VERSION ""

NS_ :

BS_:

BU_: VCU_LE CHUD_LE VKM_LE RCRM_LE VPM_LE EDI_LE V2V_LE TCP_LE CSM_LE UHP_Low_LE TouchPad_LE RSE_LE RSC_LE RSA_LE PDIM_LE OTIM_LE ICS_LE LVMPC_LE LVMNav_LE DVB_T_LE ONSTAR_LE HUD_LE IPC_LE RadioHead_LE CHM_LE Dummy_LE CGM_LE AMP_LE

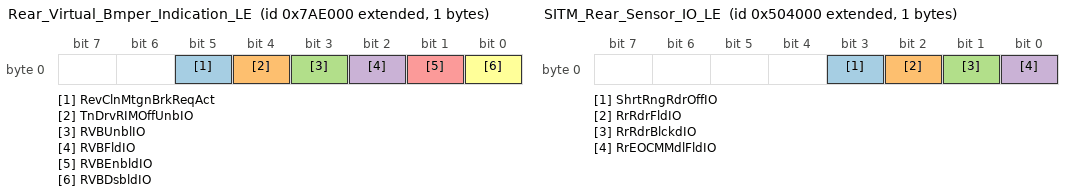
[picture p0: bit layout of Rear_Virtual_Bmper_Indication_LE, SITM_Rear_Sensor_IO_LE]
BO_ 2155536384 Rear_Virtual_Bmper_Indication_LE: 1 CGM_LE
 SG_ RevClnMtgnBrkReqAct : 5|1@0+ (1,0) [0|1] ""  Dummy_LE
 SG_ TnDrvRIMOffUnbIO : 4|1@0+ (1,0) [0|1] ""  VCU_LE,IPC_LE
 SG_ RVBUnblIO : 3|1@0+ (1,0) [0|1] ""  VCU_LE,IPC_LE
 SG_ RVBFldIO : 2|1@0+ (1,0) [0|1] ""  VCU_LE,IPC_LE
 SG_ RVBEnbldIO : 1|1@0+ (1,0) [0|1] ""  VCU_LE,IPC_LE
 SG_ RVBDsbldIO : 0|1@0+ (1,0) [0|1] ""  VCU_LE,IPC_LE

BO_ 2152742912 SITM_Rear_Sensor_IO_LE: 1 CGM_LE
 SG_ ShrtRngRdrOffIO : 3|1@0+ (1,0) [0|1] ""  CSM_LE,RadioHead_LE,VCU_LE,IPC_LE
 SG_ RrRdrFldIO : 2|1@0+ (1,0) [0|1] ""  CSM_LE,RadioHead_LE,VCU_LE,IPC_LE
 SG_ RrRdrBlckdIO : 1|1@0+ (1,0) [0|1] ""  CSM_LE,RadioHead_LE,VCU_LE,IPC_LE
 SG_ RrEOCMMdlFldIO : 0|1@0+ (1,0) [0|1] ""  CSM_LE,RadioHead_LE,VCU_LE,IPC_LE

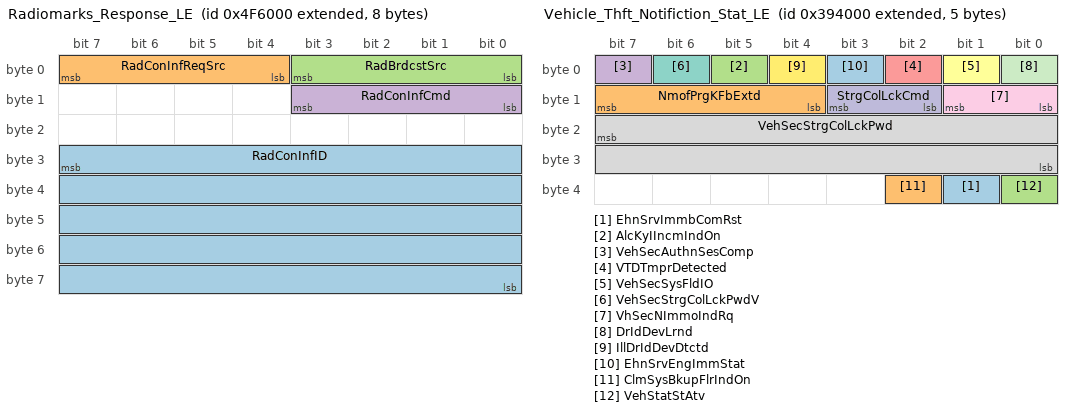
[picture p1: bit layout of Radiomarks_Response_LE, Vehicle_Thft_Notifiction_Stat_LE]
BO_ 2152685568 Radiomarks_Response_LE: 8 RadioHead_LE
 SG_ RadConInfID : 31|40@0+ (1,0) [0|1099511627775] ""  ONSTAR_LE
 SG_ RadConInfReqSrc : 7|4@0+ (1,0) [0|15] ""  ONSTAR_LE
 SG_ RadBrdcstSrc : 3|4@0+ (1,0) [0|15] ""  ONSTAR_LE
 SG_ RadConInfCmd : 11|4@0+ (1,0) [0|15] ""  ONSTAR_LE

BO_ 2151235584 Vehicle_Thft_Notifiction_Stat_LE: 5 CGM_LE
 SG_ EhnSrvImmbComRst : 33|1@0+ (1,0) [0|1] ""  TCP_LE,ONSTAR_LE
 SG_ NmofPrgKFbExtd : 15|4@0+ (1,0) [0|15] ""  VCU_LE,IPC_LE
 SG_ AlcKyIIncmIndOn : 5|1@0+ (1,0) [0|1] ""  Dummy_LE,VCU_LE,IPC_LE
 SG_ VehSecAuthnSesComp : 7|1@0+ (1,0) [0|1] ""  TCP_LE,ONSTAR_LE
 SG_ VTDTmprDetected : 2|1@0+ (1,0) [0|1] ""  TCP_LE,ONSTAR_LE
 SG_ VehSecSysFldIO : 1|1@0+ (1,0) [0|1] ""  VCU_LE,IPC_LE
 SG_ VehSecStrgColLckPwdV : 6|1@0+ (1,0) [0|1] ""  Dummy_LE
 SG_ VehSecStrgColLckPwd : 23|16@0+ (1,0) [0|65535] ""  Dummy_LE
 SG_ VhSecNImmoIndRq : 9|2@0+ (1,0) [0|3] ""  VCU_LE,IPC_LE
 SG_ StrgColLckCmd : 11|2@0+ (1,0) [0|3] ""  Dummy_LE
 SG_ DrIdDevLrnd : 0|1@0+ (1,0) [0|1] ""  TCP_LE,ONSTAR_LE
 SG_ IllDrIdDevDtctd : 4|1@0+ (1,0) [0|1] ""  TCP_LE,ONSTAR_LE
 SG_ EhnSrvEngImmStat : 3|1@0+ (1,0) [0|1] ""  TCP_LE,ONSTAR_LE
 SG_ ClmSysBkupFlrIndOn : 34|1@0+ (1,0) [0|1] ""  VCU_LE,IPC_LE
 SG_ VehStatStAtv : 32|1@0+ (1,0) [0|1] ""  Dummy_LE

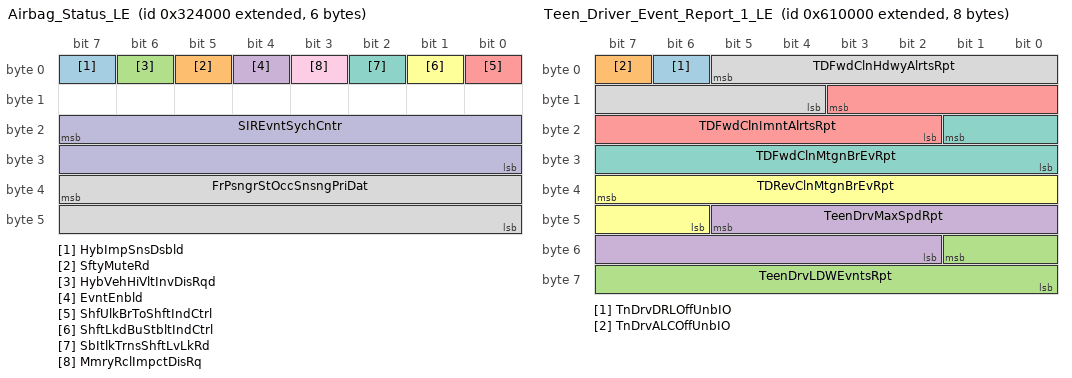
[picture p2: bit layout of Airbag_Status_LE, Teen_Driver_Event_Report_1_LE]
BO_ 2150776832 Airbag_Status_LE: 6 CGM_LE
 SG_ HybImpSnsDsbld : 7|1@0+ (1,0) [0|1] ""  Dummy_LE
 SG_ SftyMuteRd : 5|1@0+ (1,0) [0|1] ""  CSM_LE,VCU_LE,RadioHead_LE
 SG_ HybVehHiVltInvDisRqd : 6|1@0+ (1,0) [0|1] ""  Dummy_LE
 SG_ EvntEnbld : 4|1@0+ (1,0) [0|1] ""  Dummy_LE
 SG_ ShfUlkBrToShftIndCtrl : 0|1@0+ (1,0) [0|1] ""  VCU_LE,IPC_LE
 SG_ ShftLkdBuStbltIndCtrl : 1|1@0+ (1,0) [0|1] ""  VCU_LE,IPC_LE
 SG_ SbItlkTrnsShftLvLkRd : 2|1@0+ (1,0) [0|1] ""  Dummy_LE
 SG_ FrPsngrStOccSnsngPriDat : 39|16@0+ (1,0) [0|39321] ""  Dummy_LE
 SG_ MmryRclImpctDisRq : 3|1@0+ (1,0) [0|1] ""  TCP_LE,Dummy_LE,ONSTAR_LE
 SG_ SIREvntSychCntr : 23|16@0+ (1,0) [0|65535] ""  TCP_LE,ONSTAR_LE

BO_ 2155347968 HS_Indications_Slow_LE: 8 CGM_LE
 SG_ DrvrStPerfMdCsCrStVal : 62|3@0+ (1,0) [0|7] ""  VCU_LE,CSM_LE,RadioHead_LE
 SG_ DrvrStPerfMdCsStAvl : 63|1@0+ (1,0) [0|1] ""  VCU_LE,CSM_LE,RadioHead_LE
 SG_ ACCPerfMdCsCrStVal : 58|3@0+ (1,0) [0|7] ""  VCU_LE,CSM_LE,RadioHead_LE
 SG_ ACCPerfMdCsStAvl : 59|1@0+ (1,0) [0|1] ""  VCU_LE,CSM_LE,RadioHead_LE
 SG_ VehRollAngleV : 55|1@0+ (1,0) [0|1] ""  VCU_LE,IPC_LE
 SG_ VehRollAngle : 54|7@0+ (0.703125,-45) [-45|44.296875] "deg"  VCU_LE,IPC_LE
 SG_ ActVbnCtrlMlfIO : 0|1@0+ (1,0) [0|1] ""  VCU_LE,IPC_LE
 SG_ HillDesCtrlRedVehSpIO : 47|1@0+ (1,0) [0|1] ""  VCU_LE,IPC_LE
 SG_ FourWhlDrvIndReq : 42|3@0+ (1,0) [0|7] ""  CSM_LE,VCU_LE,IPC_LE
 SG_ PedtrnProtVDA : 35|1@0+ (1,0) [0|1] ""  CSM_LE,IPC_LE,VCU_LE,RadioHead_LE
 SG_ EngRecDwnshftIO : 43|1@0+ (1,0) [0|1] ""  CSM_LE,RadioHead_LE,VCU_LE,IPC_LE
 SG_ AppCltchAutSrtIO : 36|1@0+ (1,0) [0|1] ""  CSM_LE,RadioHead_LE,VCU_LE,IPC_LE
 SG_ CPSUnblIO : 32|1@0+ (1,0) [0|1] ""  CSM_LE,RadioHead_LE,VCU_LE,IPC_LE
 SG_ StBltTgtSetAvl : 37|1@0+ (1,0) [0|1] ""  CSM_LE,VCU_LE,RadioHead_LE
 SG_ StBltTgtCrtSetVal : 46|3@0+ (1,0) [0|7] ""  CSM_LE,VCU_LE,RadioHead_LE
 SG_ PedtrnProtSysDisbld : 34|1@0+ (1,0) [0|1] ""  CSM_LE,IPC_LE,VCU_LE,RadioHead_LE
 SG_ PedtrnProtSysDpl : 1|1@0+ (1,0) [0|1] ""  CSM_LE,IPC_LE,VCU_LE,RadioHead_LE
 SG_ SrvPedtrnProtSysIO : 33|1@0+ (1,0) [0|1] ""  CSM_LE,IPC_LE,VCU_LE,RadioHead_LE
 SG_ CPSOffIO : 31|1@0+ (1,0) [0|1] ""  CSM_LE,RadioHead_LE,VCU_LE,IPC_LE
 SG_ SecAxlTmpInhIO : 24|1@0+ (1,0) [0|1] ""  CSM_LE,RadioHead_LE,VCU_LE,IPC_LE
 SG_ CPSFldIO : 30|1@0+ (1,0) [0|1] ""  CSM_LE,RadioHead_LE,VCU_LE,IPC_LE
 SG_ CPSAlrtOnlIO : 25|1@0+ (1,0) [0|1] ""  CSM_LE,RadioHead_LE,VCU_LE,IPC_LE
 SG_ RrAxlTmpInhIO : 23|1@0+ (1,0) [0|1] ""  CSM_LE,RadioHead_LE,VCU_LE,IPC_LE
 SG_ TirePrsLowIO : 2|1@0+ (1,0) [0|1] ""  CSM_LE,RadioHead_LE,VCU_LE,IPC_LE
 SG_ EPBSysStatIndReq : 27|2@0+ (1,0) [0|3] ""  CSM_LE,RadioHead_LE,VCU_LE,IPC_LE
 SG_ EngOilStrvtnIO : 5|1@0+ (1,0) [0|1] ""  CSM_LE,RadioHead_LE,VCU_LE,IPC_LE
 SG_ SrvSuspSysIO : 12|1@0+ (1,0) [0|1] ""  CSM_LE,RadioHead_LE,VCU_LE,IPC_LE
 SG_ ServAdpCrsCtrlIndOn : 11|1@0+ (1,0) [0|1] ""  CSM_LE,TCP_LE,ONSTAR_LE,RadioHead_LE,VCU_LE,IPC_LE
 SG_ EngRecmndUpshftIO : 10|1@0+ (1,0) [0|1] ""  CSM_LE,RadioHead_LE,VCU_LE,IPC_LE
 SG_ BrkSysMalFuncIndOn : 15|1@0+ (1,0) [0|1] ""  CSM_LE,RadioHead_LE,VCU_LE,IPC_LE
 SG_ SecAxlNonEmMalfIO : 6|1@0+ (1,0) [0|1] ""  CSM_LE,RadioHead_LE,VCU_LE,IPC_LE
 SG_ BrkFldLvlLw : 7|1@0+ (1,0) [0|1] ""  CSM_LE,TCP_LE,ONSTAR_LE,RadioHead_LE,VCU_LE,IPC_LE
 SG_ ACCUnavlbleDTWthrIO : 3|1@0+ (1,0) [0|1] ""  CSM_LE,RadioHead_LE,VCU_LE,IPC_LE
 SG_ ACCTmpUnavlbleIO : 9|1@0+ (1,0) [0|1] ""  CSM_LE,RadioHead_LE,VCU_LE,IPC_LE
 SG_ EngEmsRelMalfIndReq : 18|3@0+ (1,0) [0|7] ""  CSM_LE,RadioHead_LE,VCU_LE,IPC_LE
 SG_ DrShftCntrlReqDndIO : 20|1@0+ (1,0) [0|1] ""  CSM_LE,RadioHead_LE,VCU_LE,IPC_LE
 SG_ BrkPadWrnIO : 13|1@0+ (1,0) [0|1] ""  CSM_LE,TCP_LE,ONSTAR_LE,RadioHead_LE,VCU_LE,IPC_LE
 SG_ RrAxlMalfIO : 19|1@0+ (1,0) [0|1] ""  CSM_LE,RadioHead_LE,VCU_LE,IPC_LE
 SG_ EPBSysWrnIndReq : 29|2@0+ (1,0) [0|3] ""  CSM_LE,RadioHead_LE,VCU_LE,IPC_LE
 SG_ CompOvrhtIndOn : 21|1@0+ (1,0) [0|1] ""  CSM_LE,RadioHead_LE,VCU_LE,IPC_LE
 SG_ BrkFldLvlLwV : 4|1@0+ (1,0) [0|1] ""  CSM_LE,TCP_LE,ONSTAR_LE,RadioHead_LE,VCU_LE,IPC_LE
 SG_ ACCSnsClnRqdIO : 8|1@0+ (1,0) [0|1] ""  CSM_LE,RadioHead_LE,VCU_LE,IPC_LE
 SG_ TrnsSkpShftIO : 22|1@0+ (1,0) [0|1] ""  CSM_LE,RadioHead_LE,VCU_LE,IPC_LE

BO_ 2155585536 MSB_Customization_Setting_Req_LE: 1 RadioHead_LE
 SG_ StBltTgtCSRq : 2|3@0+ (1,0) [0|7] ""  CGM_LE

BO_ 2159173632 ODI_IPC_2_CenterStack_LE: 8 IPC_LE
 SG_ ODI_IPC2CntrStck : 7|64@0+ (1,0) [0|1.84467440737096E+019] ""  CSM_LE,VCU_LE,RadioHead_LE

BO_ 2159165440 ODI_CenterStack_2_IPC_LE: 8 RadioHead_LE
 SG_ ODI_CntrStck2IPC : 7|64@0+ (1,0) [0|1.84467440737096E+019] ""  VCU_LE,IPC_LE

BO_ 2153840640 Teen_Driver_Event_Report_1_LE: 8 CGM_LE
 SG_ TnDrvDRLOffUnbIO : 6|1@0+ (1,0) [0|1] ""  VCU_LE,IPC_LE
 SG_ TnDrvALCOffUnbIO : 7|1@0+ (1,0) [0|1] ""  VCU_LE,IPC_LE
 SG_ TeenDrvLDWEvntsRpt : 49|10@0+ (1,0) [0|1023] "counts"  VCU_LE,CSM_LE,RadioHead_LE
 SG_ TeenDrvMaxSpdRpt : 45|12@0+ (0.0625,0) [0|255.9375] "km/h"  VCU_LE,CSM_LE,RadioHead_LE
 SG_ TDFwdClnImntAlrtsRpt : 11|10@0+ (1,0) [0|1023] "counts"  VCU_LE,CSM_LE,RadioHead_LE
 SG_ TDRevClnMtgnBrEvRpt : 39|10@0+ (1,0) [0|1023] "counts"  VCU_LE,CSM_LE,RadioHead_LE
 SG_ TDFwdClnMtgnBrEvRpt : 17|10@0+ (1,0) [0|1023] "counts"  VCU_LE,CSM_LE,RadioHead_LE
 SG_ TDFwdClnHdwyAlrtsRpt : 5|10@0+ (1,0) [0|1023] "counts"  VCU_LE,CSM_LE,RadioHead_LE

BO_ 2154094592 Adjustable_Pedal_Motion_Inh_LE: 8 CGM_LE
 SG_ IntDimSeldClrTypStVal : 12|5@0+ (1,0) [0|31] ""  VCU_LE,CSM_LE,RadioHead_LE
 SG_ IntDimSeldAnmTypStVal : 4|4@0+ (1,0) [0|15] ""  VCU_LE,CSM_LE,RadioHead_LE
 SG_ IDCTA_ClrTyp30Avl : 56|1@0+ (1,0) [0|1] ""  VCU_LE,CSM_LE,RadioHead_LE
 SG_ IDCTA_ClrTyp29Avl : 57|1@0+ (1,0) [0|1] ""  VCU_LE,CSM_LE,RadioHead_LE
 SG_ IDCTA_ClrTyp28Avl : 58|1@0+ (1,0) [0|1] ""  VCU_LE,CSM_LE,RadioHead_LE
 SG_ IDCTA_ClrTyp27Avl : 59|1@0+ (1,0) [0|1] ""  VCU_LE,CSM_LE,RadioHead_LE
 SG_ IDCTA_ClrTyp26Avl : 60|1@0+ (1,0) [0|1] ""  VCU_LE,CSM_LE,RadioHead_LE
 SG_ IDCTA_ClrTyp25Avl : 61|1@0+ (1,0) [0|1] ""  VCU_LE,CSM_LE,RadioHead_LE
 SG_ IDCTA_ClrTyp24Avl : 62|1@0+ (1,0) [0|1] ""  VCU_LE,CSM_LE,RadioHead_LE
 SG_ IDCTA_ClrTyp23Avl : 63|1@0+ (1,0) [0|1] ""  VCU_LE,CSM_LE,RadioHead_LE
 SG_ IDCTA_ClrTyp22Avl : 48|1@0+ (1,0) [0|1] ""  VCU_LE,CSM_LE,RadioHead_LE
 SG_ IDCTA_ClrTyp21Avl : 49|1@0+ (1,0) [0|1] ""  VCU_LE,CSM_LE,RadioHead_LE
 SG_ IDCTA_ClrTyp20Avl : 50|1@0+ (1,0) [0|1] ""  VCU_LE,CSM_LE,RadioHead_LE
 SG_ IDCTA_ClrTyp19Avl : 51|1@0+ (1,0) [0|1] ""  VCU_LE,CSM_LE,RadioHead_LE
 SG_ IDCTA_ClrTyp18Avl : 52|1@0+ (1,0) [0|1] ""  VCU_LE,CSM_LE,RadioHead_LE
 SG_ IDCTA_ClrTyp17Avl : 53|1@0+ (1,0) [0|1] ""  VCU_LE,CSM_LE,RadioHead_LE
 SG_ IDCTA_ClrTyp16Avl : 54|1@0+ (1,0) [0|1] ""  VCU_LE,CSM_LE,RadioHead_LE
 SG_ IDCTA_ClrTyp15Avl : 55|1@0+ (1,0) [0|1] ""  VCU_LE,CSM_LE,RadioHead_LE
 SG_ IDCTA_ClrTyp14Avl : 40|1@0+ (1,0) [0|1] ""  VCU_LE,CSM_LE,RadioHead_LE
 SG_ IDCTA_ClrTyp13Avl : 41|1@0+ (1,0) [0|1] ""  VCU_LE,CSM_LE,RadioHead_LE
 SG_ IDCTA_ClrTyp12Avl : 42|1@0+ (1,0) [0|1] ""  VCU_LE,CSM_LE,RadioHead_LE
 SG_ IDCTA_ClrTyp11Avl : 43|1@0+ (1,0) [0|1] ""  VCU_LE,CSM_LE,RadioHead_LE
 SG_ IDCTA_ClrTyp10Avl : 44|1@0+ (1,0) [0|1] ""  VCU_LE,CSM_LE,RadioHead_LE
 SG_ IDCTA_ClrTyp9Avl : 45|1@0+ (1,0) [0|1] ""  VCU_LE,CSM_LE,RadioHead_LE
 SG_ IDCTA_ClrTyp8Avl : 46|1@0+ (1,0) [0|1] ""  VCU_LE,CSM_LE,RadioHead_LE
 SG_ IDCTA_ClrTyp7Avl : 47|1@0+ (1,0) [0|1] ""  VCU_LE,CSM_LE,RadioHead_LE
 SG_ IDCTA_ClrTyp6Avl : 32|1@0+ (1,0) [0|1] ""  VCU_LE,CSM_LE,RadioHead_LE
 SG_ IDCTA_ClrTyp5Avl : 33|1@0+ (1,0) [0|1] ""  VCU_LE,CSM_LE,RadioHead_LE
 SG_ IDCTA_ClrTyp4Avl : 34|1@0+ (1,0) [0|1] ""  VCU_LE,CSM_LE,RadioHead_LE
 SG_ IDCTA_ClrTyp3Avl : 35|1@0+ (1,0) [0|1] ""  VCU_LE,CSM_LE,RadioHead_LE
 SG_ IDCTA_ClrTyp2Avl : 36|1@0+ (1,0) [0|1] ""  VCU_LE,CSM_LE,RadioHead_LE
 SG_ IDCTA_ClrTyp1Avl : 37|1@0+ (1,0) [0|1] ""  VCU_LE,CSM_LE,RadioHead_LE
 SG_ IDCTA_OffAvl : 38|1@0+ (1,0) [0|1] ""  VCU_LE,CSM_LE,RadioHead_LE
 SG_ IDATA_AnmTyp14Avl : 24|1@0+ (1,0) [0|1] ""  VCU_LE,CSM_LE,RadioHead_LE
 SG_ IDATA_AnmTyp13Avl : 25|1@0+ (1,0) [0|1] ""  VCU_LE,CSM_LE,RadioHead_LE
 SG_ IDATA_AnmTyp12Avl : 26|1@0+ (1,0) [0|1] ""  VCU_LE,CSM_LE,RadioHead_LE
 SG_ IDATA_AnmTyp11Avl : 27|1@0+ (1,0) [0|1] ""  VCU_LE,CSM_LE,RadioHead_LE
 SG_ IDATA_AnmTyp10Avl : 28|1@0+ (1,0) [0|1] ""  VCU_LE,CSM_LE,RadioHead_LE
 SG_ IDATA_AnmTyp9Avl : 29|1@0+ (1,0) [0|1] ""  VCU_LE,CSM_LE,RadioHead_LE
 SG_ IDATA_AnmTyp8Avl : 30|1@0+ (1,0) [0|1] ""  VCU_LE,CSM_LE,RadioHead_LE
 SG_ IDATA_AnmTyp7Avl : 31|1@0+ (1,0) [0|1] ""  VCU_LE,CSM_LE,RadioHead_LE
 SG_ IDATA_AnmTyp6Avl : 16|1@0+ (1,0) [0|1] ""  VCU_LE,CSM_LE,RadioHead_LE
 SG_ IDATA_AnmTyp5Avl : 17|1@0+ (1,0) [0|1] ""  VCU_LE,CSM_LE,RadioHead_LE
 SG_ IDATA_AnmTyp4Avl : 18|1@0+ (1,0) [0|1] ""  VCU_LE,CSM_LE,RadioHead_LE
 SG_ IDATA_AnmTyp3Avl : 19|1@0+ (1,0) [0|1] ""  VCU_LE,CSM_LE,RadioHead_LE
 SG_ IDATA_AnmTyp2Avl : 20|1@0+ (1,0) [0|1] ""  VCU_LE,CSM_LE,RadioHead_LE
 SG_ IDATA_AnmTyp1Avl : 21|1@0+ (1,0) [0|1] ""  VCU_LE,CSM_LE,RadioHead_LE
 SG_ IDATA_OffAvl : 22|1@0+ (1,0) [0|1] ""  VCU_LE,CSM_LE,RadioHead_LE
 SG_ AdjPdlMotInhbtd : 0|1@0+ (1,0) [0|1] ""  Dummy_LE

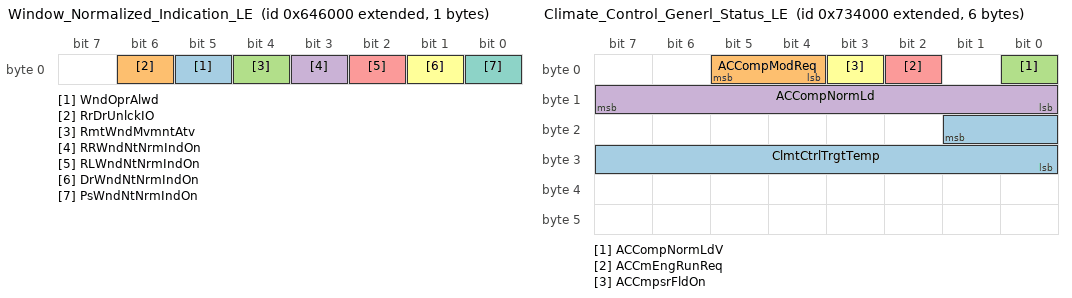
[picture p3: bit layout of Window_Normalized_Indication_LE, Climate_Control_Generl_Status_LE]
BO_ 2154061824 Window_Normalized_Indication_LE: 1 CGM_LE
 SG_ WndOprAlwd : 5|1@0+ (1,0) [0|1] ""  Dummy_LE
 SG_ RrDrUnlckIO : 6|1@0+ (1,0) [0|1] ""  VCU_LE,IPC_LE
 SG_ RmtWndMvmntAtv : 4|1@0+ (1,0) [0|1] ""  Dummy_LE
 SG_ RRWndNtNrmIndOn : 3|1@0+ (1,0) [0|1] ""  VCU_LE,IPC_LE
 SG_ RLWndNtNrmIndOn : 2|1@0+ (1,0) [0|1] ""  VCU_LE,IPC_LE
 SG_ DrWndNtNrmIndOn : 1|1@0+ (1,0) [0|1] ""  VCU_LE,IPC_LE
 SG_ PsWndNtNrmIndOn : 0|1@0+ (1,0) [0|1] ""  VCU_LE,IPC_LE

BO_ 2155036672 Climate_Control_Generl_Status_LE: 6 CGM_LE
 SG_ ClmtCtrlTrgtTemp : 17|10@0+ (0.1,-10) [-10|92.3] "deg C"  CSM_LE,Dummy_LE
 SG_ ACCompModReq : 5|2@0+ (1,0) [0|3] ""  Dummy_LE
 SG_ ACCompNormLdV : 0|1@0+ (1,0) [0|1] ""  VCU_LE,CSM_LE,RadioHead_LE
 SG_ ACCompNormLd : 15|8@0+ (0.1,0) [0|25.5] "l/min"  VCU_LE,CSM_LE,RadioHead_LE
 SG_ ACCmEngRunReq : 2|1@0+ (1,0) [0|1] ""  Dummy_LE
 SG_ ACCmpsrFldOn : 3|1@0+ (1,0) [0|1] ""  Dummy_LE

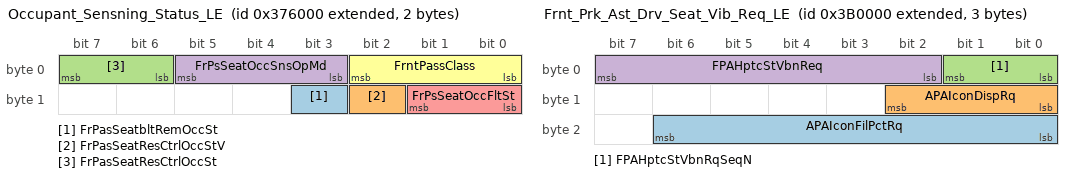
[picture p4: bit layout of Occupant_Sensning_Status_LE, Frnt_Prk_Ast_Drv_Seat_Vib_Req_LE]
BO_ 2151112704 Occupant_Sensning_Status_LE: 2 CGM_LE
 SG_ FrPasSeatbltRemOccSt : 11|1@0+ (1,0) [0|1] ""  CSM_LE,VCU_LE,RadioHead_LE
 SG_ FrPasSeatResCtrlOccStV : 10|1@0+ (1,0) [0|1] ""  CSM_LE,VCU_LE,RadioHead_LE
 SG_ FrPasSeatResCtrlOccSt : 7|2@0+ (1,0) [0|3] ""  CSM_LE,VCU_LE,RadioHead_LE
 SG_ FrPsSeatOccSnsOpMd : 5|3@0+ (1,0) [0|7] "N/A"  Dummy_LE
 SG_ FrPsSeatOccFltSt : 9|2@0+ (1,0) [0|3] "N/A"  CSM_LE,VCU_LE,RadioHead_LE
 SG_ FrntPassClass : 2|3@0+ (1,0) [0|7] ""  CSM_LE,VCU_LE,RadioHead_LE

BO_ 2150301696 HMI_Animation_Initiator_LE: 1 CGM_LE
 SG_ WlcAnmReq : 0|1@0+ (1,0) [0|1] ""  IPC_LE,VCU_LE,RadioHead_LE

BO_ 2158895104 ODI_CenterStack_2_RearSeat_LE: 8 RadioHead_LE
 SG_ ODI_CntrStck2RSD : 7|64@0+ (1,0) [0|1.84467440737096E+019] ""  RSC_LE,RSA_LE

BO_ 2151350272 Frnt_Prk_Ast_Drv_Seat_Vib_Req_LE: 3 CGM_LE
 SG_ APAIconFilPctRq : 22|7@0+ (1,0) [0|127] ""  VCU_LE,CSM_LE,RadioHead_LE,VPM_LE
 SG_ APAIconDispRq : 10|3@0+ (1,0) [0|7] ""  VCU_LE,CSM_LE,RadioHead_LE,VPM_LE
 SG_ FPAHptcStVbnRqSeqN : 1|2@0+ (1,0) [0|3] ""  Dummy_LE
 SG_ FPAHptcStVbnReq : 7|6@0+ (1,0) [0|63] ""  Dummy_LE

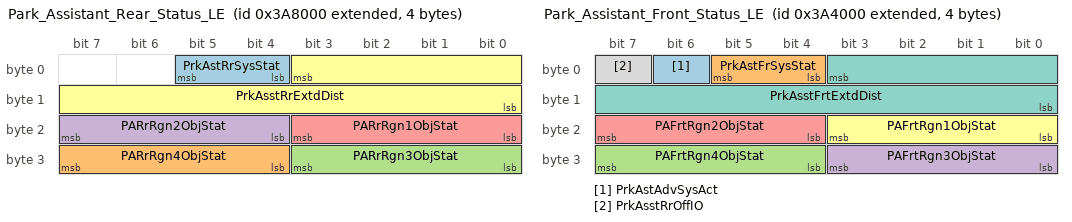
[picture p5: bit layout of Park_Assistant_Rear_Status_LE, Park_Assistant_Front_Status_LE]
BO_ 2151317504 Park_Assistant_Rear_Status_LE: 4 CGM_LE
 SG_ PrkAstRrSysStat : 5|2@0+ (1,0) [0|3] ""  TCP_LE,VPM_LE,ONSTAR_LE,CSM_LE,RadioHead_LE,VCU_LE,IPC_LE
 SG_ PARrRgn4ObjStat : 31|4@0+ (1,0) [0|15] ""  VPM_LE,CSM_LE,RadioHead_LE,VCU_LE,IPC_LE
 SG_ PARrRgn3ObjStat : 27|4@0+ (1,0) [0|15] ""  VPM_LE,CSM_LE,RadioHead_LE,VCU_LE,IPC_LE
 SG_ PARrRgn2ObjStat : 23|4@0+ (1,0) [0|15] ""  VPM_LE,CSM_LE,RadioHead_LE,VCU_LE,IPC_LE
 SG_ PARrRgn1ObjStat : 19|4@0+ (1,0) [0|15] ""  VPM_LE,CSM_LE,RadioHead_LE,VCU_LE,IPC_LE
 SG_ PrkAsstRrExtdDist : 3|12@0+ (0.01,0) [0|40.95] "m"  CSM_LE,RadioHead_LE,VCU_LE,IPC_LE

BO_ 2151301120 Park_Assistant_Front_Status_LE: 4 CGM_LE
 SG_ PrkAstAdvSysAct : 6|1@0+ (1,0) [0|1] ""  Dummy_LE
 SG_ PrkAstFrSysStat : 5|2@0+ (1,0) [0|3] ""  TCP_LE,ONSTAR_LE,CSM_LE,RadioHead_LE,VCU_LE,IPC_LE
 SG_ PAFrtRgn4ObjStat : 31|4@0+ (1,0) [0|15] ""  CSM_LE,RadioHead_LE,VCU_LE,IPC_LE
 SG_ PAFrtRgn3ObjStat : 27|4@0+ (1,0) [0|15] ""  CSM_LE,RadioHead_LE,VCU_LE,IPC_LE
 SG_ PAFrtRgn2ObjStat : 23|4@0+ (1,0) [0|15] ""  CSM_LE,RadioHead_LE,VCU_LE,IPC_LE
 SG_ PAFrtRgn1ObjStat : 19|4@0+ (1,0) [0|15] ""  CSM_LE,RadioHead_LE,VCU_LE,IPC_LE
 SG_ PrkAsstFrtExtdDist : 3|12@0+ (0.01,0) [0|40.95] "m"  VPM_LE,CSM_LE,RadioHead_LE,VCU_LE,IPC_LE
 SG_ PrkAsstRrOffIO : 7|1@0+ (1,0) [0|1] ""  VCU_LE,IPC_LE

BO_ 2152775680 Front_360_Camera_On_LE: 8 VPM_LE
 SG_ CrgBdVwLtCustSetAvl : 54|1@0+ (1,0) [0|1] ""  CGM_LE,VCU_LE,CSM_LE,RadioHead_LE
 SG_ TrlrMirVGlnCustSetVal : 51|2@0+ (1,0) [0|3] ""  CGM_LE,VCU_LE,CSM_LE,RadioHead_LE
 SG_ TrlrMirVGlnCustSetAvl : 55|1@0+ (1,0) [0|1] ""  CGM_LE,VCU_LE,CSM_LE,RadioHead_LE
 SG_ TrlrMirVEnCustSetVal : 30|2@0+ (1,0) [0|3] ""  CGM_LE,VCU_LE,CSM_LE,RadioHead_LE
 SG_ TrlrMirVEnCustSetAvl : 31|1@0+ (1,0) [0|1] ""  CGM_LE,VCU_LE,CSM_LE,RadioHead_LE
 SG_ TrlrArtcltnAnglCalStat : 62|2@0+ (1,0) [0|3] ""  VCU_LE,CSM_LE,RadioHead_LE,CGM_LE
 SG_ InvTrlrAx1CamRollAlgnd : 57|1@0+ (1,0) [0|1] ""  VCU_LE,CSM_LE,RadioHead_LE,CGM_LE
 SG_ InvTrlrAx1CamPtchAlgnd : 58|1@0+ (1,0) [0|1] ""  VCU_LE,CSM_LE,RadioHead_LE,CGM_LE
 SG_ InvTrlrAx1CamYAlgnd : 59|1@0+ (1,0) [0|1] ""  VCU_LE,CSM_LE,RadioHead_LE,CGM_LE
 SG_ InvTrlrAx1CamXAlgnd : 60|1@0+ (1,0) [0|1] ""  VCU_LE,CSM_LE,RadioHead_LE,CGM_LE
 SG_ RPDCA_Resrv3Avail : 17|1@0+ (1,0) [0|1] ""  VCU_LE,CSM_LE,RadioHead_LE,CGM_LE
 SG_ RPDCA_Resrv2Avail : 18|1@0+ (1,0) [0|1] ""  VCU_LE,CSM_LE,RadioHead_LE,CGM_LE
 SG_ RPDCA_Resrv1Avail : 19|1@0+ (1,0) [0|1] ""  VCU_LE,CSM_LE,RadioHead_LE,CGM_LE
 SG_ RPDCA_AlrtBrkAvail : 20|1@0+ (1,0) [0|1] ""  VCU_LE,CSM_LE,RadioHead_LE,CGM_LE
 SG_ RPDCA_AlrtAvail : 21|1@0+ (1,0) [0|1] ""  VCU_LE,CSM_LE,RadioHead_LE,CGM_LE
 SG_ RPDCA_OnAvail : 22|1@0+ (1,0) [0|1] ""  VCU_LE,CSM_LE,RadioHead_LE,CGM_LE
 SG_ RPDCA_OfAvail : 23|1@0+ (1,0) [0|1] ""  VCU_LE,CSM_LE,RadioHead_LE,CGM_LE
 SG_ JacknfDetRHapSReqSN : 47|2@0+ (1,0) [0|3] ""  CGM_LE
 SG_ JacknfDetRHapSReq : 45|6@0+ (1,0) [0|63] ""  CGM_LE
 SG_ JacknfDetLHapSReqSN : 39|2@0+ (1,0) [0|3] ""  CGM_LE
 SG_ JacknfDetLHapSReq : 37|6@0+ (1,0) [0|63] ""  CGM_LE
 SG_ JacknfDetCustSetVal : 53|2@0+ (1,0) [0|3] ""  CGM_LE,VCU_LE,CSM_LE,RadioHead_LE
 SG_ JacknfDetCustSetAvl : 63|1@0+ (1,0) [0|1] ""  CGM_LE,VCU_LE,CSM_LE,RadioHead_LE
 SG_ CrgBdVwLtCustSetVal : 49|2@0+ (1,0) [0|3] ""  CGM_LE,VCU_LE,CSM_LE,RadioHead_LE
 SG_ DispTrgdVidOn : 14|1@0+ (1,0) [0|1] ""  CGM_LE,VCU_LE,CSM_LE,RadioHead_LE
 SG_ a_360DegVidFetrPrsnt : 15|1@0+ (1,0) [0|1] ""  CGM_LE,VCU_LE,CSM_LE,RadioHead_LE
 SG_ TrgdVidRecFetrPrsnt : 7|1@0+ (1,0) [0|1] ""  VCU_LE,CSM_LE,RadioHead_LE,CGM_LE
 SG_ RrPdDetHptcStVbRq : 13|6@0+ (1,0) [0|63] "Pulse"  CGM_LE,Dummy_LE
 SG_ RrPdDetHptcStVbRqSeqN : 6|2@0+ (1,0) [0|3] ""  CGM_LE,Dummy_LE
 SG_ RrPedDetCstStAvl : 1|1@0+ (1,0) [0|1] ""  CGM_LE,VCU_LE,CSM_LE,RadioHead_LE
 SG_ RrPedDetCstStVal : 4|3@0+ (1,0) [0|7] ""  CGM_LE,VCU_LE,CSM_LE,RadioHead_LE
 SG_ DispFrt360CamOn : 0|1@0+ (1,0) [0|1] ""  CGM_LE,VCU_LE,CSM_LE,RadioHead_LE
 SG_ SurdVwLightgCsSetAvail : 27|1@0+ (1,0) [0|1] ""  CGM_LE,VCU_LE,CSM_LE,RadioHead_LE
 SG_ SurdVwLightgCsCurrSetVal : 26|3@0+ (1,0) [0|7] ""  CGM_LE,VCU_LE,CSM_LE,RadioHead_LE
 SG_ PudlLmpReqstd : 28|1@0+ (1,0) [0|1] ""  CGM_LE
 SG_ DispSmrtTwVidOn : 16|1@0+ (1,0) [0|1] ""  VCU_LE,CSM_LE,RadioHead_LE,CGM_LE

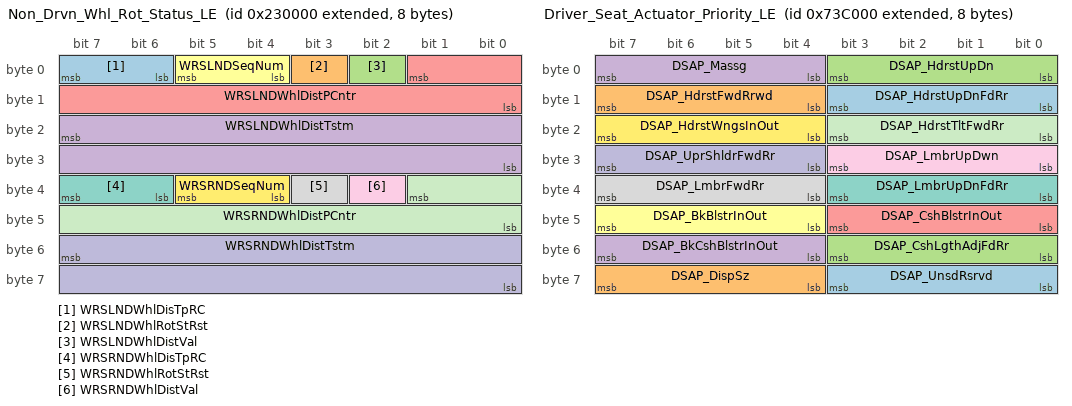
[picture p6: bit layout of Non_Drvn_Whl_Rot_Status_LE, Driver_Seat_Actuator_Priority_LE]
BO_ 2149777408 Non_Drvn_Whl_Rot_Status_LE: 8 CGM_LE
 SG_ WRSLNDWhlDisTpRC : 7|2@0+ (1,0) [0|3] "counts"  VPM_LE,VCU_LE,CSM_LE,RadioHead_LE
 SG_ WRSLNDWhlRotStRst : 3|1@0+ (1,0) [0|1] ""  VPM_LE,VCU_LE,CSM_LE,RadioHead_LE
 SG_ WRSLNDWhlDistVal : 2|1@0+ (1,0) [0|1] ""  VPM_LE,VCU_LE,CSM_LE,RadioHead_LE
 SG_ WRSLNDWhlDistTstm : 23|16@0+ (1,0) [0|65535] "counts"  VPM_LE,VCU_LE,CSM_LE,RadioHead_LE
 SG_ WRSLNDWhlDistPCntr : 1|10@0+ (1,0) [0|1023] "counts"  VPM_LE,VCU_LE,CSM_LE,RadioHead_LE
 SG_ WRSLNDSeqNum : 5|2@0+ (1,0) [0|3] "counts"  VPM_LE,VCU_LE,CSM_LE,RadioHead_LE
 SG_ WRSRNDWhlDisTpRC : 39|2@0+ (1,0) [0|3] "counts"  VPM_LE,VCU_LE,CSM_LE,RadioHead_LE
 SG_ WRSRNDWhlRotStRst : 35|1@0+ (1,0) [0|1] ""  VPM_LE,VCU_LE,CSM_LE,RadioHead_LE
 SG_ WRSRNDWhlDistVal : 34|1@0+ (1,0) [0|1] ""  VPM_LE,VCU_LE,CSM_LE,RadioHead_LE
 SG_ WRSRNDWhlDistTstm : 55|16@0+ (1,0) [0|65535] "counts"  VPM_LE,VCU_LE,CSM_LE,RadioHead_LE
 SG_ WRSRNDWhlDistPCntr : 33|10@0+ (1,0) [0|1023] "counts"  VPM_LE,VCU_LE,CSM_LE,RadioHead_LE
 SG_ WRSRNDSeqNum : 37|2@0+ (1,0) [0|3] "counts"  VPM_LE,VCU_LE,CSM_LE,RadioHead_LE

BO_ 2155069440 Driver_Seat_Actuator_Priority_LE: 8 CGM_LE
 SG_ DSAP_UnsdRsrvd : 59|4@0+ (1,0) [0|15] ""  VCU_LE,CSM_LE,RadioHead_LE
 SG_ DSAP_DispSz : 63|4@0+ (1,0) [0|15] ""  VCU_LE,CSM_LE,RadioHead_LE
 SG_ DSAP_CshLgthAdjFdRr : 51|4@0+ (1,0) [0|15] ""  VCU_LE,CSM_LE,RadioHead_LE
 SG_ DSAP_BkCshBlstrInOut : 55|4@0+ (1,0) [0|15] ""  VCU_LE,CSM_LE,RadioHead_LE
 SG_ DSAP_CshBlstrInOut : 43|4@0+ (1,0) [0|15] ""  VCU_LE,CSM_LE,RadioHead_LE
 SG_ DSAP_BkBlstrInOut : 47|4@0+ (1,0) [0|15] ""  VCU_LE,CSM_LE,RadioHead_LE
 SG_ DSAP_LmbrUpDnFdRr : 35|4@0+ (1,0) [0|15] ""  VCU_LE,CSM_LE,RadioHead_LE
 SG_ DSAP_LmbrFwdRr : 39|4@0+ (1,0) [0|15] ""  VCU_LE,CSM_LE,RadioHead_LE
 SG_ DSAP_LmbrUpDwn : 27|4@0+ (1,0) [0|15] ""  VCU_LE,CSM_LE,RadioHead_LE
 SG_ DSAP_UprShldrFwdRr : 31|4@0+ (1,0) [0|15] ""  VCU_LE,CSM_LE,RadioHead_LE
 SG_ DSAP_HdrstTltFwdRr : 19|4@0+ (1,0) [0|15] ""  VCU_LE,CSM_LE,RadioHead_LE
 SG_ DSAP_HdrstWngsInOut : 23|4@0+ (1,0) [0|15] ""  VCU_LE,CSM_LE,RadioHead_LE
 SG_ DSAP_HdrstUpDnFdRr : 11|4@0+ (1,0) [0|15] ""  VCU_LE,CSM_LE,RadioHead_LE
 SG_ DSAP_HdrstFwdRrwd : 15|4@0+ (1,0) [0|15] ""  VCU_LE,CSM_LE,RadioHead_LE
 SG_ DSAP_HdrstUpDn : 3|4@0+ (1,0) [0|15] ""  VCU_LE,CSM_LE,RadioHead_LE
 SG_ DSAP_Massg : 7|4@0+ (1,0) [0|15] ""  VCU_LE,CSM_LE,RadioHead_LE

BO_ 2152153088 Right_Rear_Seat_Display_Stats_LE: 6 CGM_LE
 SG_ RRSCDS_UnsdRsrvd : 42|3@0+ (1,0) [0|7] ""  RSE_LE,VCU_LE,CSM_LE,RadioHead_LE
 SG_ RRSCDS_DispReq : 43|1@0+ (1,0) [0|1] ""  RSE_LE,VCU_LE,CSM_LE,RadioHead_LE
 SG_ RRSCDS_DispSz : 45|2@0+ (1,0) [0|3] ""  RSE_LE,VCU_LE,CSM_LE,RadioHead_LE
 SG_ RRSCDS_CshLgAdjFdRr : 47|2@0+ (1,0) [0|3] ""  RSE_LE,VCU_LE,CSM_LE,RadioHead_LE
 SG_ RRSCDS_BkCshBlstInOt : 34|3@0+ (1,0) [0|7] ""  RSE_LE,VCU_LE,CSM_LE,RadioHead_LE
 SG_ RRSCDS_CshBlstrInOut : 36|2@0+ (1,0) [0|3] ""  RSE_LE,VCU_LE,CSM_LE,RadioHead_LE
 SG_ RRSCDS_BkBlstrInOut : 38|2@0+ (1,0) [0|3] ""  RSE_LE,VCU_LE,CSM_LE,RadioHead_LE
 SG_ RRSCDS_LmbrUDnFdRr : 25|3@0+ (1,0) [0|7] ""  RSE_LE,VCU_LE,CSM_LE,RadioHead_LE
 SG_ RRSCDS_LmbrFwdRr : 27|2@0+ (1,0) [0|3] ""  RSE_LE,VCU_LE,CSM_LE,RadioHead_LE
 SG_ RRSCDS_LmbrUpDwn : 29|2@0+ (1,0) [0|3] ""  RSE_LE,VCU_LE,CSM_LE,RadioHead_LE
 SG_ RRSCDS_UprShldrFdRr : 31|2@0+ (1,0) [0|3] ""  RSE_LE,VCU_LE,CSM_LE,RadioHead_LE
 SG_ RRSCDS_HdrstTltFwdRr : 17|2@0+ (1,0) [0|3] ""  RSE_LE,VCU_LE,CSM_LE,RadioHead_LE
 SG_ RRSCDS_HdrstWngInOt : 19|2@0+ (1,0) [0|3] ""  RSE_LE,VCU_LE,CSM_LE,RadioHead_LE
 SG_ RRSCDS_HdrstFdRrUDn : 22|3@0+ (1,0) [0|7] ""  RSE_LE,VCU_LE,CSM_LE,RadioHead_LE
 SG_ RRSCDS_HdrstFwdRrwd : 8|2@0+ (1,0) [0|3] ""  RSE_LE,VCU_LE,CSM_LE,RadioHead_LE
 SG_ RRSCDS_HdrstUpDn : 10|2@0+ (1,0) [0|3] ""  RSE_LE,VCU_LE,CSM_LE,RadioHead_LE
 SG_ RRSCDS_MassgIntsty : 13|3@0+ (1,0) [0|7] ""  RSE_LE,VCU_LE,CSM_LE,RadioHead_LE
 SG_ RRSCDS_MassgTyp : 1|4@0+ (1,0) [0|15] ""  RSE_LE,VCU_LE,CSM_LE,RadioHead_LE
 SG_ RRSCDS_Massg : 3|2@0+ (1,0) [0|3] ""  RSE_LE,VCU_LE,CSM_LE,RadioHead_LE

BO_ 2152136704 Right_Rear_Seat_Massage_LE: 8 CGM_LE
 SG_ RRSMP_UnsdRsrvd : 56|1@0+ (1,0) [0|1] ""  RSE_LE,VCU_LE,CSM_LE,RadioHead_LE
 SG_ RRSMP_MaxDispVal : 59|3@0+ (1,0) [0|7] ""  RSE_LE,VCU_LE,CSM_LE,RadioHead_LE
 SG_ RRSMP_Type15 : 63|4@0+ (1,0) [0|15] ""  RSE_LE,VCU_LE,CSM_LE,RadioHead_LE
 SG_ RRSMP_Type14 : 51|4@0+ (1,0) [0|15] ""  RSE_LE,VCU_LE,CSM_LE,RadioHead_LE
 SG_ RRSMP_Type13 : 55|4@0+ (1,0) [0|15] ""  RSE_LE,VCU_LE,CSM_LE,RadioHead_LE
 SG_ RRSMP_Type12 : 43|4@0+ (1,0) [0|15] ""  RSE_LE,VCU_LE,CSM_LE,RadioHead_LE
 SG_ RRSMP_Type11 : 47|4@0+ (1,0) [0|15] ""  RSE_LE,VCU_LE,CSM_LE,RadioHead_LE
 SG_ RRSMP_Type10 : 35|4@0+ (1,0) [0|15] ""  RSE_LE,VCU_LE,CSM_LE,RadioHead_LE
 SG_ RRSMP_Type9 : 39|4@0+ (1,0) [0|15] ""  RSE_LE,VCU_LE,CSM_LE,RadioHead_LE
 SG_ RRSMP_Type8 : 27|4@0+ (1,0) [0|15] ""  RSE_LE,VCU_LE,CSM_LE,RadioHead_LE
 SG_ RRSMP_Type7 : 31|4@0+ (1,0) [0|15] ""  RSE_LE,VCU_LE,CSM_LE,RadioHead_LE
 SG_ RRSMP_Type6 : 19|4@0+ (1,0) [0|15] ""  RSE_LE,VCU_LE,CSM_LE,RadioHead_LE
 SG_ RRSMP_Type5 : 23|4@0+ (1,0) [0|15] ""  RSE_LE,VCU_LE,CSM_LE,RadioHead_LE
 SG_ RRSMP_Type4 : 11|4@0+ (1,0) [0|15] ""  RSE_LE,VCU_LE,CSM_LE,RadioHead_LE
 SG_ RRSMP_Type3 : 15|4@0+ (1,0) [0|15] ""  RSE_LE,VCU_LE,CSM_LE,RadioHead_LE
 SG_ RRSMP_Type2 : 3|4@0+ (1,0) [0|15] ""  RSE_LE,VCU_LE,CSM_LE,RadioHead_LE
 SG_ RRSMP_Type1 : 7|4@0+ (1,0) [0|15] ""  RSE_LE,VCU_LE,CSM_LE,RadioHead_LE

BO_ 2155151360 Psngr_Seat_Massage_Priority_LE: 8 CGM_LE
 SG_ PSMP_UnsdRsrvd : 56|1@0+ (1,0) [0|1] ""  VCU_LE,CSM_LE,RadioHead_LE
 SG_ PSMP_MaxDispVal : 59|3@0+ (1,0) [0|7] ""  VCU_LE,CSM_LE,RadioHead_LE
 SG_ PSMP_Type15 : 63|4@0+ (1,0) [0|15] ""  VCU_LE,CSM_LE,RadioHead_LE
 SG_ PSMP_Type14 : 51|4@0+ (1,0) [0|15] ""  VCU_LE,CSM_LE,RadioHead_LE
 SG_ PSMP_Type13 : 55|4@0+ (1,0) [0|15] ""  VCU_LE,CSM_LE,RadioHead_LE
 SG_ PSMP_Type12 : 43|4@0+ (1,0) [0|15] ""  VCU_LE,CSM_LE,RadioHead_LE
 SG_ PSMP_Type11 : 47|4@0+ (1,0) [0|15] ""  VCU_LE,CSM_LE,RadioHead_LE
 SG_ PSMP_Type10 : 35|4@0+ (1,0) [0|15] ""  VCU_LE,CSM_LE,RadioHead_LE
 SG_ PSMP_Type9 : 39|4@0+ (1,0) [0|15] ""  VCU_LE,CSM_LE,RadioHead_LE
 SG_ PSMP_Type8 : 27|4@0+ (1,0) [0|15] ""  VCU_LE,CSM_LE,RadioHead_LE
 SG_ PSMP_Type7 : 31|4@0+ (1,0) [0|15] ""  VCU_LE,CSM_LE,RadioHead_LE
 SG_ PSMP_Type6 : 19|4@0+ (1,0) [0|15] ""  VCU_LE,CSM_LE,RadioHead_LE
 SG_ PSMP_Type5 : 23|4@0+ (1,0) [0|15] ""  VCU_LE,CSM_LE,RadioHead_LE
 SG_ PSMP_Type4 : 11|4@0+ (1,0) [0|15] ""  VCU_LE,CSM_LE,RadioHead_LE
 SG_ PSMP_Type3 : 15|4@0+ (1,0) [0|15] ""  VCU_LE,CSM_LE,RadioHead_LE
 SG_ PSMP_Type2 : 3|4@0+ (1,0) [0|15] ""  VCU_LE,CSM_LE,RadioHead_LE
 SG_ PSMP_Type1 : 7|4@0+ (1,0) [0|15] ""  VCU_LE,CSM_LE,RadioHead_LE

BO_ 2155134976 Psngr_Seat_Control_Disp_Stat_LE: 6 CGM_LE
 SG_ PSCDS_UnsdRsrvd : 42|3@0+ (1,0) [0|7] ""  VCU_LE,CSM_LE,RadioHead_LE
 SG_ PSCDS_DispReq : 43|1@0+ (1,0) [0|1] ""  VCU_LE,CSM_LE,RadioHead_LE
 SG_ PSCDS_DispSz : 45|2@0+ (1,0) [0|3] ""  VCU_LE,CSM_LE,RadioHead_LE
 SG_ PSCDS_CshLgAdjFdRr : 47|2@0+ (1,0) [0|3] ""  VCU_LE,CSM_LE,RadioHead_LE
 SG_ PSCDS_BkCshBlstInOt : 34|3@0+ (1,0) [0|7] ""  VCU_LE,CSM_LE,RadioHead_LE
 SG_ PSCDS_CshBlstrInOut : 36|2@0+ (1,0) [0|3] ""  VCU_LE,CSM_LE,RadioHead_LE
 SG_ PSCDS_BkBlstrInOut : 38|2@0+ (1,0) [0|3] ""  VCU_LE,CSM_LE,RadioHead_LE
 SG_ PSCDS_LmbrUDnFdRr : 25|3@0+ (1,0) [0|7] ""  VCU_LE,CSM_LE,RadioHead_LE
 SG_ PSCDS_LmbrFwdRr : 27|2@0+ (1,0) [0|3] ""  VCU_LE,CSM_LE,RadioHead_LE
 SG_ PSCDS_LmbrUpDwn : 29|2@0+ (1,0) [0|3] ""  VCU_LE,CSM_LE,RadioHead_LE
 SG_ PSCDS_UprShldrFdRr : 31|2@0+ (1,0) [0|3] ""  VCU_LE,CSM_LE,RadioHead_LE
 SG_ PSCDS_HdrstTltFwdRr : 17|2@0+ (1,0) [0|3] ""  VCU_LE,CSM_LE,RadioHead_LE
 SG_ PSCDS_HdrstWngInOt : 19|2@0+ (1,0) [0|3] ""  VCU_LE,CSM_LE,RadioHead_LE
 SG_ PSCDS_HdrstUDnFdRr : 22|3@0+ (1,0) [0|7] ""  VCU_LE,CSM_LE,RadioHead_LE
 SG_ PSCDS_HdrstFwdRrwd : 8|2@0+ (1,0) [0|3] ""  VCU_LE,CSM_LE,RadioHead_LE
 SG_ PSCDS_HdrstUpDn : 10|2@0+ (1,0) [0|3] ""  VCU_LE,CSM_LE,RadioHead_LE
 SG_ PSCDS_MassgIntsty : 13|3@0+ (1,0) [0|7] ""  VCU_LE,CSM_LE,RadioHead_LE
 SG_ PSCDS_MassgTyp : 1|4@0+ (1,0) [0|15] ""  VCU_LE,CSM_LE,RadioHead_LE
 SG_ PSCDS_Massg : 3|2@0+ (1,0) [0|3] ""  VCU_LE,CSM_LE,RadioHead_LE
 SG_ PsngrSetRrwdMvmnt : 6|3@0+ (1,0) [0|7] ""  Dummy_LE

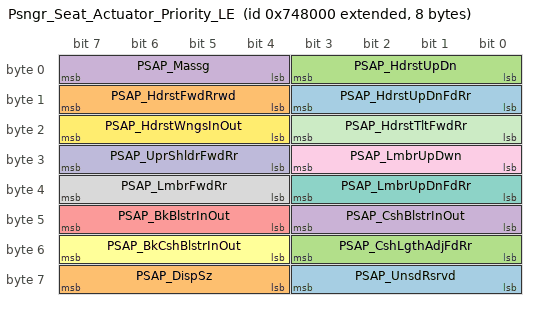
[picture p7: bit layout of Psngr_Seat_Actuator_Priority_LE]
BO_ 2155118592 Psngr_Seat_Actuator_Priority_LE: 8 CGM_LE
 SG_ PSAP_UnsdRsrvd : 59|4@0+ (1,0) [0|15] ""  VCU_LE,CSM_LE,RadioHead_LE
 SG_ PSAP_DispSz : 63|4@0+ (1,0) [0|15] ""  VCU_LE,CSM_LE,RadioHead_LE
 SG_ PSAP_CshLgthAdjFdRr : 51|4@0+ (1,0) [0|15] ""  VCU_LE,CSM_LE,RadioHead_LE
 SG_ PSAP_CshBlstrInOut : 43|4@0+ (1,0) [0|15] ""  VCU_LE,CSM_LE,RadioHead_LE
 SG_ PSAP_BkBlstrInOut : 47|4@0+ (1,0) [0|15] ""  VCU_LE,CSM_LE,RadioHead_LE
 SG_ PSAP_BkCshBlstrInOut : 55|4@0+ (1,0) [0|15] ""  VCU_LE,CSM_LE,RadioHead_LE
 SG_ PSAP_LmbrUpDnFdRr : 35|4@0+ (1,0) [0|15] ""  VCU_LE,CSM_LE,RadioHead_LE
 SG_ PSAP_LmbrFwdRr : 39|4@0+ (1,0) [0|15] ""  VCU_LE,CSM_LE,RadioHead_LE
 SG_ PSAP_LmbrUpDwn : 27|4@0+ (1,0) [0|15] ""  VCU_LE,CSM_LE,RadioHead_LE
 SG_ PSAP_UprShldrFwdRr : 31|4@0+ (1,0) [0|15] ""  VCU_LE,CSM_LE,RadioHead_LE
 SG_ PSAP_HdrstTltFwdRr : 19|4@0+ (1,0) [0|15] ""  VCU_LE,CSM_LE,RadioHead_LE
 SG_ PSAP_HdrstWngsInOut : 23|4@0+ (1,0) [0|15] ""  VCU_LE,CSM_LE,RadioHead_LE
 SG_ PSAP_HdrstUpDnFdRr : 11|4@0+ (1,0) [0|15] ""  VCU_LE,CSM_LE,RadioHead_LE
 SG_ PSAP_HdrstFwdRrwd : 15|4@0+ (1,0) [0|15] ""  VCU_LE,CSM_LE,RadioHead_LE
 SG_ PSAP_HdrstUpDn : 3|4@0+ (1,0) [0|15] ""  VCU_LE,CSM_LE,RadioHead_LE
 SG_ PSAP_Massg : 7|4@0+ (1,0) [0|15] ""  VCU_LE,CSM_LE,RadioHead_LE

BO_TX_BU_ 2152685568 : VCU_LE,RadioHead_LE;
BO_TX_BU_ 2155585536 : VCU_LE,CSM_LE,RadioHead_LE;
BO_TX_BU_ 2159173632 : VCU_LE,IPC_LE;
BO_TX_BU_ 2159165440 : CSM_LE,VCU_LE,RadioHead_LE;
BO_TX_BU_ 2158895104 : CSM_LE,VCU_LE,RadioHead_LE;
CM_ SG_ 2151112704 FrPsSeatOccSnsOpMd "TBD";
CM_ SG_ 2151112704 FrPsSeatOccFltSt "TBD";
CM_ SG_ 2151317504 PARrRgn4ObjStat "Regions are segments across the width of the vehicle (X coordinate).  Zones are distances from the vehicle (Y coordinate).";
CM_ SG_ 2151317504 PARrRgn3ObjStat "Regions are segments across the width of the vehicle (X coordinate).  Zones are distances from the vehicle (Y coordinate).";
CM_ SG_ 2151317504 PARrRgn2ObjStat "Regions are segments across the width of the vehicle (X coordinate).  Zones are distances from the vehicle (Y coordinate).";
CM_ SG_ 2151317504 PARrRgn1ObjStat "Regions are segments across the width of the vehicle (X coordinate).  Zones are distances from the vehicle (Y coordinate).";
CM_ SG_ 2151301120 PAFrtRgn4ObjStat "Regions are segments across the width of the vehicle (X coordinate).  Zones are distances from the vehicle (Y coordinate).";
CM_ SG_ 2151301120 PAFrtRgn3ObjStat "Regions are segments across the width of the vehicle (X coordinate).  Zones are distances from the vehicle (Y coordinate).";
CM_ SG_ 2151301120 PAFrtRgn2ObjStat "Regions are segments across the width of the vehicle (X coordinate).  Zones are distances from the vehicle (Y coordinate).";
CM_ SG_ 2151301120 PAFrtRgn1ObjStat "Regions are segments across the width of the vehicle (X coordinate).  Zones are distances from the vehicle (Y coordinate).";
BA_DEF_ SG_  "VNSigPrimaryTriggering" ENUM  "No","Yes","DLCLS","DLCHS","DLCCE","DLCFO";
BA_DEF_ SG_  "VNSigRemoteDiagnostics" ENUM  "No","Yes","DLCLS","DLCHS","DLCCE","DLCFO";
BA_DEF_ SG_  "VNSigInfotainment" ENUM  "No","Yes","DLCLS","DLCHS","DLCCE","DLCFO";
BA_DEF_ SG_  "VNSigParkedVehicle" ENUM  "No","Yes","DLCLS","DLCHS","DLCCE","DLCFO";
BA_DEF_ SG_  "VNSigIntermediate" ENUM  "No","Yes","DLCLS","DLCHS","DLCCE","DLCFO";
BA_DEF_ SG_  "VNSigUnused_4" ENUM  "No","Yes","DLCLS","DLCHS","DLCCE","DLCFO";
BA_DEF_ SG_  "SignalType" STRING ;
BA_DEF_ SG_  "PacketOrder" INT 0 65535;
BA_DEF_ SG_  "SignalLongName" STRING ;
BA_DEF_ SG_  "GenSigStartValue" INT 0 65535;
BA_DEF_ SG_  "VNSigDiagnostic" ENUM  "No","Yes","DLCLS","DLCHS","DLCCE","DLCFO";
BA_DEF_ SG_  "VNSigAllNodes" ENUM  "No","Yes","DLCLS","DLCHS","DLCCE","DLCFO";
BA_DEF_ SG_  "GenSigDeltaValue" INT 0 0;
BA_DEF_ SG_  "GenSigSendType" ENUM  "not used","not used","not used","not used","not used","not used","not used","NoSigSendType","not used","not used","OnAnyChange","OnChangeIfActive","OnDelta","DLCLS","DLCHS","DLCCE","DLCFO";
BA_DEF_ SG_  "GenSigSendOnInit" ENUM  "Not Initialized","Application","Handler","DLCLS","DLCHS","DLCCE","DLCFO";
BA_DEF_ BO_  "AppGenMsgCycleTime" INT 0 0;
BA_DEF_ BO_  "TpTxIndex" INT 0 99;
BA_DEF_ BO_  "GenMsgILSupport" ENUM  "No","Yes","DLCLS","DLCHS","DLCCE","DLCFO";
BA_DEF_ BO_  "TpApplType" STRING ;
BA_DEF_ BO_  "Prio" INT 0 7;
BA_DEF_ BO_  "MessageSubnet" ENUM  "LS","MS","HS","CE","PE","HV","FO","S1","HE","LE","HE2","DLCLS","DLCHS","DLCCE","DLCFO";
BA_DEF_ BO_  "GenMsgMandatoryToSupervision" ENUM  "No","Yes","DLCLS","DLCHS","DLCCE","DLCFO";
BA_DEF_ BO_  "DiagState" ENUM  "No","Yes","DLCLS","DLCHS","DLCCE","DLCFO";
BA_DEF_ BO_  "GenMsgStartDelayTime" INT 0 100000;
BA_DEF_ BO_  "GenMsgDelayTime" INT 0 100000;
BA_DEF_ BO_  "GenMsgCycleTime" INT 0 100000;
BA_DEF_ BO_  "GenMsgSendType" ENUM  "cyclicX","spontanX","cyclicIfActiveX","spontanWithDelay","cyclicAndSpontanX","cyclicAndSpontanWithDelay","spontanWithRepitition","cyclicIfActiveAndSpontanWD","DLCLS","DLCHS","DLCCE","DLCFO";
BA_DEF_ BO_  "DiagResponse" ENUM  "No","Yes","DLCLS","DLCHS","DLCCE","DLCFO";
BA_DEF_ BO_  "DiagRequest" ENUM  "No","Yes","DLCLS","DLCHS","DLCCE","DLCFO";
BA_DEF_ BO_  "NmMessage" ENUM  "No","Yes","DLCLS","DLCHS","DLCCE","DLCFO";
BA_DEF_REL_ BU_SG_REL_  "GenSigSuprvRespComment" STRING ;
BA_DEF_REL_ BU_SG_REL_  "GenSigVBitResp" ENUM  "No","Yes","DLCLS","DLCHS","DLCCE","DLCFO";
BA_DEF_REL_ BU_SG_REL_  "GenSigVBitRespComment" STRING ;
BA_DEF_REL_ BU_SG_REL_  "GenSigVDAFailComment" STRING ;
BA_DEF_REL_ BU_SG_REL_  "GenSigVDAFailResp" ENUM  "No","Yes","DLCLS","DLCHS","DLCCE","DLCFO";
BA_DEF_REL_ BU_SG_REL_  "GenSigRxStartValue" STRING ;
BA_DEF_REL_ BU_SG_REL_  "GenSigSuprvRespSubValue" INT 0 65535;
BA_DEF_REL_ BU_SG_REL_  "GenSigSuprvResp" ENUM  "None","Notify App","Substitute Default","DLCLS","DLCHS","DLCCE","DLCFO";
BA_DEF_REL_ BU_SG_REL_  "GenSigTimeoutMsg" HEX -2147483648 268435455;
BA_DEF_DEF_  "VNSigPrimaryTriggering" "No";
BA_DEF_DEF_  "VNSigRemoteDiagnostics" "No";
BA_DEF_DEF_  "VNSigInfotainment" "No";
BA_DEF_DEF_  "VNSigParkedVehicle" "No";
BA_DEF_DEF_  "VNSigIntermediate" "No";
BA_DEF_DEF_  "VNSigUnused_4" "No";
BA_DEF_DEF_  "SignalType" "";
BA_DEF_DEF_  "PacketOrder" 0;
BA_DEF_DEF_  "SignalLongName" "";
BA_DEF_DEF_  "GenSigStartValue" 0;
BA_DEF_DEF_  "VNSigDiagnostic" "No";
BA_DEF_DEF_  "VNSigAllNodes" "No";
BA_DEF_DEF_  "GenSigDeltaValue" 0;
BA_DEF_DEF_  "GenSigSendType" "NoSigSendType";
BA_DEF_DEF_  "GenSigSendOnInit" "Not Initialized";
BA_DEF_DEF_  "AppGenMsgCycleTime" 0;
BA_DEF_DEF_  "TpTxIndex" 0;
BA_DEF_DEF_  "GenMsgILSupport" "Yes";
BA_DEF_DEF_  "TpApplType" "";
BA_DEF_DEF_  "Prio" 4;
BA_DEF_DEF_  "MessageSubnet" "FO";
BA_DEF_DEF_  "GenMsgMandatoryToSupervision" "No";
BA_DEF_DEF_  "DiagState" "No";
BA_DEF_DEF_  "GenMsgStartDelayTime" 0;
BA_DEF_DEF_  "GenMsgDelayTime" 0;
BA_DEF_DEF_  "GenMsgCycleTime" 0;
BA_DEF_DEF_  "GenMsgSendType" "spontanX";
BA_DEF_DEF_  "DiagResponse" "No";
BA_DEF_DEF_  "DiagRequest" "No";
BA_DEF_DEF_  "NmMessage" "No";
BA_DEF_DEF_REL_ "GenSigSuprvRespComment" "";
BA_DEF_DEF_REL_ "GenSigVBitResp" "No";
BA_DEF_DEF_REL_ "GenSigVBitRespComment" "";
BA_DEF_DEF_REL_ "GenSigVDAFailComment" "";
BA_DEF_DEF_REL_ "GenSigVDAFailResp" "No";
BA_DEF_DEF_REL_ "GenSigRxStartValue" "";
BA_DEF_DEF_REL_ "GenSigSuprvRespSubValue" 0;
BA_DEF_DEF_REL_ "GenSigSuprvResp" "None";
BA_DEF_DEF_REL_ "GenSigTimeoutMsg" 0;
BA_ "MessageSubnet" BO_ 2155536384 9;
BA_ "GenMsgDelayTime" BO_ 2155536384 100;
BA_ "MessageSubnet" BO_ 2152742912 9;
BA_ "GenMsgDelayTime" BO_ 2152742912 100;
BA_ "MessageSubnet" BO_ 2152685568 9;
BA_ "GenMsgDelayTime" BO_ 2152685568 10;
BA_ "Prio" BO_ 2151235584 3;
BA_ "MessageSubnet" BO_ 2151235584 9;
BA_ "GenMsgDelayTime" BO_ 2151235584 100;
BA_ "MessageSubnet" BO_ 2150776832 9;
BA_ "GenMsgDelayTime" BO_ 2150776832 10;
BA_ "GenMsgCycleTime" BO_ 2150776832 2000;
BA_ "GenMsgSendType" BO_ 2150776832 0;
BA_ "MessageSubnet" BO_ 2155347968 9;
BA_ "GenMsgStartDelayTime" BO_ 2155347968 180;
BA_ "GenMsgCycleTime" BO_ 2155347968 250;
BA_ "GenMsgSendType" BO_ 2155347968 0;
BA_ "MessageSubnet" BO_ 2155585536 9;
BA_ "GenMsgDelayTime" BO_ 2155585536 100;
BA_ "MessageSubnet" BO_ 2159173632 9;
BA_ "GenMsgDelayTime" BO_ 2159173632 10;
BA_ "MessageSubnet" BO_ 2159165440 9;
BA_ "GenMsgDelayTime" BO_ 2159165440 10;
BA_ "MessageSubnet" BO_ 2153840640 9;
BA_ "GenMsgDelayTime" BO_ 2153840640 100;
BA_ "MessageSubnet" BO_ 2154094592 9;
BA_ "GenMsgDelayTime" BO_ 2154094592 100;
BA_ "MessageSubnet" BO_ 2154061824 9;
BA_ "GenMsgDelayTime" BO_ 2154061824 100;
BA_ "MessageSubnet" BO_ 2155036672 9;
BA_ "GenMsgDelayTime" BO_ 2155036672 100;
BA_ "GenMsgCycleTime" BO_ 2155036672 500;
BA_ "GenMsgSendType" BO_ 2155036672 0;
BA_ "MessageSubnet" BO_ 2151112704 9;
BA_ "GenMsgDelayTime" BO_ 2151112704 100;
BA_ "MessageSubnet" BO_ 2150301696 9;
BA_ "GenMsgDelayTime" BO_ 2150301696 100;
BA_ "MessageSubnet" BO_ 2158895104 9;
BA_ "GenMsgDelayTime" BO_ 2158895104 10;
BA_ "MessageSubnet" BO_ 2151350272 9;
BA_ "GenMsgDelayTime" BO_ 2151350272 100;
BA_ "MessageSubnet" BO_ 2151317504 9;
BA_ "GenMsgDelayTime" BO_ 2151317504 100;
BA_ "MessageSubnet" BO_ 2151301120 9;
BA_ "GenMsgDelayTime" BO_ 2151301120 100;
BA_ "MessageSubnet" BO_ 2152775680 9;
BA_ "GenMsgDelayTime" BO_ 2152775680 100;
BA_ "MessageSubnet" BO_ 2149777408 9;
BA_ "GenMsgStartDelayTime" BO_ 2149777408 140;
BA_ "GenMsgCycleTime" BO_ 2149777408 200;
BA_ "GenMsgSendType" BO_ 2149777408 0;
BA_ "MessageSubnet" BO_ 2155069440 9;
BA_ "GenMsgDelayTime" BO_ 2155069440 100;
BA_ "MessageSubnet" BO_ 2152153088 9;
BA_ "GenMsgDelayTime" BO_ 2152153088 100;
BA_ "MessageSubnet" BO_ 2152136704 9;
BA_ "GenMsgDelayTime" BO_ 2152136704 100;
BA_ "MessageSubnet" BO_ 2155151360 9;
BA_ "GenMsgDelayTime" BO_ 2155151360 100;
BA_ "MessageSubnet" BO_ 2155134976 9;
BA_ "GenMsgDelayTime" BO_ 2155134976 100;
BA_ "MessageSubnet" BO_ 2155118592 9;
BA_ "GenMsgDelayTime" BO_ 2155118592 100;
BA_ "GenSigSendType" SG_ 2155536384 RevClnMtgnBrkReqAct 10;
BA_ "SignalType" SG_ 2155536384 RevClnMtgnBrkReqAct "BLN";
BA_ "SignalLongName" SG_ 2155536384 RevClnMtgnBrkReqAct "Reverse Collision Mitigation Braking Request Active";
BA_ "VNSigAllNodes" SG_ 2155536384 RevClnMtgnBrkReqAct 1;
BA_ "GenSigSendType" SG_ 2155536384 TnDrvRIMOffUnbIO 10;
BA_ "SignalType" SG_ 2155536384 TnDrvRIMOffUnbIO "BLN";
BA_ "SignalLongName" SG_ 2155536384 TnDrvRIMOffUnbIO "Teen Driver Reverse Impact Mitigation Off Unavailable Indication On";
BA_ "VNSigAllNodes" SG_ 2155536384 TnDrvRIMOffUnbIO 1;
BA_ "GenSigSendType" SG_ 2155536384 RVBUnblIO 10;
BA_ "GenSigSendOnInit" SG_ 2155536384 RVBUnblIO 2;
BA_ "SignalType" SG_ 2155536384 RVBUnblIO "BLN";
BA_ "SignalLongName" SG_ 2155536384 RVBUnblIO "Rear Virtual Bumper Unavailable Indication On";
BA_ "VNSigAllNodes" SG_ 2155536384 RVBUnblIO 1;
BA_ "GenSigSendType" SG_ 2155536384 RVBFldIO 10;
BA_ "SignalType" SG_ 2155536384 RVBFldIO "BLN";
BA_ "SignalLongName" SG_ 2155536384 RVBFldIO "Rear Virtual Bumper Failed Indication On";
BA_ "VNSigAllNodes" SG_ 2155536384 RVBFldIO 1;
BA_ "GenSigSendType" SG_ 2155536384 RVBEnbldIO 10;
BA_ "SignalType" SG_ 2155536384 RVBEnbldIO "BLN";
BA_ "SignalLongName" SG_ 2155536384 RVBEnbldIO "Rear Virtual Bumper Enabled Indication On";
BA_ "VNSigAllNodes" SG_ 2155536384 RVBEnbldIO 1;
BA_ "GenSigSendType" SG_ 2155536384 RVBDsbldIO 10;
BA_ "SignalType" SG_ 2155536384 RVBDsbldIO "BLN";
BA_ "SignalLongName" SG_ 2155536384 RVBDsbldIO "Rear Virtual Bumper Disabled Indication On";
BA_ "VNSigAllNodes" SG_ 2155536384 RVBDsbldIO 1;
BA_ "GenSigSendType" SG_ 2152742912 ShrtRngRdrOffIO 10;
BA_ "SignalType" SG_ 2152742912 ShrtRngRdrOffIO "BLN";
BA_ "SignalLongName" SG_ 2152742912 ShrtRngRdrOffIO "Short Range Radar Off Indication On";
BA_ "VNSigAllNodes" SG_ 2152742912 ShrtRngRdrOffIO 1;
BA_ "GenSigSendType" SG_ 2152742912 RrRdrFldIO 10;
BA_ "SignalType" SG_ 2152742912 RrRdrFldIO "BLN";
BA_ "SignalLongName" SG_ 2152742912 RrRdrFldIO "Rear Radar Failed Indication On";
BA_ "VNSigAllNodes" SG_ 2152742912 RrRdrFldIO 1;
BA_ "GenSigSendType" SG_ 2152742912 RrRdrBlckdIO 10;
BA_ "GenSigSendOnInit" SG_ 2152742912 RrRdrBlckdIO 2;
BA_ "SignalType" SG_ 2152742912 RrRdrBlckdIO "BLN";
BA_ "SignalLongName" SG_ 2152742912 RrRdrBlckdIO "Rear Radar Blocked Indication On";
BA_ "VNSigAllNodes" SG_ 2152742912 RrRdrBlckdIO 1;
BA_ "GenSigSendType" SG_ 2152742912 RrEOCMMdlFldIO 10;
BA_ "SignalType" SG_ 2152742912 RrEOCMMdlFldIO "BLN";
BA_ "SignalLongName" SG_ 2152742912 RrEOCMMdlFldIO "Rear External Object Calculating Module Failed Indication On";
BA_ "VNSigAllNodes" SG_ 2152742912 RrEOCMMdlFldIO 1;
BA_ "GenSigDeltaValue" SG_ 2152685568 RadConInfID 1;
BA_ "GenSigSendType" SG_ 2152685568 RadConInfID 12;
BA_ "GenSigSendOnInit" SG_ 2152685568 RadConInfID 1;
BA_ "VNSigInfotainment" SG_ 2152685568 RadConInfID 1;
BA_ "SignalType" SG_ 2152685568 RadConInfID "UNM";
BA_ "SignalLongName" SG_ 2152685568 RadConInfID "Radio Content Information Identifier";
BA_ "VNSigAllNodes" SG_ 2152685568 RadConInfID 1;
BA_ "GenSigSendType" SG_ 2152685568 RadConInfReqSrc 10;
BA_ "GenSigSendOnInit" SG_ 2152685568 RadConInfReqSrc 1;
BA_ "VNSigInfotainment" SG_ 2152685568 RadConInfReqSrc 1;
BA_ "SignalType" SG_ 2152685568 RadConInfReqSrc "ENM";
BA_ "SignalLongName" SG_ 2152685568 RadConInfReqSrc "Radio Content Information Requesting Source";
BA_ "VNSigAllNodes" SG_ 2152685568 RadConInfReqSrc 1;
BA_ "GenSigSendType" SG_ 2152685568 RadBrdcstSrc 10;
BA_ "GenSigSendOnInit" SG_ 2152685568 RadBrdcstSrc 1;
BA_ "VNSigInfotainment" SG_ 2152685568 RadBrdcstSrc 1;
BA_ "SignalType" SG_ 2152685568 RadBrdcstSrc "ENM";
BA_ "SignalLongName" SG_ 2152685568 RadBrdcstSrc "Radio Broadcast Source";
BA_ "VNSigAllNodes" SG_ 2152685568 RadBrdcstSrc 1;
BA_ "GenSigSendType" SG_ 2152685568 RadConInfCmd 10;
BA_ "GenSigSendOnInit" SG_ 2152685568 RadConInfCmd 1;
BA_ "VNSigInfotainment" SG_ 2152685568 RadConInfCmd 1;
BA_ "SignalType" SG_ 2152685568 RadConInfCmd "ENM";
BA_ "SignalLongName" SG_ 2152685568 RadConInfCmd "Radio Content Information Command";
BA_ "VNSigAllNodes" SG_ 2152685568 RadConInfCmd 1;
BA_ "GenSigSendType" SG_ 2151235584 EhnSrvImmbComRst 10;
BA_ "SignalType" SG_ 2151235584 EhnSrvImmbComRst "BLN";
BA_ "SignalLongName" SG_ 2151235584 EhnSrvImmbComRst "Enhanced Services Immobilization Command Reset";
BA_ "VNSigAllNodes" SG_ 2151235584 EhnSrvImmbComRst 1;
BA_ "GenSigDeltaValue" SG_ 2151235584 NmofPrgKFbExtd 1;
BA_ "GenSigSendType" SG_ 2151235584 NmofPrgKFbExtd 12;
BA_ "SignalType" SG_ 2151235584 NmofPrgKFbExtd "UNM";
BA_ "SignalLongName" SG_ 2151235584 NmofPrgKFbExtd "Number of Programmed Keyfobs Extended";
BA_ "VNSigAllNodes" SG_ 2151235584 NmofPrgKFbExtd 1;
BA_ "GenSigSendType" SG_ 2151235584 AlcKyIIncmIndOn 10;
BA_ "SignalType" SG_ 2151235584 AlcKyIIncmIndOn "BLN";
BA_ "SignalLongName" SG_ 2151235584 AlcKyIIncmIndOn "Alco Key Incomplete Indication On";
BA_ "VNSigAllNodes" SG_ 2151235584 AlcKyIIncmIndOn 1;
BA_ "GenSigSendType" SG_ 2151235584 VehSecAuthnSesComp 10;
BA_ "SignalType" SG_ 2151235584 VehSecAuthnSesComp "BLN";
BA_ "SignalLongName" SG_ 2151235584 VehSecAuthnSesComp "Vehicle Security Authentication Session Completed";
BA_ "VNSigAllNodes" SG_ 2151235584 VehSecAuthnSesComp 1;
BA_ "GenSigSendType" SG_ 2151235584 VTDTmprDetected 10;
BA_ "SignalType" SG_ 2151235584 VTDTmprDetected "BLN";
BA_ "SignalLongName" SG_ 2151235584 VTDTmprDetected "Vehicle Theft Deterrent Tamper Detected";
BA_ "VNSigAllNodes" SG_ 2151235584 VTDTmprDetected 1;
BA_ "GenSigSendType" SG_ 2151235584 VehSecSysFldIO 10;
BA_ "SignalType" SG_ 2151235584 VehSecSysFldIO "BLN";
BA_ "SignalLongName" SG_ 2151235584 VehSecSysFldIO "Vehicle Security System Failed Indication On";
BA_ "VNSigAllNodes" SG_ 2151235584 VehSecSysFldIO 1;
BA_ "GenSigSendType" SG_ 2151235584 VehSecStrgColLckPwdV 10;
BA_ "SignalType" SG_ 2151235584 VehSecStrgColLckPwdV "ENM";
BA_ "SignalLongName" SG_ 2151235584 VehSecStrgColLckPwdV "Vehicle Security Steering Column Lock Password Validity";
BA_ "VNSigAllNodes" SG_ 2151235584 VehSecStrgColLckPwdV 1;
BA_ "GenSigDeltaValue" SG_ 2151235584 VehSecStrgColLckPwd 1;
BA_ "GenSigSendType" SG_ 2151235584 VehSecStrgColLckPwd 12;
BA_ "SignalType" SG_ 2151235584 VehSecStrgColLckPwd "UNM";
BA_ "SignalLongName" SG_ 2151235584 VehSecStrgColLckPwd "Vehicle Security Steering Column Lock Password";
BA_ "VNSigAllNodes" SG_ 2151235584 VehSecStrgColLckPwd 1;
BA_ "GenSigSendType" SG_ 2151235584 VhSecNImmoIndRq 10;
BA_ "GenSigSendOnInit" SG_ 2151235584 VhSecNImmoIndRq 1;
BA_ "SignalType" SG_ 2151235584 VhSecNImmoIndRq "ENM";
BA_ "SignalLongName" SG_ 2151235584 VhSecNImmoIndRq "Vehicle Security Non Immobilizer Indication Request";
BA_ "VNSigAllNodes" SG_ 2151235584 VhSecNImmoIndRq 1;
BA_ "GenSigSendType" SG_ 2151235584 StrgColLckCmd 10;
BA_ "SignalType" SG_ 2151235584 StrgColLckCmd "ENM";
BA_ "SignalLongName" SG_ 2151235584 StrgColLckCmd "Steering Column Lock Command";
BA_ "VNSigAllNodes" SG_ 2151235584 StrgColLckCmd 1;
BA_ "GenSigSendType" SG_ 2151235584 DrIdDevLrnd 10;
BA_ "SignalType" SG_ 2151235584 DrIdDevLrnd "ENM";
BA_ "SignalLongName" SG_ 2151235584 DrIdDevLrnd "Driver Identification Device Learned";
BA_ "VNSigAllNodes" SG_ 2151235584 DrIdDevLrnd 1;
BA_ "GenSigSendType" SG_ 2151235584 IllDrIdDevDtctd 10;
BA_ "SignalType" SG_ 2151235584 IllDrIdDevDtctd "BLN";
BA_ "SignalLongName" SG_ 2151235584 IllDrIdDevDtctd "Illegitimate Driver Identification Device Detected";
BA_ "VNSigAllNodes" SG_ 2151235584 IllDrIdDevDtctd 1;
BA_ "GenSigSendType" SG_ 2151235584 EhnSrvEngImmStat 10;
BA_ "SignalType" SG_ 2151235584 EhnSrvEngImmStat "ENM";
BA_ "SignalLongName" SG_ 2151235584 EhnSrvEngImmStat "Enhanced Services Engine Immobilized Status";
BA_ "VNSigAllNodes" SG_ 2151235584 EhnSrvEngImmStat 1;
BA_ "GenSigSendType" SG_ 2151235584 ClmSysBkupFlrIndOn 10;
BA_ "SignalType" SG_ 2151235584 ClmSysBkupFlrIndOn "BLN";
BA_ "SignalLongName" SG_ 2151235584 ClmSysBkupFlrIndOn "Column System Backup Failure Indication On";
BA_ "VNSigAllNodes" SG_ 2151235584 ClmSysBkupFlrIndOn 1;
BA_ "GenSigSendType" SG_ 2151235584 VehStatStAtv 10;
BA_ "SignalType" SG_ 2151235584 VehStatStAtv "BLN";
BA_ "SignalLongName" SG_ 2151235584 VehStatStAtv "Vehicle Stationary Status Active";
BA_ "VNSigAllNodes" SG_ 2151235584 VehStatStAtv 1;
BA_ "GenSigSendType" SG_ 2150776832 HybImpSnsDsbld 10;
BA_ "SignalType" SG_ 2150776832 HybImpSnsDsbld "BLN";
BA_ "SignalLongName" SG_ 2150776832 HybImpSnsDsbld "Hybrid Impact Sensing Disabled";
BA_ "VNSigAllNodes" SG_ 2150776832 HybImpSnsDsbld 1;
BA_ "GenSigSendType" SG_ 2150776832 SftyMuteRd 10;
BA_ "GenSigSendOnInit" SG_ 2150776832 SftyMuteRd 1;
BA_ "SignalType" SG_ 2150776832 SftyMuteRd "BLN";
BA_ "SignalLongName" SG_ 2150776832 SftyMuteRd "Safety Mute Requested";
BA_ "VNSigAllNodes" SG_ 2150776832 SftyMuteRd 1;
BA_ "GenSigSendType" SG_ 2150776832 HybVehHiVltInvDisRqd 10;
BA_ "SignalType" SG_ 2150776832 HybVehHiVltInvDisRqd "BLN";
BA_ "SignalLongName" SG_ 2150776832 HybVehHiVltInvDisRqd "Hybrid Vehicle High Voltage Inverter Disable Requested";
BA_ "VNSigAllNodes" SG_ 2150776832 HybVehHiVltInvDisRqd 1;
BA_ "GenSigSendType" SG_ 2150776832 EvntEnbld 10;
BA_ "SignalType" SG_ 2150776832 EvntEnbld "BLN";
BA_ "SignalLongName" SG_ 2150776832 EvntEnbld "Event Enabled";
BA_ "VNSigAllNodes" SG_ 2150776832 EvntEnbld 1;
BA_ "GenSigSendType" SG_ 2150776832 ShfUlkBrToShftIndCtrl 10;
BA_ "SignalType" SG_ 2150776832 ShfUlkBrToShftIndCtrl "BLN";
BA_ "SignalLongName" SG_ 2150776832 ShfUlkBrToShftIndCtrl "Shifter Unlocked Brake To Shift Indication Control";
BA_ "VNSigAllNodes" SG_ 2150776832 ShfUlkBrToShftIndCtrl 1;
BA_ "GenSigSendType" SG_ 2150776832 ShftLkdBuStbltIndCtrl 10;
BA_ "SignalType" SG_ 2150776832 ShftLkdBuStbltIndCtrl "BLN";
BA_ "SignalLongName" SG_ 2150776832 ShftLkdBuStbltIndCtrl "Shifter Locked Buckle Seatbelts Indication Control";
BA_ "VNSigAllNodes" SG_ 2150776832 ShftLkdBuStbltIndCtrl 1;
BA_ "GenSigSendType" SG_ 2150776832 SbItlkTrnsShftLvLkRd 10;
BA_ "SignalType" SG_ 2150776832 SbItlkTrnsShftLvLkRd "BLN";
BA_ "SignalLongName" SG_ 2150776832 SbItlkTrnsShftLvLkRd "Seatbelt Interlock Transmission Shift Lever Lock Requested";
BA_ "VNSigAllNodes" SG_ 2150776832 SbItlkTrnsShftLvLkRd 1;
BA_ "GenSigSendType" SG_ 2150776832 FrPsngrStOccSnsngPriDat 10;
BA_ "SignalType" SG_ 2150776832 FrPsngrStOccSnsngPriDat "BCD";
BA_ "SignalLongName" SG_ 2150776832 FrPsngrStOccSnsngPriDat "Front Passenger Seat Occupancy Sensing Primary Data";
BA_ "VNSigAllNodes" SG_ 2150776832 FrPsngrStOccSnsngPriDat 1;
BA_ "GenSigSendType" SG_ 2150776832 MmryRclImpctDisRq 10;
BA_ "GenSigSendOnInit" SG_ 2150776832 MmryRclImpctDisRq 1;
BA_ "VNSigPrimaryTriggering" SG_ 2150776832 MmryRclImpctDisRq 1;
BA_ "SignalType" SG_ 2150776832 MmryRclImpctDisRq "ENM";
BA_ "SignalLongName" SG_ 2150776832 MmryRclImpctDisRq "Memory Recall Impact Disable Request";
BA_ "VNSigAllNodes" SG_ 2150776832 MmryRclImpctDisRq 1;
BA_ "GenSigDeltaValue" SG_ 2150776832 SIREvntSychCntr 1;
BA_ "GenSigSendType" SG_ 2150776832 SIREvntSychCntr 12;
BA_ "GenSigSendOnInit" SG_ 2150776832 SIREvntSychCntr 1;
BA_ "SignalType" SG_ 2150776832 SIREvntSychCntr "UNM";
BA_ "SignalLongName" SG_ 2150776832 SIREvntSychCntr "Supplemental Inflatable Restraint Event Synchronization Counter";
BA_ "VNSigAllNodes" SG_ 2150776832 SIREvntSychCntr 1;
BA_ "SignalType" SG_ 2155347968 DrvrStPerfMdCsCrStVal "ENM";
BA_ "SignalLongName" SG_ 2155347968 DrvrStPerfMdCsCrStVal "Driver Seat Performance Mode Customization Current Setting Value";
BA_ "VNSigAllNodes" SG_ 2155347968 DrvrStPerfMdCsCrStVal 1;
BA_ "SignalType" SG_ 2155347968 DrvrStPerfMdCsStAvl "BLN";
BA_ "SignalLongName" SG_ 2155347968 DrvrStPerfMdCsStAvl "Driver Seat Performance Mode Customization Setting Available";
BA_ "VNSigAllNodes" SG_ 2155347968 DrvrStPerfMdCsStAvl 1;
BA_ "SignalType" SG_ 2155347968 ACCPerfMdCsCrStVal "ENM";
BA_ "SignalLongName" SG_ 2155347968 ACCPerfMdCsCrStVal "Adaptive Cruise Control Performance Mode Customization Current Setting Value";
BA_ "VNSigAllNodes" SG_ 2155347968 ACCPerfMdCsCrStVal 1;
BA_ "SignalType" SG_ 2155347968 ACCPerfMdCsStAvl "BLN";
BA_ "SignalLongName" SG_ 2155347968 ACCPerfMdCsStAvl "Adaptive Cruise Control Performance Mode Customization Setting Available";
BA_ "VNSigAllNodes" SG_ 2155347968 ACCPerfMdCsStAvl 1;
BA_ "SignalType" SG_ 2155347968 VehRollAngleV "ENM";
BA_ "SignalLongName" SG_ 2155347968 VehRollAngleV "Vehicle Roll Angle Validity";
BA_ "VNSigAllNodes" SG_ 2155347968 VehRollAngleV 1;
BA_ "SignalType" SG_ 2155347968 VehRollAngle "UNM";
BA_ "SignalLongName" SG_ 2155347968 VehRollAngle "Vehicle Roll Angle";
BA_ "VNSigAllNodes" SG_ 2155347968 VehRollAngle 1;
BA_ "SignalType" SG_ 2155347968 ActVbnCtrlMlfIO "BLN";
BA_ "SignalLongName" SG_ 2155347968 ActVbnCtrlMlfIO "Active Vibration Control Malfunction Indication On";
BA_ "VNSigAllNodes" SG_ 2155347968 ActVbnCtrlMlfIO 1;
BA_ "SignalType" SG_ 2155347968 HillDesCtrlRedVehSpIO "BLN";
BA_ "SignalLongName" SG_ 2155347968 HillDesCtrlRedVehSpIO "Hill Descent Control Reduce Vehicle Speed Indication On";
BA_ "VNSigAllNodes" SG_ 2155347968 HillDesCtrlRedVehSpIO 1;
BA_ "SignalType" SG_ 2155347968 FourWhlDrvIndReq "ENM";
BA_ "SignalLongName" SG_ 2155347968 FourWhlDrvIndReq "Four Wheel Drive Indication Request";
BA_ "VNSigAllNodes" SG_ 2155347968 FourWhlDrvIndReq 1;
BA_ "SignalType" SG_ 2155347968 PedtrnProtVDA "ENM";
BA_ "SignalLongName" SG_ 2155347968 PedtrnProtVDA "Pedestrian Protection Virtual Device Availability";
BA_ "GenSigStartValue" SG_ 2155347968 PedtrnProtVDA 1;
BA_ "VNSigAllNodes" SG_ 2155347968 PedtrnProtVDA 1;
BA_ "SignalType" SG_ 2155347968 EngRecDwnshftIO "BLN";
BA_ "SignalLongName" SG_ 2155347968 EngRecDwnshftIO "Engine Recommended Downshift Indication On";
BA_ "VNSigAllNodes" SG_ 2155347968 EngRecDwnshftIO 1;
BA_ "SignalType" SG_ 2155347968 AppCltchAutSrtIO "BLN";
BA_ "SignalLongName" SG_ 2155347968 AppCltchAutSrtIO "Apply Clutch For Automatic Start Indication On";
BA_ "VNSigAllNodes" SG_ 2155347968 AppCltchAutSrtIO 1;
BA_ "SignalType" SG_ 2155347968 CPSUnblIO "BLN";
BA_ "SignalLongName" SG_ 2155347968 CPSUnblIO "Collision Preparation System Unavailable Indication On";
BA_ "VNSigAllNodes" SG_ 2155347968 CPSUnblIO 1;
BA_ "SignalType" SG_ 2155347968 StBltTgtSetAvl "BLN";
BA_ "SignalLongName" SG_ 2155347968 StBltTgtSetAvl "Seat Belt Tightening Settings Available";
BA_ "VNSigAllNodes" SG_ 2155347968 StBltTgtSetAvl 1;
BA_ "SignalType" SG_ 2155347968 StBltTgtCrtSetVal "ENM";
BA_ "SignalLongName" SG_ 2155347968 StBltTgtCrtSetVal "Seat Belt Tightening Current Setting Value";
BA_ "VNSigAllNodes" SG_ 2155347968 StBltTgtCrtSetVal 1;
BA_ "SignalType" SG_ 2155347968 PedtrnProtSysDisbld "BLN";
BA_ "SignalLongName" SG_ 2155347968 PedtrnProtSysDisbld "Pedestrian Protection System Disabled";
BA_ "VNSigAllNodes" SG_ 2155347968 PedtrnProtSysDisbld 1;
BA_ "SignalType" SG_ 2155347968 PedtrnProtSysDpl "BLN";
BA_ "SignalLongName" SG_ 2155347968 PedtrnProtSysDpl "Pedestrian Protection System Deployed";
BA_ "VNSigAllNodes" SG_ 2155347968 PedtrnProtSysDpl 1;
BA_ "SignalType" SG_ 2155347968 SrvPedtrnProtSysIO "BLN";
BA_ "SignalLongName" SG_ 2155347968 SrvPedtrnProtSysIO "Service Pedestrian Protection System Indication On";
BA_ "VNSigAllNodes" SG_ 2155347968 SrvPedtrnProtSysIO 1;
BA_ "SignalType" SG_ 2155347968 CPSOffIO "BLN";
BA_ "SignalLongName" SG_ 2155347968 CPSOffIO "Collision Preparation System Off Indication On";
BA_ "VNSigAllNodes" SG_ 2155347968 CPSOffIO 1;
BA_ "SignalType" SG_ 2155347968 SecAxlTmpInhIO "BLN";
BA_ "SignalLongName" SG_ 2155347968 SecAxlTmpInhIO "Secondary Axle Temporary Inhibit Indication On";
BA_ "VNSigAllNodes" SG_ 2155347968 SecAxlTmpInhIO 1;
BA_ "SignalType" SG_ 2155347968 CPSFldIO "BLN";
BA_ "SignalLongName" SG_ 2155347968 CPSFldIO "Collision Preparation System Failed Indication On";
BA_ "VNSigAllNodes" SG_ 2155347968 CPSFldIO 1;
BA_ "SignalType" SG_ 2155347968 CPSAlrtOnlIO "BLN";
BA_ "SignalLongName" SG_ 2155347968 CPSAlrtOnlIO "Collision Preparation System Alert Only Indication On";
BA_ "VNSigAllNodes" SG_ 2155347968 CPSAlrtOnlIO 1;
BA_ "SignalType" SG_ 2155347968 RrAxlTmpInhIO "BLN";
BA_ "SignalLongName" SG_ 2155347968 RrAxlTmpInhIO "Rear Axle Temporary Inhibit Indication On";
BA_ "VNSigAllNodes" SG_ 2155347968 RrAxlTmpInhIO 1;
BA_ "SignalType" SG_ 2155347968 TirePrsLowIO "BLN";
BA_ "SignalLongName" SG_ 2155347968 TirePrsLowIO "Tire Pressure Low Indication On";
BA_ "VNSigAllNodes" SG_ 2155347968 TirePrsLowIO 1;
BA_ "SignalType" SG_ 2155347968 EPBSysStatIndReq "ENM";
BA_ "SignalLongName" SG_ 2155347968 EPBSysStatIndReq "Electric Park Brake System Status Indication Request";
BA_ "VNSigAllNodes" SG_ 2155347968 EPBSysStatIndReq 1;
BA_ "SignalType" SG_ 2155347968 EngOilStrvtnIO "BLN";
BA_ "SignalLongName" SG_ 2155347968 EngOilStrvtnIO "Engine Oil Starvation Indication On";
BA_ "VNSigAllNodes" SG_ 2155347968 EngOilStrvtnIO 1;
BA_ "SignalType" SG_ 2155347968 SrvSuspSysIO "BLN";
BA_ "SignalLongName" SG_ 2155347968 SrvSuspSysIO "Service Suspension System Indication On";
BA_ "VNSigAllNodes" SG_ 2155347968 SrvSuspSysIO 1;
BA_ "SignalType" SG_ 2155347968 ServAdpCrsCtrlIndOn "BLN";
BA_ "SignalLongName" SG_ 2155347968 ServAdpCrsCtrlIndOn "Service Adaptive Cruise Control Indication On";
BA_ "VNSigAllNodes" SG_ 2155347968 ServAdpCrsCtrlIndOn 1;
BA_ "SignalType" SG_ 2155347968 EngRecmndUpshftIO "BLN";
BA_ "SignalLongName" SG_ 2155347968 EngRecmndUpshftIO "Engine Recommended Upshift Indication On";
BA_ "VNSigAllNodes" SG_ 2155347968 EngRecmndUpshftIO 1;
BA_ "SignalType" SG_ 2155347968 BrkSysMalFuncIndOn "BLN";
BA_ "SignalLongName" SG_ 2155347968 BrkSysMalFuncIndOn "Brake System Malfunction Indication On";
BA_ "VNSigAllNodes" SG_ 2155347968 BrkSysMalFuncIndOn 1;
BA_ "SignalType" SG_ 2155347968 SecAxlNonEmMalfIO "BLN";
BA_ "SignalLongName" SG_ 2155347968 SecAxlNonEmMalfIO "Secondary Axle Non-emissions Malf Ind On";
BA_ "VNSigAllNodes" SG_ 2155347968 SecAxlNonEmMalfIO 1;
BA_ "SignalType" SG_ 2155347968 BrkFldLvlLw "BLN";
BA_ "SignalLongName" SG_ 2155347968 BrkFldLvlLw "Brake Fluid Level Low";
BA_ "VNSigAllNodes" SG_ 2155347968 BrkFldLvlLw 1;
BA_ "SignalType" SG_ 2155347968 ACCUnavlbleDTWthrIO "BLN";
BA_ "SignalLongName" SG_ 2155347968 ACCUnavlbleDTWthrIO "Adaptive Cruise Unavailable Due To Weather Indication On";
BA_ "VNSigAllNodes" SG_ 2155347968 ACCUnavlbleDTWthrIO 1;
BA_ "SignalType" SG_ 2155347968 ACCTmpUnavlbleIO "BLN";
BA_ "SignalLongName" SG_ 2155347968 ACCTmpUnavlbleIO "Adaptive Cruise Control Temporarily Unavailable Indication On";
BA_ "VNSigAllNodes" SG_ 2155347968 ACCTmpUnavlbleIO 1;
BA_ "SignalType" SG_ 2155347968 EngEmsRelMalfIndReq "ENM";
BA_ "SignalLongName" SG_ 2155347968 EngEmsRelMalfIndReq "Engine Emissions Related Malfunction Indication Request";
BA_ "VNSigAllNodes" SG_ 2155347968 EngEmsRelMalfIndReq 1;
BA_ "SignalType" SG_ 2155347968 DrShftCntrlReqDndIO "BLN";
BA_ "SignalLongName" SG_ 2155347968 DrShftCntrlReqDndIO "Driver Shift Control Request Denied Indication On";
BA_ "VNSigAllNodes" SG_ 2155347968 DrShftCntrlReqDndIO 1;
BA_ "SignalType" SG_ 2155347968 BrkPadWrnIO "BLN";
BA_ "SignalLongName" SG_ 2155347968 BrkPadWrnIO "Brake Pad Worn Indication On";
BA_ "VNSigAllNodes" SG_ 2155347968 BrkPadWrnIO 1;
BA_ "SignalType" SG_ 2155347968 RrAxlMalfIO "BLN";
BA_ "SignalLongName" SG_ 2155347968 RrAxlMalfIO "Rear Axle Malfunction Indication On";
BA_ "VNSigAllNodes" SG_ 2155347968 RrAxlMalfIO 1;
BA_ "SignalType" SG_ 2155347968 EPBSysWrnIndReq "ENM";
BA_ "SignalLongName" SG_ 2155347968 EPBSysWrnIndReq "Electric Park Brake System Warning Indication Request";
BA_ "VNSigAllNodes" SG_ 2155347968 EPBSysWrnIndReq 1;
BA_ "SignalType" SG_ 2155347968 CompOvrhtIndOn "BLN";
BA_ "SignalLongName" SG_ 2155347968 CompOvrhtIndOn "Compressor Overheated Indication On";
BA_ "VNSigAllNodes" SG_ 2155347968 CompOvrhtIndOn 1;
BA_ "SignalType" SG_ 2155347968 BrkFldLvlLwV "ENM";
BA_ "SignalLongName" SG_ 2155347968 BrkFldLvlLwV "Brake Fluid Level Low Validity";
BA_ "VNSigAllNodes" SG_ 2155347968 BrkFldLvlLwV 1;
BA_ "SignalType" SG_ 2155347968 ACCSnsClnRqdIO "BLN";
BA_ "SignalLongName" SG_ 2155347968 ACCSnsClnRqdIO "Adaptive Cruise Control Sensor Cleaning Required Indication On";
BA_ "VNSigAllNodes" SG_ 2155347968 ACCSnsClnRqdIO 1;
BA_ "SignalType" SG_ 2155347968 TrnsSkpShftIO "BLN";
BA_ "SignalLongName" SG_ 2155347968 TrnsSkpShftIO "Transmission Skip Shift Indication On";
BA_ "VNSigAllNodes" SG_ 2155347968 TrnsSkpShftIO 1;
BA_ "GenSigSendType" SG_ 2155585536 StBltTgtCSRq 10;
BA_ "GenSigSendOnInit" SG_ 2155585536 StBltTgtCSRq 1;
BA_ "SignalType" SG_ 2155585536 StBltTgtCSRq "ENM";
BA_ "SignalLongName" SG_ 2155585536 StBltTgtCSRq "Seat Belt Tightening Customize Setting Request";
BA_ "VNSigAllNodes" SG_ 2155585536 StBltTgtCSRq 1;
BA_ "GenSigDeltaValue" SG_ 2159173632 ODI_IPC2CntrStck 1;
BA_ "GenSigSendType" SG_ 2159173632 ODI_IPC2CntrStck 12;
BA_ "VNSigInfotainment" SG_ 2159173632 ODI_IPC2CntrStck 1;
BA_ "SignalType" SG_ 2159173632 ODI_IPC2CntrStck "UNM";
BA_ "SignalLongName" SG_ 2159173632 ODI_IPC2CntrStck "Open Display Interface IPC 2 CenterStack";
BA_ "VNSigAllNodes" SG_ 2159173632 ODI_IPC2CntrStck 1;
BA_ "GenSigDeltaValue" SG_ 2159165440 ODI_CntrStck2IPC 1;
BA_ "GenSigSendType" SG_ 2159165440 ODI_CntrStck2IPC 12;
BA_ "VNSigInfotainment" SG_ 2159165440 ODI_CntrStck2IPC 1;
BA_ "SignalType" SG_ 2159165440 ODI_CntrStck2IPC "UNM";
BA_ "SignalLongName" SG_ 2159165440 ODI_CntrStck2IPC "Open Display Interface CenterStack 2 IPC";
BA_ "VNSigAllNodes" SG_ 2159165440 ODI_CntrStck2IPC 1;
BA_ "GenSigSendType" SG_ 2153840640 TnDrvDRLOffUnbIO 10;
BA_ "SignalType" SG_ 2153840640 TnDrvDRLOffUnbIO "BLN";
BA_ "SignalLongName" SG_ 2153840640 TnDrvDRLOffUnbIO "Teen Driver Daytime Running Lights Off Unavailable Indication On";
BA_ "VNSigAllNodes" SG_ 2153840640 TnDrvDRLOffUnbIO 1;
BA_ "GenSigSendType" SG_ 2153840640 TnDrvALCOffUnbIO 10;
BA_ "SignalType" SG_ 2153840640 TnDrvALCOffUnbIO "BLN";
BA_ "SignalLongName" SG_ 2153840640 TnDrvALCOffUnbIO "Teen Driver Automatic Light Control Off Unavailable Indication On";
BA_ "VNSigAllNodes" SG_ 2153840640 TnDrvALCOffUnbIO 1;
BA_ "GenSigDeltaValue" SG_ 2153840640 TeenDrvLDWEvntsRpt 1;
BA_ "GenSigSendType" SG_ 2153840640 TeenDrvLDWEvntsRpt 12;
BA_ "SignalType" SG_ 2153840640 TeenDrvLDWEvntsRpt "UNM";
BA_ "SignalLongName" SG_ 2153840640 TeenDrvLDWEvntsRpt "Teen Driver Lane Departure Warning Events Report";
BA_ "VNSigAllNodes" SG_ 2153840640 TeenDrvLDWEvntsRpt 1;
BA_ "GenSigDeltaValue" SG_ 2153840640 TeenDrvMaxSpdRpt 1;
BA_ "GenSigSendType" SG_ 2153840640 TeenDrvMaxSpdRpt 12;
BA_ "SignalType" SG_ 2153840640 TeenDrvMaxSpdRpt "UNM";
BA_ "SignalLongName" SG_ 2153840640 TeenDrvMaxSpdRpt "Teen Driver Maximum Speed Report";
BA_ "VNSigAllNodes" SG_ 2153840640 TeenDrvMaxSpdRpt 1;
BA_ "GenSigDeltaValue" SG_ 2153840640 TDFwdClnImntAlrtsRpt 1;
BA_ "GenSigSendType" SG_ 2153840640 TDFwdClnImntAlrtsRpt 12;
BA_ "SignalType" SG_ 2153840640 TDFwdClnImntAlrtsRpt "UNM";
BA_ "SignalLongName" SG_ 2153840640 TDFwdClnImntAlrtsRpt "Teen Driver Forward Collision Imminent Alerts Report";
BA_ "VNSigAllNodes" SG_ 2153840640 TDFwdClnImntAlrtsRpt 1;
BA_ "GenSigDeltaValue" SG_ 2153840640 TDRevClnMtgnBrEvRpt 1;
BA_ "GenSigSendType" SG_ 2153840640 TDRevClnMtgnBrEvRpt 12;
BA_ "SignalType" SG_ 2153840640 TDRevClnMtgnBrEvRpt "UNM";
BA_ "SignalLongName" SG_ 2153840640 TDRevClnMtgnBrEvRpt "Teen Driver Reverse Collision Mitigation Braking Events Report";
BA_ "VNSigAllNodes" SG_ 2153840640 TDRevClnMtgnBrEvRpt 1;
BA_ "GenSigDeltaValue" SG_ 2153840640 TDFwdClnMtgnBrEvRpt 1;
BA_ "GenSigSendType" SG_ 2153840640 TDFwdClnMtgnBrEvRpt 12;
BA_ "SignalType" SG_ 2153840640 TDFwdClnMtgnBrEvRpt "UNM";
BA_ "SignalLongName" SG_ 2153840640 TDFwdClnMtgnBrEvRpt "Teen Driver Forward Collision Mitigation Braking Events Report";
BA_ "VNSigAllNodes" SG_ 2153840640 TDFwdClnMtgnBrEvRpt 1;
BA_ "GenSigDeltaValue" SG_ 2153840640 TDFwdClnHdwyAlrtsRpt 1;
BA_ "GenSigSendType" SG_ 2153840640 TDFwdClnHdwyAlrtsRpt 12;
BA_ "SignalType" SG_ 2153840640 TDFwdClnHdwyAlrtsRpt "UNM";
BA_ "SignalLongName" SG_ 2153840640 TDFwdClnHdwyAlrtsRpt "Teen Driver Forward Collision Headway Alerts Report";
BA_ "VNSigAllNodes" SG_ 2153840640 TDFwdClnHdwyAlrtsRpt 1;
BA_ "GenSigSendType" SG_ 2154094592 IntDimSeldClrTypStVal 10;
BA_ "GenSigSendOnInit" SG_ 2154094592 IntDimSeldClrTypStVal 1;
BA_ "SignalType" SG_ 2154094592 IntDimSeldClrTypStVal "ENM";
BA_ "SignalLongName" SG_ 2154094592 IntDimSeldClrTypStVal "Interior Dimming Selected Color Type Setting Value";
BA_ "VNSigAllNodes" SG_ 2154094592 IntDimSeldClrTypStVal 1;
BA_ "GenSigSendType" SG_ 2154094592 IntDimSeldAnmTypStVal 10;
BA_ "GenSigSendOnInit" SG_ 2154094592 IntDimSeldAnmTypStVal 1;
BA_ "SignalType" SG_ 2154094592 IntDimSeldAnmTypStVal "ENM";
BA_ "SignalLongName" SG_ 2154094592 IntDimSeldAnmTypStVal "Interior Dimming Selected Animation Type Setting Value";
BA_ "VNSigAllNodes" SG_ 2154094592 IntDimSeldAnmTypStVal 1;
BA_ "GenSigSendType" SG_ 2154094592 IDCTA_ClrTyp30Avl 10;
BA_ "GenSigSendOnInit" SG_ 2154094592 IDCTA_ClrTyp30Avl 1;
BA_ "PacketOrder" SG_ 2154094592 IDCTA_ClrTyp30Avl 31;
BA_ "SignalType" SG_ 2154094592 IDCTA_ClrTyp30Avl "BLN";
BA_ "SignalLongName" SG_ 2154094592 IDCTA_ClrTyp30Avl "Interior Dimming Color Type Available : Color Type 30 Available";
BA_ "VNSigAllNodes" SG_ 2154094592 IDCTA_ClrTyp30Avl 1;
BA_ "GenSigSendType" SG_ 2154094592 IDCTA_ClrTyp29Avl 10;
BA_ "GenSigSendOnInit" SG_ 2154094592 IDCTA_ClrTyp29Avl 1;
BA_ "PacketOrder" SG_ 2154094592 IDCTA_ClrTyp29Avl 30;
BA_ "SignalType" SG_ 2154094592 IDCTA_ClrTyp29Avl "BLN";
BA_ "SignalLongName" SG_ 2154094592 IDCTA_ClrTyp29Avl "Interior Dimming Color Type Available : Color Type 29 Available";
BA_ "VNSigAllNodes" SG_ 2154094592 IDCTA_ClrTyp29Avl 1;
BA_ "GenSigSendType" SG_ 2154094592 IDCTA_ClrTyp28Avl 10;
BA_ "GenSigSendOnInit" SG_ 2154094592 IDCTA_ClrTyp28Avl 1;
BA_ "PacketOrder" SG_ 2154094592 IDCTA_ClrTyp28Avl 29;
BA_ "SignalType" SG_ 2154094592 IDCTA_ClrTyp28Avl "BLN";
BA_ "SignalLongName" SG_ 2154094592 IDCTA_ClrTyp28Avl "Interior Dimming Color Type Available : Color Type 28 Available";
BA_ "VNSigAllNodes" SG_ 2154094592 IDCTA_ClrTyp28Avl 1;
BA_ "GenSigSendType" SG_ 2154094592 IDCTA_ClrTyp27Avl 10;
BA_ "GenSigSendOnInit" SG_ 2154094592 IDCTA_ClrTyp27Avl 1;
BA_ "PacketOrder" SG_ 2154094592 IDCTA_ClrTyp27Avl 28;
BA_ "SignalType" SG_ 2154094592 IDCTA_ClrTyp27Avl "BLN";
BA_ "SignalLongName" SG_ 2154094592 IDCTA_ClrTyp27Avl "Interior Dimming Color Type Available : Color Type 27 Available";
BA_ "VNSigAllNodes" SG_ 2154094592 IDCTA_ClrTyp27Avl 1;
BA_ "GenSigSendType" SG_ 2154094592 IDCTA_ClrTyp26Avl 10;
BA_ "GenSigSendOnInit" SG_ 2154094592 IDCTA_ClrTyp26Avl 1;
BA_ "PacketOrder" SG_ 2154094592 IDCTA_ClrTyp26Avl 27;
BA_ "SignalType" SG_ 2154094592 IDCTA_ClrTyp26Avl "BLN";
BA_ "SignalLongName" SG_ 2154094592 IDCTA_ClrTyp26Avl "Interior Dimming Color Type Available : Color Type 26 Available";
BA_ "VNSigAllNodes" SG_ 2154094592 IDCTA_ClrTyp26Avl 1;
BA_ "GenSigSendType" SG_ 2154094592 IDCTA_ClrTyp25Avl 10;
BA_ "GenSigSendOnInit" SG_ 2154094592 IDCTA_ClrTyp25Avl 1;
BA_ "PacketOrder" SG_ 2154094592 IDCTA_ClrTyp25Avl 26;
BA_ "SignalType" SG_ 2154094592 IDCTA_ClrTyp25Avl "BLN";
BA_ "SignalLongName" SG_ 2154094592 IDCTA_ClrTyp25Avl "Interior Dimming Color Type Available : Color Type 25 Available";
BA_ "VNSigAllNodes" SG_ 2154094592 IDCTA_ClrTyp25Avl 1;
BA_ "GenSigSendType" SG_ 2154094592 IDCTA_ClrTyp24Avl 10;
BA_ "GenSigSendOnInit" SG_ 2154094592 IDCTA_ClrTyp24Avl 1;
BA_ "PacketOrder" SG_ 2154094592 IDCTA_ClrTyp24Avl 25;
BA_ "SignalType" SG_ 2154094592 IDCTA_ClrTyp24Avl "BLN";
BA_ "SignalLongName" SG_ 2154094592 IDCTA_ClrTyp24Avl "Interior Dimming Color Type Available : Color Type 24 Available";
BA_ "VNSigAllNodes" SG_ 2154094592 IDCTA_ClrTyp24Avl 1;
BA_ "GenSigSendType" SG_ 2154094592 IDCTA_ClrTyp23Avl 10;
BA_ "GenSigSendOnInit" SG_ 2154094592 IDCTA_ClrTyp23Avl 1;
BA_ "PacketOrder" SG_ 2154094592 IDCTA_ClrTyp23Avl 24;
BA_ "SignalType" SG_ 2154094592 IDCTA_ClrTyp23Avl "BLN";
BA_ "SignalLongName" SG_ 2154094592 IDCTA_ClrTyp23Avl "Interior Dimming Color Type Available : Color Type 23 Available";
BA_ "VNSigAllNodes" SG_ 2154094592 IDCTA_ClrTyp23Avl 1;
BA_ "GenSigSendType" SG_ 2154094592 IDCTA_ClrTyp22Avl 10;
BA_ "GenSigSendOnInit" SG_ 2154094592 IDCTA_ClrTyp22Avl 1;
BA_ "PacketOrder" SG_ 2154094592 IDCTA_ClrTyp22Avl 23;
BA_ "SignalType" SG_ 2154094592 IDCTA_ClrTyp22Avl "BLN";
BA_ "SignalLongName" SG_ 2154094592 IDCTA_ClrTyp22Avl "Interior Dimming Color Type Available : Color Type 22 Available";
BA_ "VNSigAllNodes" SG_ 2154094592 IDCTA_ClrTyp22Avl 1;
BA_ "GenSigSendType" SG_ 2154094592 IDCTA_ClrTyp21Avl 10;
BA_ "GenSigSendOnInit" SG_ 2154094592 IDCTA_ClrTyp21Avl 1;
BA_ "PacketOrder" SG_ 2154094592 IDCTA_ClrTyp21Avl 22;
BA_ "SignalType" SG_ 2154094592 IDCTA_ClrTyp21Avl "BLN";
BA_ "SignalLongName" SG_ 2154094592 IDCTA_ClrTyp21Avl "Interior Dimming Color Type Available : Color Type 21 Available";
BA_ "VNSigAllNodes" SG_ 2154094592 IDCTA_ClrTyp21Avl 1;
BA_ "GenSigSendType" SG_ 2154094592 IDCTA_ClrTyp20Avl 10;
BA_ "GenSigSendOnInit" SG_ 2154094592 IDCTA_ClrTyp20Avl 1;
BA_ "PacketOrder" SG_ 2154094592 IDCTA_ClrTyp20Avl 21;
BA_ "SignalType" SG_ 2154094592 IDCTA_ClrTyp20Avl "BLN";
BA_ "SignalLongName" SG_ 2154094592 IDCTA_ClrTyp20Avl "Interior Dimming Color Type Available : Color Type 20 Available";
BA_ "VNSigAllNodes" SG_ 2154094592 IDCTA_ClrTyp20Avl 1;
BA_ "GenSigSendType" SG_ 2154094592 IDCTA_ClrTyp19Avl 10;
BA_ "GenSigSendOnInit" SG_ 2154094592 IDCTA_ClrTyp19Avl 1;
BA_ "PacketOrder" SG_ 2154094592 IDCTA_ClrTyp19Avl 20;
BA_ "SignalType" SG_ 2154094592 IDCTA_ClrTyp19Avl "BLN";
BA_ "SignalLongName" SG_ 2154094592 IDCTA_ClrTyp19Avl "Interior Dimming Color Type Available : Color Type 19 Available";
BA_ "VNSigAllNodes" SG_ 2154094592 IDCTA_ClrTyp19Avl 1;
BA_ "GenSigSendType" SG_ 2154094592 IDCTA_ClrTyp18Avl 10;
BA_ "GenSigSendOnInit" SG_ 2154094592 IDCTA_ClrTyp18Avl 1;
BA_ "PacketOrder" SG_ 2154094592 IDCTA_ClrTyp18Avl 19;
BA_ "SignalType" SG_ 2154094592 IDCTA_ClrTyp18Avl "BLN";
BA_ "SignalLongName" SG_ 2154094592 IDCTA_ClrTyp18Avl "Interior Dimming Color Type Available : Color Type 18 Available";
BA_ "VNSigAllNodes" SG_ 2154094592 IDCTA_ClrTyp18Avl 1;
BA_ "GenSigSendType" SG_ 2154094592 IDCTA_ClrTyp17Avl 10;
BA_ "GenSigSendOnInit" SG_ 2154094592 IDCTA_ClrTyp17Avl 1;
BA_ "PacketOrder" SG_ 2154094592 IDCTA_ClrTyp17Avl 18;
BA_ "SignalType" SG_ 2154094592 IDCTA_ClrTyp17Avl "BLN";
BA_ "SignalLongName" SG_ 2154094592 IDCTA_ClrTyp17Avl "Interior Dimming Color Type Available : Color Type 17 Available";
BA_ "VNSigAllNodes" SG_ 2154094592 IDCTA_ClrTyp17Avl 1;
BA_ "GenSigSendType" SG_ 2154094592 IDCTA_ClrTyp16Avl 10;
BA_ "GenSigSendOnInit" SG_ 2154094592 IDCTA_ClrTyp16Avl 1;
BA_ "PacketOrder" SG_ 2154094592 IDCTA_ClrTyp16Avl 17;
BA_ "SignalType" SG_ 2154094592 IDCTA_ClrTyp16Avl "BLN";
BA_ "SignalLongName" SG_ 2154094592 IDCTA_ClrTyp16Avl "Interior Dimming Color Type Available : Color Type 16 Available";
BA_ "VNSigAllNodes" SG_ 2154094592 IDCTA_ClrTyp16Avl 1;
BA_ "GenSigSendType" SG_ 2154094592 IDCTA_ClrTyp15Avl 10;
BA_ "GenSigSendOnInit" SG_ 2154094592 IDCTA_ClrTyp15Avl 1;
BA_ "PacketOrder" SG_ 2154094592 IDCTA_ClrTyp15Avl 16;
BA_ "SignalType" SG_ 2154094592 IDCTA_ClrTyp15Avl "BLN";
BA_ "SignalLongName" SG_ 2154094592 IDCTA_ClrTyp15Avl "Interior Dimming Color Type Available : Color Type 15 Available";
BA_ "VNSigAllNodes" SG_ 2154094592 IDCTA_ClrTyp15Avl 1;
BA_ "GenSigSendType" SG_ 2154094592 IDCTA_ClrTyp14Avl 10;
BA_ "GenSigSendOnInit" SG_ 2154094592 IDCTA_ClrTyp14Avl 1;
BA_ "PacketOrder" SG_ 2154094592 IDCTA_ClrTyp14Avl 15;
BA_ "SignalType" SG_ 2154094592 IDCTA_ClrTyp14Avl "BLN";
BA_ "SignalLongName" SG_ 2154094592 IDCTA_ClrTyp14Avl "Interior Dimming Color Type Available : Color Type 14 Available";
BA_ "VNSigAllNodes" SG_ 2154094592 IDCTA_ClrTyp14Avl 1;
BA_ "GenSigSendType" SG_ 2154094592 IDCTA_ClrTyp13Avl 10;
BA_ "GenSigSendOnInit" SG_ 2154094592 IDCTA_ClrTyp13Avl 1;
BA_ "PacketOrder" SG_ 2154094592 IDCTA_ClrTyp13Avl 14;
BA_ "SignalType" SG_ 2154094592 IDCTA_ClrTyp13Avl "BLN";
BA_ "SignalLongName" SG_ 2154094592 IDCTA_ClrTyp13Avl "Interior Dimming Color Type Available : Color Type 13 Available";
BA_ "VNSigAllNodes" SG_ 2154094592 IDCTA_ClrTyp13Avl 1;
BA_ "GenSigSendType" SG_ 2154094592 IDCTA_ClrTyp12Avl 10;
BA_ "GenSigSendOnInit" SG_ 2154094592 IDCTA_ClrTyp12Avl 1;
BA_ "PacketOrder" SG_ 2154094592 IDCTA_ClrTyp12Avl 13;
BA_ "SignalType" SG_ 2154094592 IDCTA_ClrTyp12Avl "BLN";
BA_ "SignalLongName" SG_ 2154094592 IDCTA_ClrTyp12Avl "Interior Dimming Color Type Available : Color Type 12 Available";
BA_ "VNSigAllNodes" SG_ 2154094592 IDCTA_ClrTyp12Avl 1;
BA_ "GenSigSendType" SG_ 2154094592 IDCTA_ClrTyp11Avl 10;
BA_ "GenSigSendOnInit" SG_ 2154094592 IDCTA_ClrTyp11Avl 1;
BA_ "PacketOrder" SG_ 2154094592 IDCTA_ClrTyp11Avl 12;
BA_ "SignalType" SG_ 2154094592 IDCTA_ClrTyp11Avl "BLN";
BA_ "SignalLongName" SG_ 2154094592 IDCTA_ClrTyp11Avl "Interior Dimming Color Type Available : Color Type 11 Available";
BA_ "VNSigAllNodes" SG_ 2154094592 IDCTA_ClrTyp11Avl 1;
BA_ "GenSigSendType" SG_ 2154094592 IDCTA_ClrTyp10Avl 10;
BA_ "GenSigSendOnInit" SG_ 2154094592 IDCTA_ClrTyp10Avl 1;
BA_ "PacketOrder" SG_ 2154094592 IDCTA_ClrTyp10Avl 11;
BA_ "SignalType" SG_ 2154094592 IDCTA_ClrTyp10Avl "BLN";
BA_ "SignalLongName" SG_ 2154094592 IDCTA_ClrTyp10Avl "Interior Dimming Color Type Available : Color Type 10 Available";
BA_ "VNSigAllNodes" SG_ 2154094592 IDCTA_ClrTyp10Avl 1;
BA_ "GenSigSendType" SG_ 2154094592 IDCTA_ClrTyp9Avl 10;
BA_ "GenSigSendOnInit" SG_ 2154094592 IDCTA_ClrTyp9Avl 1;
BA_ "PacketOrder" SG_ 2154094592 IDCTA_ClrTyp9Avl 10;
BA_ "SignalType" SG_ 2154094592 IDCTA_ClrTyp9Avl "BLN";
BA_ "SignalLongName" SG_ 2154094592 IDCTA_ClrTyp9Avl "Interior Dimming Color Type Available : Color Type 9 Available";
BA_ "VNSigAllNodes" SG_ 2154094592 IDCTA_ClrTyp9Avl 1;
BA_ "GenSigSendType" SG_ 2154094592 IDCTA_ClrTyp8Avl 10;
BA_ "GenSigSendOnInit" SG_ 2154094592 IDCTA_ClrTyp8Avl 1;
BA_ "PacketOrder" SG_ 2154094592 IDCTA_ClrTyp8Avl 9;
BA_ "SignalType" SG_ 2154094592 IDCTA_ClrTyp8Avl "BLN";
BA_ "SignalLongName" SG_ 2154094592 IDCTA_ClrTyp8Avl "Interior Dimming Color Type Available : Color Type 8 Available";
BA_ "VNSigAllNodes" SG_ 2154094592 IDCTA_ClrTyp8Avl 1;
BA_ "GenSigSendType" SG_ 2154094592 IDCTA_ClrTyp7Avl 10;
BA_ "GenSigSendOnInit" SG_ 2154094592 IDCTA_ClrTyp7Avl 1;
BA_ "PacketOrder" SG_ 2154094592 IDCTA_ClrTyp7Avl 8;
BA_ "SignalType" SG_ 2154094592 IDCTA_ClrTyp7Avl "BLN";
BA_ "SignalLongName" SG_ 2154094592 IDCTA_ClrTyp7Avl "Interior Dimming Color Type Available : Color Type 7 Available";
BA_ "VNSigAllNodes" SG_ 2154094592 IDCTA_ClrTyp7Avl 1;
BA_ "GenSigSendType" SG_ 2154094592 IDCTA_ClrTyp6Avl 10;
BA_ "GenSigSendOnInit" SG_ 2154094592 IDCTA_ClrTyp6Avl 1;
BA_ "PacketOrder" SG_ 2154094592 IDCTA_ClrTyp6Avl 7;
BA_ "SignalType" SG_ 2154094592 IDCTA_ClrTyp6Avl "BLN";
BA_ "SignalLongName" SG_ 2154094592 IDCTA_ClrTyp6Avl "Interior Dimming Color Type Available : Color Type 6 Available";
BA_ "VNSigAllNodes" SG_ 2154094592 IDCTA_ClrTyp6Avl 1;
BA_ "GenSigSendType" SG_ 2154094592 IDCTA_ClrTyp5Avl 10;
BA_ "GenSigSendOnInit" SG_ 2154094592 IDCTA_ClrTyp5Avl 1;
BA_ "PacketOrder" SG_ 2154094592 IDCTA_ClrTyp5Avl 6;
BA_ "SignalType" SG_ 2154094592 IDCTA_ClrTyp5Avl "BLN";
BA_ "SignalLongName" SG_ 2154094592 IDCTA_ClrTyp5Avl "Interior Dimming Color Type Available : Color Type 5 Available";
BA_ "VNSigAllNodes" SG_ 2154094592 IDCTA_ClrTyp5Avl 1;
BA_ "GenSigSendType" SG_ 2154094592 IDCTA_ClrTyp4Avl 10;
BA_ "GenSigSendOnInit" SG_ 2154094592 IDCTA_ClrTyp4Avl 1;
BA_ "PacketOrder" SG_ 2154094592 IDCTA_ClrTyp4Avl 5;
BA_ "SignalType" SG_ 2154094592 IDCTA_ClrTyp4Avl "BLN";
BA_ "SignalLongName" SG_ 2154094592 IDCTA_ClrTyp4Avl "Interior Dimming Color Type Available : Color Type 4 Available";
BA_ "VNSigAllNodes" SG_ 2154094592 IDCTA_ClrTyp4Avl 1;
BA_ "GenSigSendType" SG_ 2154094592 IDCTA_ClrTyp3Avl 10;
BA_ "GenSigSendOnInit" SG_ 2154094592 IDCTA_ClrTyp3Avl 1;
BA_ "PacketOrder" SG_ 2154094592 IDCTA_ClrTyp3Avl 4;
BA_ "SignalType" SG_ 2154094592 IDCTA_ClrTyp3Avl "BLN";
BA_ "SignalLongName" SG_ 2154094592 IDCTA_ClrTyp3Avl "Interior Dimming Color Type Available : Color Type 3 Available";
BA_ "VNSigAllNodes" SG_ 2154094592 IDCTA_ClrTyp3Avl 1;
BA_ "GenSigSendType" SG_ 2154094592 IDCTA_ClrTyp2Avl 10;
BA_ "GenSigSendOnInit" SG_ 2154094592 IDCTA_ClrTyp2Avl 1;
BA_ "PacketOrder" SG_ 2154094592 IDCTA_ClrTyp2Avl 3;
BA_ "SignalType" SG_ 2154094592 IDCTA_ClrTyp2Avl "BLN";
BA_ "SignalLongName" SG_ 2154094592 IDCTA_ClrTyp2Avl "Interior Dimming Color Type Available : Color Type 2 Available";
BA_ "VNSigAllNodes" SG_ 2154094592 IDCTA_ClrTyp2Avl 1;
BA_ "GenSigSendType" SG_ 2154094592 IDCTA_ClrTyp1Avl 10;
BA_ "GenSigSendOnInit" SG_ 2154094592 IDCTA_ClrTyp1Avl 1;
BA_ "PacketOrder" SG_ 2154094592 IDCTA_ClrTyp1Avl 2;
BA_ "SignalType" SG_ 2154094592 IDCTA_ClrTyp1Avl "BLN";
BA_ "SignalLongName" SG_ 2154094592 IDCTA_ClrTyp1Avl "Interior Dimming Color Type Available : Color Type 1 Available";
BA_ "VNSigAllNodes" SG_ 2154094592 IDCTA_ClrTyp1Avl 1;
BA_ "GenSigSendType" SG_ 2154094592 IDCTA_OffAvl 10;
BA_ "GenSigSendOnInit" SG_ 2154094592 IDCTA_OffAvl 1;
BA_ "PacketOrder" SG_ 2154094592 IDCTA_OffAvl 1;
BA_ "SignalType" SG_ 2154094592 IDCTA_OffAvl "BLN";
BA_ "SignalLongName" SG_ 2154094592 IDCTA_OffAvl "Interior Dimming Color Type Available : Off Available";
BA_ "VNSigAllNodes" SG_ 2154094592 IDCTA_OffAvl 1;
BA_ "GenSigSendType" SG_ 2154094592 IDATA_AnmTyp14Avl 10;
BA_ "GenSigSendOnInit" SG_ 2154094592 IDATA_AnmTyp14Avl 1;
BA_ "SignalType" SG_ 2154094592 IDATA_AnmTyp14Avl "BLN";
BA_ "PacketOrder" SG_ 2154094592 IDATA_AnmTyp14Avl 15;
BA_ "SignalLongName" SG_ 2154094592 IDATA_AnmTyp14Avl "Interior Dimming Animation Type Available : Animation Type 14 Available";
BA_ "VNSigAllNodes" SG_ 2154094592 IDATA_AnmTyp14Avl 1;
BA_ "GenSigSendType" SG_ 2154094592 IDATA_AnmTyp13Avl 10;
BA_ "GenSigSendOnInit" SG_ 2154094592 IDATA_AnmTyp13Avl 1;
BA_ "SignalType" SG_ 2154094592 IDATA_AnmTyp13Avl "BLN";
BA_ "PacketOrder" SG_ 2154094592 IDATA_AnmTyp13Avl 14;
BA_ "SignalLongName" SG_ 2154094592 IDATA_AnmTyp13Avl "Interior Dimming Animation Type Available : Animation Type 13 Available";
BA_ "VNSigAllNodes" SG_ 2154094592 IDATA_AnmTyp13Avl 1;
BA_ "GenSigSendType" SG_ 2154094592 IDATA_AnmTyp12Avl 10;
BA_ "GenSigSendOnInit" SG_ 2154094592 IDATA_AnmTyp12Avl 1;
BA_ "SignalType" SG_ 2154094592 IDATA_AnmTyp12Avl "BLN";
BA_ "PacketOrder" SG_ 2154094592 IDATA_AnmTyp12Avl 13;
BA_ "SignalLongName" SG_ 2154094592 IDATA_AnmTyp12Avl "Interior Dimming Animation Type Available : Animation Type 12 Available";
BA_ "VNSigAllNodes" SG_ 2154094592 IDATA_AnmTyp12Avl 1;
BA_ "GenSigSendType" SG_ 2154094592 IDATA_AnmTyp11Avl 10;
BA_ "GenSigSendOnInit" SG_ 2154094592 IDATA_AnmTyp11Avl 1;
BA_ "SignalType" SG_ 2154094592 IDATA_AnmTyp11Avl "BLN";
BA_ "PacketOrder" SG_ 2154094592 IDATA_AnmTyp11Avl 12;
BA_ "SignalLongName" SG_ 2154094592 IDATA_AnmTyp11Avl "Interior Dimming Animation Type Available : Animation Type 11 Available";
BA_ "VNSigAllNodes" SG_ 2154094592 IDATA_AnmTyp11Avl 1;
BA_ "GenSigSendType" SG_ 2154094592 IDATA_AnmTyp10Avl 10;
BA_ "GenSigSendOnInit" SG_ 2154094592 IDATA_AnmTyp10Avl 1;
BA_ "SignalType" SG_ 2154094592 IDATA_AnmTyp10Avl "BLN";
BA_ "PacketOrder" SG_ 2154094592 IDATA_AnmTyp10Avl 11;
BA_ "SignalLongName" SG_ 2154094592 IDATA_AnmTyp10Avl "Interior Dimming Animation Type Available : Animation Type 10 Available";
BA_ "VNSigAllNodes" SG_ 2154094592 IDATA_AnmTyp10Avl 1;
BA_ "GenSigSendType" SG_ 2154094592 IDATA_AnmTyp9Avl 10;
BA_ "GenSigSendOnInit" SG_ 2154094592 IDATA_AnmTyp9Avl 1;
BA_ "SignalType" SG_ 2154094592 IDATA_AnmTyp9Avl "BLN";
BA_ "PacketOrder" SG_ 2154094592 IDATA_AnmTyp9Avl 10;
BA_ "SignalLongName" SG_ 2154094592 IDATA_AnmTyp9Avl "Interior Dimming Animation Type Available : Animation Type 9 Available";
BA_ "VNSigAllNodes" SG_ 2154094592 IDATA_AnmTyp9Avl 1;
BA_ "GenSigSendType" SG_ 2154094592 IDATA_AnmTyp8Avl 10;
BA_ "GenSigSendOnInit" SG_ 2154094592 IDATA_AnmTyp8Avl 1;
BA_ "SignalType" SG_ 2154094592 IDATA_AnmTyp8Avl "BLN";
BA_ "PacketOrder" SG_ 2154094592 IDATA_AnmTyp8Avl 9;
BA_ "SignalLongName" SG_ 2154094592 IDATA_AnmTyp8Avl "Interior Dimming Animation Type Available : Animation Type 8 Available";
BA_ "VNSigAllNodes" SG_ 2154094592 IDATA_AnmTyp8Avl 1;
BA_ "GenSigSendType" SG_ 2154094592 IDATA_AnmTyp7Avl 10;
BA_ "GenSigSendOnInit" SG_ 2154094592 IDATA_AnmTyp7Avl 1;
BA_ "SignalType" SG_ 2154094592 IDATA_AnmTyp7Avl "BLN";
BA_ "PacketOrder" SG_ 2154094592 IDATA_AnmTyp7Avl 8;
BA_ "SignalLongName" SG_ 2154094592 IDATA_AnmTyp7Avl "Interior Dimming Animation Type Available : Animation Type 7 Available";
BA_ "VNSigAllNodes" SG_ 2154094592 IDATA_AnmTyp7Avl 1;
BA_ "GenSigSendType" SG_ 2154094592 IDATA_AnmTyp6Avl 10;
BA_ "GenSigSendOnInit" SG_ 2154094592 IDATA_AnmTyp6Avl 1;
BA_ "SignalType" SG_ 2154094592 IDATA_AnmTyp6Avl "BLN";
BA_ "PacketOrder" SG_ 2154094592 IDATA_AnmTyp6Avl 7;
BA_ "SignalLongName" SG_ 2154094592 IDATA_AnmTyp6Avl "Interior Dimming Animation Type Available : Animation Type 6 Available";
BA_ "VNSigAllNodes" SG_ 2154094592 IDATA_AnmTyp6Avl 1;
BA_ "GenSigSendType" SG_ 2154094592 IDATA_AnmTyp5Avl 10;
BA_ "GenSigSendOnInit" SG_ 2154094592 IDATA_AnmTyp5Avl 1;
BA_ "SignalType" SG_ 2154094592 IDATA_AnmTyp5Avl "BLN";
BA_ "PacketOrder" SG_ 2154094592 IDATA_AnmTyp5Avl 6;
BA_ "SignalLongName" SG_ 2154094592 IDATA_AnmTyp5Avl "Interior Dimming Animation Type Available : Animation Type 5 Available";
BA_ "VNSigAllNodes" SG_ 2154094592 IDATA_AnmTyp5Avl 1;
BA_ "GenSigSendType" SG_ 2154094592 IDATA_AnmTyp4Avl 10;
BA_ "GenSigSendOnInit" SG_ 2154094592 IDATA_AnmTyp4Avl 1;
BA_ "SignalType" SG_ 2154094592 IDATA_AnmTyp4Avl "BLN";
BA_ "PacketOrder" SG_ 2154094592 IDATA_AnmTyp4Avl 5;
BA_ "SignalLongName" SG_ 2154094592 IDATA_AnmTyp4Avl "Interior Dimming Animation Type Available : Animation Type 4 Available";
BA_ "VNSigAllNodes" SG_ 2154094592 IDATA_AnmTyp4Avl 1;
BA_ "GenSigSendType" SG_ 2154094592 IDATA_AnmTyp3Avl 10;
BA_ "GenSigSendOnInit" SG_ 2154094592 IDATA_AnmTyp3Avl 1;
BA_ "SignalType" SG_ 2154094592 IDATA_AnmTyp3Avl "BLN";
BA_ "PacketOrder" SG_ 2154094592 IDATA_AnmTyp3Avl 4;
BA_ "SignalLongName" SG_ 2154094592 IDATA_AnmTyp3Avl "Interior Dimming Animation Type Available : Animation Type 3 Available";
BA_ "VNSigAllNodes" SG_ 2154094592 IDATA_AnmTyp3Avl 1;
BA_ "GenSigSendType" SG_ 2154094592 IDATA_AnmTyp2Avl 10;
BA_ "GenSigSendOnInit" SG_ 2154094592 IDATA_AnmTyp2Avl 1;
BA_ "SignalType" SG_ 2154094592 IDATA_AnmTyp2Avl "BLN";
BA_ "PacketOrder" SG_ 2154094592 IDATA_AnmTyp2Avl 3;
BA_ "SignalLongName" SG_ 2154094592 IDATA_AnmTyp2Avl "Interior Dimming Animation Type Available : Animation Type 2 Available";
BA_ "VNSigAllNodes" SG_ 2154094592 IDATA_AnmTyp2Avl 1;
BA_ "GenSigSendType" SG_ 2154094592 IDATA_AnmTyp1Avl 10;
BA_ "GenSigSendOnInit" SG_ 2154094592 IDATA_AnmTyp1Avl 1;
BA_ "SignalType" SG_ 2154094592 IDATA_AnmTyp1Avl "BLN";
BA_ "PacketOrder" SG_ 2154094592 IDATA_AnmTyp1Avl 2;
BA_ "SignalLongName" SG_ 2154094592 IDATA_AnmTyp1Avl "Interior Dimming Animation Type Available : Animation Type 1 Available";
BA_ "VNSigAllNodes" SG_ 2154094592 IDATA_AnmTyp1Avl 1;
BA_ "GenSigSendType" SG_ 2154094592 IDATA_OffAvl 10;
BA_ "GenSigSendOnInit" SG_ 2154094592 IDATA_OffAvl 1;
BA_ "SignalType" SG_ 2154094592 IDATA_OffAvl "BLN";
BA_ "PacketOrder" SG_ 2154094592 IDATA_OffAvl 1;
BA_ "SignalLongName" SG_ 2154094592 IDATA_OffAvl "Interior Dimming Animation Type Available : Off Available";
BA_ "VNSigAllNodes" SG_ 2154094592 IDATA_OffAvl 1;
BA_ "GenSigSendType" SG_ 2154094592 AdjPdlMotInhbtd 10;
BA_ "SignalType" SG_ 2154094592 AdjPdlMotInhbtd "BLN";
BA_ "SignalLongName" SG_ 2154094592 AdjPdlMotInhbtd "Adjustable Pedal Motion Inhibited";
BA_ "VNSigAllNodes" SG_ 2154094592 AdjPdlMotInhbtd 1;
BA_ "GenSigSendType" SG_ 2154061824 WndOprAlwd 10;
BA_ "SignalType" SG_ 2154061824 WndOprAlwd "BLN";
BA_ "SignalLongName" SG_ 2154061824 WndOprAlwd "Window Operation Allowed";
BA_ "VNSigAllNodes" SG_ 2154061824 WndOprAlwd 1;
BA_ "GenSigSendType" SG_ 2154061824 RrDrUnlckIO 10;
BA_ "SignalType" SG_ 2154061824 RrDrUnlckIO "BLN";
BA_ "SignalLongName" SG_ 2154061824 RrDrUnlckIO "Rear Door Unlock Indication On";
BA_ "VNSigAllNodes" SG_ 2154061824 RrDrUnlckIO 1;
BA_ "GenSigSendType" SG_ 2154061824 RmtWndMvmntAtv 10;
BA_ "SignalType" SG_ 2154061824 RmtWndMvmntAtv "BLN";
BA_ "SignalLongName" SG_ 2154061824 RmtWndMvmntAtv "Remote Window Movement Active";
BA_ "VNSigAllNodes" SG_ 2154061824 RmtWndMvmntAtv 1;
BA_ "GenSigSendType" SG_ 2154061824 RRWndNtNrmIndOn 10;
BA_ "SignalType" SG_ 2154061824 RRWndNtNrmIndOn "BLN";
BA_ "SignalLongName" SG_ 2154061824 RRWndNtNrmIndOn "Rear Right Window Not Normalized Indication On";
BA_ "VNSigAllNodes" SG_ 2154061824 RRWndNtNrmIndOn 1;
BA_ "GenSigSendType" SG_ 2154061824 RLWndNtNrmIndOn 10;
BA_ "SignalType" SG_ 2154061824 RLWndNtNrmIndOn "BLN";
BA_ "SignalLongName" SG_ 2154061824 RLWndNtNrmIndOn "Rear Left Window Not Normalized Indication On";
BA_ "VNSigAllNodes" SG_ 2154061824 RLWndNtNrmIndOn 1;
BA_ "GenSigSendType" SG_ 2154061824 DrWndNtNrmIndOn 10;
BA_ "GenSigSendOnInit" SG_ 2154061824 DrWndNtNrmIndOn 2;
BA_ "SignalType" SG_ 2154061824 DrWndNtNrmIndOn "BLN";
BA_ "SignalLongName" SG_ 2154061824 DrWndNtNrmIndOn "Driver Window Not Normalized Indication On";
BA_ "VNSigAllNodes" SG_ 2154061824 DrWndNtNrmIndOn 1;
BA_ "GenSigSendType" SG_ 2154061824 PsWndNtNrmIndOn 10;
BA_ "SignalType" SG_ 2154061824 PsWndNtNrmIndOn "BLN";
BA_ "SignalLongName" SG_ 2154061824 PsWndNtNrmIndOn "Passenger Window Not Normalized Indication On";
BA_ "VNSigAllNodes" SG_ 2154061824 PsWndNtNrmIndOn 1;
BA_ "GenSigDeltaValue" SG_ 2155036672 ClmtCtrlTrgtTemp 1;
BA_ "GenSigSendType" SG_ 2155036672 ClmtCtrlTrgtTemp 12;
BA_ "SignalType" SG_ 2155036672 ClmtCtrlTrgtTemp "UNM";
BA_ "SignalLongName" SG_ 2155036672 ClmtCtrlTrgtTemp "Climate Control Target Temperature";
BA_ "VNSigAllNodes" SG_ 2155036672 ClmtCtrlTrgtTemp 1;
BA_ "GenSigSendType" SG_ 2155036672 ACCompModReq 10;
BA_ "SignalType" SG_ 2155036672 ACCompModReq "ENM";
BA_ "SignalLongName" SG_ 2155036672 ACCompModReq "Air Conditioning Compressor Mode Request";
BA_ "VNSigAllNodes" SG_ 2155036672 ACCompModReq 1;
BA_ "GenSigSendType" SG_ 2155036672 ACCompNormLdV 10;
BA_ "SignalType" SG_ 2155036672 ACCompNormLdV "ENM";
BA_ "SignalLongName" SG_ 2155036672 ACCompNormLdV "Air Conditioning Compressor Normalized Load Validity";
BA_ "VNSigAllNodes" SG_ 2155036672 ACCompNormLdV 1;
BA_ "GenSigDeltaValue" SG_ 2155036672 ACCompNormLd 1;
BA_ "GenSigSendType" SG_ 2155036672 ACCompNormLd 12;
BA_ "SignalType" SG_ 2155036672 ACCompNormLd "UNM";
BA_ "SignalLongName" SG_ 2155036672 ACCompNormLd "Air Conditioning Compressor Normalized Load";
BA_ "VNSigAllNodes" SG_ 2155036672 ACCompNormLd 1;
BA_ "GenSigSendType" SG_ 2155036672 ACCmEngRunReq 10;
BA_ "SignalType" SG_ 2155036672 ACCmEngRunReq "ENM";
BA_ "SignalLongName" SG_ 2155036672 ACCmEngRunReq "Air Conditioning Compressor Engine Run Request";
BA_ "VNSigAllNodes" SG_ 2155036672 ACCmEngRunReq 1;
BA_ "GenSigSendType" SG_ 2155036672 ACCmpsrFldOn 10;
BA_ "SignalType" SG_ 2155036672 ACCmpsrFldOn "BLN";
BA_ "SignalLongName" SG_ 2155036672 ACCmpsrFldOn "Air Conditioning Compressor Failed On";
BA_ "VNSigAllNodes" SG_ 2155036672 ACCmpsrFldOn 1;
BA_ "GenSigSendType" SG_ 2151112704 FrPasSeatbltRemOccSt 10;
BA_ "GenSigSendOnInit" SG_ 2151112704 FrPasSeatbltRemOccSt 2;
BA_ "SignalType" SG_ 2151112704 FrPasSeatbltRemOccSt "ENM";
BA_ "SignalLongName" SG_ 2151112704 FrPasSeatbltRemOccSt "Front Passenger Seatbelt Reminder Occupancy Status";
BA_ "VNSigAllNodes" SG_ 2151112704 FrPasSeatbltRemOccSt 1;
BA_ "GenSigSendType" SG_ 2151112704 FrPasSeatResCtrlOccStV 10;
BA_ "GenSigSendOnInit" SG_ 2151112704 FrPasSeatResCtrlOccStV 2;
BA_ "SignalType" SG_ 2151112704 FrPasSeatResCtrlOccStV "ENM";
BA_ "SignalLongName" SG_ 2151112704 FrPasSeatResCtrlOccStV "Front Passenger Seat Restraint Control Occupancy Status Validity";
BA_ "VNSigAllNodes" SG_ 2151112704 FrPasSeatResCtrlOccStV 1;
BA_ "GenSigSendType" SG_ 2151112704 FrPasSeatResCtrlOccSt 10;
BA_ "GenSigSendOnInit" SG_ 2151112704 FrPasSeatResCtrlOccSt 2;
BA_ "SignalType" SG_ 2151112704 FrPasSeatResCtrlOccSt "ENM";
BA_ "SignalLongName" SG_ 2151112704 FrPasSeatResCtrlOccSt "Front Passenger Seat Restraint Control Occupancy Status";
BA_ "VNSigAllNodes" SG_ 2151112704 FrPasSeatResCtrlOccSt 1;
BA_ "GenSigSendType" SG_ 2151112704 FrPsSeatOccSnsOpMd 10;
BA_ "GenSigSendOnInit" SG_ 2151112704 FrPsSeatOccSnsOpMd 2;
BA_ "SignalType" SG_ 2151112704 FrPsSeatOccSnsOpMd "ENM";
BA_ "SignalLongName" SG_ 2151112704 FrPsSeatOccSnsOpMd "Front Passenger Seat Occupancy Sensing Operating Mode";
BA_ "VNSigAllNodes" SG_ 2151112704 FrPsSeatOccSnsOpMd 1;
BA_ "GenSigSendType" SG_ 2151112704 FrPsSeatOccFltSt 10;
BA_ "GenSigSendOnInit" SG_ 2151112704 FrPsSeatOccFltSt 2;
BA_ "SignalType" SG_ 2151112704 FrPsSeatOccFltSt "ENM";
BA_ "SignalLongName" SG_ 2151112704 FrPsSeatOccFltSt "Front Passenger Seat Occupancy Fault Status";
BA_ "VNSigAllNodes" SG_ 2151112704 FrPsSeatOccFltSt 1;
BA_ "GenSigSendType" SG_ 2151112704 FrntPassClass 10;
BA_ "GenSigSendOnInit" SG_ 2151112704 FrntPassClass 2;
BA_ "SignalType" SG_ 2151112704 FrntPassClass "ENM";
BA_ "SignalLongName" SG_ 2151112704 FrntPassClass "Front Passenger Classification";
BA_ "VNSigAllNodes" SG_ 2151112704 FrntPassClass 1;
BA_ "GenSigSendType" SG_ 2150301696 WlcAnmReq 10;
BA_ "SignalType" SG_ 2150301696 WlcAnmReq "BLN";
BA_ "SignalLongName" SG_ 2150301696 WlcAnmReq "Welcome Animation Request";
BA_ "VNSigAllNodes" SG_ 2150301696 WlcAnmReq 1;
BA_ "GenSigDeltaValue" SG_ 2158895104 ODI_CntrStck2RSD 1;
BA_ "GenSigSendType" SG_ 2158895104 ODI_CntrStck2RSD 12;
BA_ "VNSigInfotainment" SG_ 2158895104 ODI_CntrStck2RSD 1;
BA_ "SignalType" SG_ 2158895104 ODI_CntrStck2RSD "UNM";
BA_ "SignalLongName" SG_ 2158895104 ODI_CntrStck2RSD "Open Display Interface Centerstack 2 Rear Seat Display";
BA_ "VNSigAllNodes" SG_ 2158895104 ODI_CntrStck2RSD 1;
BA_ "GenSigDeltaValue" SG_ 2151350272 APAIconFilPctRq 1;
BA_ "GenSigSendType" SG_ 2151350272 APAIconFilPctRq 12;
BA_ "SignalType" SG_ 2151350272 APAIconFilPctRq "UNM";
BA_ "SignalLongName" SG_ 2151350272 APAIconFilPctRq "Advanced Park Assist Icon Fill Percent Request";
BA_ "VNSigAllNodes" SG_ 2151350272 APAIconFilPctRq 1;
BA_ "GenSigSendType" SG_ 2151350272 APAIconDispRq 10;
BA_ "SignalType" SG_ 2151350272 APAIconDispRq "ENM";
BA_ "SignalLongName" SG_ 2151350272 APAIconDispRq "Advanced Park Assist Icon Display Request";
BA_ "VNSigAllNodes" SG_ 2151350272 APAIconDispRq 1;
BA_ "GenSigDeltaValue" SG_ 2151350272 FPAHptcStVbnRqSeqN 1;
BA_ "GenSigSendType" SG_ 2151350272 FPAHptcStVbnRqSeqN 12;
BA_ "SignalType" SG_ 2151350272 FPAHptcStVbnRqSeqN "UNM";
BA_ "SignalLongName" SG_ 2151350272 FPAHptcStVbnRqSeqN "Front Park Assist Haptic Seat Vibration Request Sequence Number";
BA_ "VNSigAllNodes" SG_ 2151350272 FPAHptcStVbnRqSeqN 1;
BA_ "GenSigDeltaValue" SG_ 2151350272 FPAHptcStVbnReq 1;
BA_ "GenSigSendType" SG_ 2151350272 FPAHptcStVbnReq 12;
BA_ "SignalType" SG_ 2151350272 FPAHptcStVbnReq "UNM";
BA_ "SignalLongName" SG_ 2151350272 FPAHptcStVbnReq "Front Park Assist Haptic Seat Vibration Request";
BA_ "VNSigAllNodes" SG_ 2151350272 FPAHptcStVbnReq 1;
BA_ "GenSigSendType" SG_ 2151317504 PrkAstRrSysStat 10;
BA_ "SignalType" SG_ 2151317504 PrkAstRrSysStat "ENM";
BA_ "SignalLongName" SG_ 2151317504 PrkAstRrSysStat "Parking Assistance Rear System Status";
BA_ "VNSigAllNodes" SG_ 2151317504 PrkAstRrSysStat 1;
BA_ "GenSigSendType" SG_ 2151317504 PARrRgn4ObjStat 10;
BA_ "SignalType" SG_ 2151317504 PARrRgn4ObjStat "ENM";
BA_ "SignalLongName" SG_ 2151317504 PARrRgn4ObjStat "Parking Assistance Rear Region 4 Object Status";
BA_ "VNSigAllNodes" SG_ 2151317504 PARrRgn4ObjStat 1;
BA_ "GenSigSendType" SG_ 2151317504 PARrRgn3ObjStat 10;
BA_ "SignalType" SG_ 2151317504 PARrRgn3ObjStat "ENM";
BA_ "SignalLongName" SG_ 2151317504 PARrRgn3ObjStat "Parking Assistance Rear Region 3 Object Status";
BA_ "VNSigAllNodes" SG_ 2151317504 PARrRgn3ObjStat 1;
BA_ "GenSigSendType" SG_ 2151317504 PARrRgn2ObjStat 10;
BA_ "SignalType" SG_ 2151317504 PARrRgn2ObjStat "ENM";
BA_ "SignalLongName" SG_ 2151317504 PARrRgn2ObjStat "Parking Assistance Rear Region 2 Object Status";
BA_ "VNSigAllNodes" SG_ 2151317504 PARrRgn2ObjStat 1;
BA_ "GenSigSendType" SG_ 2151317504 PARrRgn1ObjStat 10;
BA_ "SignalType" SG_ 2151317504 PARrRgn1ObjStat "ENM";
BA_ "SignalLongName" SG_ 2151317504 PARrRgn1ObjStat "Parking Assistance Rear Region 1 Object Status";
BA_ "VNSigAllNodes" SG_ 2151317504 PARrRgn1ObjStat 1;
BA_ "GenSigDeltaValue" SG_ 2151317504 PrkAsstRrExtdDist 1;
BA_ "GenSigSendType" SG_ 2151317504 PrkAsstRrExtdDist 12;
BA_ "SignalType" SG_ 2151317504 PrkAsstRrExtdDist "UNM";
BA_ "SignalLongName" SG_ 2151317504 PrkAsstRrExtdDist "Parking Assistance Rear Extended Distance";
BA_ "VNSigAllNodes" SG_ 2151317504 PrkAsstRrExtdDist 1;
BA_ "GenSigSendType" SG_ 2151301120 PrkAstAdvSysAct 10;
BA_ "SignalType" SG_ 2151301120 PrkAstAdvSysAct "BLN";
BA_ "SignalLongName" SG_ 2151301120 PrkAstAdvSysAct "Parking Assistance Advanced  System Active";
BA_ "VNSigAllNodes" SG_ 2151301120 PrkAstAdvSysAct 1;
BA_ "GenSigSendType" SG_ 2151301120 PrkAstFrSysStat 10;
BA_ "GenSigSendOnInit" SG_ 2151301120 PrkAstFrSysStat 2;
BA_ "SignalType" SG_ 2151301120 PrkAstFrSysStat "ENM";
BA_ "SignalLongName" SG_ 2151301120 PrkAstFrSysStat "Parking Assistance Front System Status";
BA_ "VNSigAllNodes" SG_ 2151301120 PrkAstFrSysStat 1;
BA_ "GenSigSendType" SG_ 2151301120 PAFrtRgn4ObjStat 10;
BA_ "SignalType" SG_ 2151301120 PAFrtRgn4ObjStat "ENM";
BA_ "SignalLongName" SG_ 2151301120 PAFrtRgn4ObjStat "Parking Assistance Front Region 4 Object Status";
BA_ "VNSigAllNodes" SG_ 2151301120 PAFrtRgn4ObjStat 1;
BA_ "GenSigSendType" SG_ 2151301120 PAFrtRgn3ObjStat 10;
BA_ "SignalType" SG_ 2151301120 PAFrtRgn3ObjStat "ENM";
BA_ "SignalLongName" SG_ 2151301120 PAFrtRgn3ObjStat "Parking Assistance Front Region 3 Object Status";
BA_ "VNSigAllNodes" SG_ 2151301120 PAFrtRgn3ObjStat 1;
BA_ "GenSigSendType" SG_ 2151301120 PAFrtRgn2ObjStat 10;
BA_ "SignalType" SG_ 2151301120 PAFrtRgn2ObjStat "ENM";
BA_ "SignalLongName" SG_ 2151301120 PAFrtRgn2ObjStat "Parking Assistance Front Region 2 Object Status";
BA_ "VNSigAllNodes" SG_ 2151301120 PAFrtRgn2ObjStat 1;
BA_ "GenSigSendType" SG_ 2151301120 PAFrtRgn1ObjStat 10;
BA_ "SignalType" SG_ 2151301120 PAFrtRgn1ObjStat "ENM";
BA_ "SignalLongName" SG_ 2151301120 PAFrtRgn1ObjStat "Parking Assistance Front Region 1 Object Status";
BA_ "VNSigAllNodes" SG_ 2151301120 PAFrtRgn1ObjStat 1;
BA_ "GenSigDeltaValue" SG_ 2151301120 PrkAsstFrtExtdDist 1;
BA_ "GenSigSendType" SG_ 2151301120 PrkAsstFrtExtdDist 12;
BA_ "SignalType" SG_ 2151301120 PrkAsstFrtExtdDist "UNM";
BA_ "SignalLongName" SG_ 2151301120 PrkAsstFrtExtdDist "Parking Assistance Front Extended Distance";
BA_ "VNSigAllNodes" SG_ 2151301120 PrkAsstFrtExtdDist 1;
BA_ "GenSigSendType" SG_ 2151301120 PrkAsstRrOffIO 10;
BA_ "SignalType" SG_ 2151301120 PrkAsstRrOffIO "BLN";
BA_ "SignalLongName" SG_ 2151301120 PrkAsstRrOffIO "Parking Assistance Rear Off Indication On";
BA_ "VNSigAllNodes" SG_ 2151301120 PrkAsstRrOffIO 1;
BA_ "GenSigSendType" SG_ 2152775680 CrgBdVwLtCustSetAvl 10;
BA_ "GenSigSendOnInit" SG_ 2152775680 CrgBdVwLtCustSetAvl 2;
BA_ "SignalType" SG_ 2152775680 CrgBdVwLtCustSetAvl "BLN";
BA_ "SignalLongName" SG_ 2152775680 CrgBdVwLtCustSetAvl "Cargo Bed View Auto Lighting Customization Setting Available";
BA_ "VNSigAllNodes" SG_ 2152775680 CrgBdVwLtCustSetAvl 1;
BA_ "GenSigSendType" SG_ 2152775680 TrlrMirVGlnCustSetVal 10;
BA_ "GenSigSendOnInit" SG_ 2152775680 TrlrMirVGlnCustSetVal 2;
BA_ "SignalType" SG_ 2152775680 TrlrMirVGlnCustSetVal "ENM";
BA_ "SignalLongName" SG_ 2152775680 TrlrMirVGlnCustSetVal "Trailering Mirror Video Guidelines Customization Current Setting Value";
BA_ "VNSigAllNodes" SG_ 2152775680 TrlrMirVGlnCustSetVal 1;
BA_ "GenSigSendType" SG_ 2152775680 TrlrMirVGlnCustSetAvl 10;
BA_ "GenSigSendOnInit" SG_ 2152775680 TrlrMirVGlnCustSetAvl 2;
BA_ "SignalType" SG_ 2152775680 TrlrMirVGlnCustSetAvl "BLN";
BA_ "SignalLongName" SG_ 2152775680 TrlrMirVGlnCustSetAvl "Trailering Mirror Video Guidelines Customization Setting Available";
BA_ "VNSigAllNodes" SG_ 2152775680 TrlrMirVGlnCustSetAvl 1;
BA_ "GenSigSendType" SG_ 2152775680 TrlrMirVEnCustSetVal 10;
BA_ "GenSigSendOnInit" SG_ 2152775680 TrlrMirVEnCustSetVal 2;
BA_ "SignalType" SG_ 2152775680 TrlrMirVEnCustSetVal "ENM";
BA_ "SignalLongName" SG_ 2152775680 TrlrMirVEnCustSetVal "Trailering Mirror Video Enable Customization Current Setting Value";
BA_ "VNSigAllNodes" SG_ 2152775680 TrlrMirVEnCustSetVal 1;
BA_ "GenSigSendType" SG_ 2152775680 TrlrMirVEnCustSetAvl 10;
BA_ "GenSigSendOnInit" SG_ 2152775680 TrlrMirVEnCustSetAvl 2;
BA_ "SignalType" SG_ 2152775680 TrlrMirVEnCustSetAvl "BLN";
BA_ "SignalLongName" SG_ 2152775680 TrlrMirVEnCustSetAvl "Trailering Mirror Video Enable Customization Setting Available";
BA_ "VNSigAllNodes" SG_ 2152775680 TrlrMirVEnCustSetAvl 1;
BA_ "GenSigSendType" SG_ 2152775680 TrlrArtcltnAnglCalStat 10;
BA_ "SignalType" SG_ 2152775680 TrlrArtcltnAnglCalStat "ENM";
BA_ "SignalLongName" SG_ 2152775680 TrlrArtcltnAnglCalStat "Trailer Articulation Angle Calibration Status";
BA_ "VNSigAllNodes" SG_ 2152775680 TrlrArtcltnAnglCalStat 1;
BA_ "GenSigSendType" SG_ 2152775680 InvTrlrAx1CamRollAlgnd 10;
BA_ "SignalType" SG_ 2152775680 InvTrlrAx1CamRollAlgnd "BLN";
BA_ "SignalLongName" SG_ 2152775680 InvTrlrAx1CamRollAlgnd "Invisible Trailer Aux1 Camera Roll Aligned";
BA_ "VNSigAllNodes" SG_ 2152775680 InvTrlrAx1CamRollAlgnd 1;
BA_ "GenSigSendType" SG_ 2152775680 InvTrlrAx1CamPtchAlgnd 10;
BA_ "SignalType" SG_ 2152775680 InvTrlrAx1CamPtchAlgnd "BLN";
BA_ "SignalLongName" SG_ 2152775680 InvTrlrAx1CamPtchAlgnd "Invisible Trailer Aux1 Camera Pitch Aligned";
BA_ "VNSigAllNodes" SG_ 2152775680 InvTrlrAx1CamPtchAlgnd 1;
BA_ "GenSigSendType" SG_ 2152775680 InvTrlrAx1CamYAlgnd 10;
BA_ "SignalType" SG_ 2152775680 InvTrlrAx1CamYAlgnd "BLN";
BA_ "SignalLongName" SG_ 2152775680 InvTrlrAx1CamYAlgnd "Invisible Trailer Aux1 Camera Y Aligned";
BA_ "VNSigAllNodes" SG_ 2152775680 InvTrlrAx1CamYAlgnd 1;
BA_ "GenSigSendType" SG_ 2152775680 InvTrlrAx1CamXAlgnd 10;
BA_ "SignalType" SG_ 2152775680 InvTrlrAx1CamXAlgnd "BLN";
BA_ "SignalLongName" SG_ 2152775680 InvTrlrAx1CamXAlgnd "Invisible Trailer Aux1 Camera X Aligned";
BA_ "VNSigAllNodes" SG_ 2152775680 InvTrlrAx1CamXAlgnd 1;
BA_ "GenSigSendType" SG_ 2152775680 RPDCA_Resrv3Avail 10;
BA_ "GenSigSendOnInit" SG_ 2152775680 RPDCA_Resrv3Avail 2;
BA_ "SignalType" SG_ 2152775680 RPDCA_Resrv3Avail "BLN";
BA_ "PacketOrder" SG_ 2152775680 RPDCA_Resrv3Avail 7;
BA_ "SignalLongName" SG_ 2152775680 RPDCA_Resrv3Avail "Rear Pedestrian Detection Customization Available : Reserved3 Available";
BA_ "VNSigAllNodes" SG_ 2152775680 RPDCA_Resrv3Avail 1;
BA_ "GenSigSendType" SG_ 2152775680 RPDCA_Resrv2Avail 10;
BA_ "GenSigSendOnInit" SG_ 2152775680 RPDCA_Resrv2Avail 2;
BA_ "SignalType" SG_ 2152775680 RPDCA_Resrv2Avail "BLN";
BA_ "PacketOrder" SG_ 2152775680 RPDCA_Resrv2Avail 6;
BA_ "SignalLongName" SG_ 2152775680 RPDCA_Resrv2Avail "Rear Pedestrian Detection Customization Available : Reserved2 Available";
BA_ "VNSigAllNodes" SG_ 2152775680 RPDCA_Resrv2Avail 1;
BA_ "GenSigSendType" SG_ 2152775680 RPDCA_Resrv1Avail 10;
BA_ "GenSigSendOnInit" SG_ 2152775680 RPDCA_Resrv1Avail 2;
BA_ "SignalType" SG_ 2152775680 RPDCA_Resrv1Avail "BLN";
BA_ "PacketOrder" SG_ 2152775680 RPDCA_Resrv1Avail 5;
BA_ "SignalLongName" SG_ 2152775680 RPDCA_Resrv1Avail "Rear Pedestrian Detection Customization Available : Reserved1 Available";
BA_ "VNSigAllNodes" SG_ 2152775680 RPDCA_Resrv1Avail 1;
BA_ "GenSigSendType" SG_ 2152775680 RPDCA_AlrtBrkAvail 10;
BA_ "GenSigSendOnInit" SG_ 2152775680 RPDCA_AlrtBrkAvail 2;
BA_ "PacketOrder" SG_ 2152775680 RPDCA_AlrtBrkAvail 4;
BA_ "SignalType" SG_ 2152775680 RPDCA_AlrtBrkAvail "BLN";
BA_ "SignalLongName" SG_ 2152775680 RPDCA_AlrtBrkAvail "Rear Pedestrian Detection Customization Available : Alert and Brake Available";
BA_ "VNSigAllNodes" SG_ 2152775680 RPDCA_AlrtBrkAvail 1;
BA_ "GenSigSendType" SG_ 2152775680 RPDCA_AlrtAvail 10;
BA_ "GenSigSendOnInit" SG_ 2152775680 RPDCA_AlrtAvail 2;
BA_ "PacketOrder" SG_ 2152775680 RPDCA_AlrtAvail 3;
BA_ "SignalType" SG_ 2152775680 RPDCA_AlrtAvail "BLN";
BA_ "SignalLongName" SG_ 2152775680 RPDCA_AlrtAvail "Rear Pedestrian Detection Customization Available : Alert Available";
BA_ "VNSigAllNodes" SG_ 2152775680 RPDCA_AlrtAvail 1;
BA_ "GenSigSendType" SG_ 2152775680 RPDCA_OnAvail 10;
BA_ "GenSigSendOnInit" SG_ 2152775680 RPDCA_OnAvail 2;
BA_ "SignalType" SG_ 2152775680 RPDCA_OnAvail "BLN";
BA_ "PacketOrder" SG_ 2152775680 RPDCA_OnAvail 2;
BA_ "SignalLongName" SG_ 2152775680 RPDCA_OnAvail "Rear Pedestrian Detection Customization Available : On Available";
BA_ "GenSigStartValue" SG_ 2152775680 RPDCA_OnAvail 1;
BA_ "VNSigAllNodes" SG_ 2152775680 RPDCA_OnAvail 1;
BA_ "GenSigSendType" SG_ 2152775680 RPDCA_OfAvail 10;
BA_ "GenSigSendOnInit" SG_ 2152775680 RPDCA_OfAvail 2;
BA_ "SignalType" SG_ 2152775680 RPDCA_OfAvail "BLN";
BA_ "PacketOrder" SG_ 2152775680 RPDCA_OfAvail 1;
BA_ "SignalLongName" SG_ 2152775680 RPDCA_OfAvail "Rear Pedestrian Detection Customization Available : Off Available";
BA_ "GenSigStartValue" SG_ 2152775680 RPDCA_OfAvail 1;
BA_ "VNSigAllNodes" SG_ 2152775680 RPDCA_OfAvail 1;
BA_ "GenSigDeltaValue" SG_ 2152775680 JacknfDetRHapSReqSN 1;
BA_ "GenSigSendType" SG_ 2152775680 JacknfDetRHapSReqSN 12;
BA_ "GenSigSendOnInit" SG_ 2152775680 JacknfDetRHapSReqSN 2;
BA_ "SignalType" SG_ 2152775680 JacknfDetRHapSReqSN "UNM";
BA_ "SignalLongName" SG_ 2152775680 JacknfDetRHapSReqSN "Jack Knife Detection Right Haptic Seat Request Sequence Number";
BA_ "VNSigAllNodes" SG_ 2152775680 JacknfDetRHapSReqSN 1;
BA_ "GenSigDeltaValue" SG_ 2152775680 JacknfDetRHapSReq 1;
BA_ "GenSigSendType" SG_ 2152775680 JacknfDetRHapSReq 12;
BA_ "GenSigSendOnInit" SG_ 2152775680 JacknfDetRHapSReq 2;
BA_ "SignalType" SG_ 2152775680 JacknfDetRHapSReq "UNM";
BA_ "SignalLongName" SG_ 2152775680 JacknfDetRHapSReq "Jack Knife Detection Right Haptic Seat Request";
BA_ "VNSigAllNodes" SG_ 2152775680 JacknfDetRHapSReq 1;
BA_ "GenSigDeltaValue" SG_ 2152775680 JacknfDetLHapSReqSN 1;
BA_ "GenSigSendType" SG_ 2152775680 JacknfDetLHapSReqSN 12;
BA_ "GenSigSendOnInit" SG_ 2152775680 JacknfDetLHapSReqSN 2;
BA_ "SignalType" SG_ 2152775680 JacknfDetLHapSReqSN "UNM";
BA_ "SignalLongName" SG_ 2152775680 JacknfDetLHapSReqSN "Jack Knife Detection Left Haptic Seat Request Sequence Number";
BA_ "VNSigAllNodes" SG_ 2152775680 JacknfDetLHapSReqSN 1;
BA_ "GenSigDeltaValue" SG_ 2152775680 JacknfDetLHapSReq 1;
BA_ "GenSigSendType" SG_ 2152775680 JacknfDetLHapSReq 12;
BA_ "GenSigSendOnInit" SG_ 2152775680 JacknfDetLHapSReq 2;
BA_ "SignalType" SG_ 2152775680 JacknfDetLHapSReq "UNM";
BA_ "SignalLongName" SG_ 2152775680 JacknfDetLHapSReq "Jack Knife Detection Left Haptic Seat Request";
BA_ "VNSigAllNodes" SG_ 2152775680 JacknfDetLHapSReq 1;
BA_ "GenSigSendType" SG_ 2152775680 JacknfDetCustSetVal 10;
BA_ "GenSigSendOnInit" SG_ 2152775680 JacknfDetCustSetVal 2;
BA_ "SignalType" SG_ 2152775680 JacknfDetCustSetVal "ENM";
BA_ "SignalLongName" SG_ 2152775680 JacknfDetCustSetVal "Jack Knife Detection Customization Current Setting Value";
BA_ "VNSigAllNodes" SG_ 2152775680 JacknfDetCustSetVal 1;
BA_ "GenSigSendType" SG_ 2152775680 JacknfDetCustSetAvl 10;
BA_ "GenSigSendOnInit" SG_ 2152775680 JacknfDetCustSetAvl 2;
BA_ "SignalType" SG_ 2152775680 JacknfDetCustSetAvl "BLN";
BA_ "SignalLongName" SG_ 2152775680 JacknfDetCustSetAvl "Jack Knife Detection Customization Setting Available";
BA_ "VNSigAllNodes" SG_ 2152775680 JacknfDetCustSetAvl 1;
BA_ "GenSigSendType" SG_ 2152775680 CrgBdVwLtCustSetVal 10;
BA_ "GenSigSendOnInit" SG_ 2152775680 CrgBdVwLtCustSetVal 2;
BA_ "SignalType" SG_ 2152775680 CrgBdVwLtCustSetVal "ENM";
BA_ "SignalLongName" SG_ 2152775680 CrgBdVwLtCustSetVal "Cargo Bed View Auto Lighting Customization Current Setting Value";
BA_ "VNSigAllNodes" SG_ 2152775680 CrgBdVwLtCustSetVal 1;
BA_ "GenSigSendType" SG_ 2152775680 DispTrgdVidOn 10;
BA_ "GenSigSendOnInit" SG_ 2152775680 DispTrgdVidOn 2;
BA_ "SignalType" SG_ 2152775680 DispTrgdVidOn "BLN";
BA_ "SignalLongName" SG_ 2152775680 DispTrgdVidOn "Display Triggered Video On";
BA_ "VNSigAllNodes" SG_ 2152775680 DispTrgdVidOn 1;
BA_ "GenSigSendType" SG_ 2152775680 a_360DegVidFetrPrsnt 10;
BA_ "GenSigSendOnInit" SG_ 2152775680 a_360DegVidFetrPrsnt 2;
BA_ "SignalType" SG_ 2152775680 a_360DegVidFetrPrsnt "BLN";
BA_ "SignalLongName" SG_ 2152775680 a_360DegVidFetrPrsnt "360 Degree Video Feature Present";
BA_ "VNSigAllNodes" SG_ 2152775680 a_360DegVidFetrPrsnt 1;
BA_ "GenSigSendType" SG_ 2152775680 TrgdVidRecFetrPrsnt 10;
BA_ "GenSigSendOnInit" SG_ 2152775680 TrgdVidRecFetrPrsnt 2;
BA_ "SignalType" SG_ 2152775680 TrgdVidRecFetrPrsnt "BLN";
BA_ "SignalLongName" SG_ 2152775680 TrgdVidRecFetrPrsnt "Triggered Video Recorder Feature Present";
BA_ "VNSigAllNodes" SG_ 2152775680 TrgdVidRecFetrPrsnt 1;
BA_ "GenSigDeltaValue" SG_ 2152775680 RrPdDetHptcStVbRq 1;
BA_ "GenSigSendType" SG_ 2152775680 RrPdDetHptcStVbRq 12;
BA_ "SignalType" SG_ 2152775680 RrPdDetHptcStVbRq "UNM";
BA_ "SignalLongName" SG_ 2152775680 RrPdDetHptcStVbRq "Rear Pedestrian Detection Haptic Seat Vibration Request";
BA_ "VNSigAllNodes" SG_ 2152775680 RrPdDetHptcStVbRq 1;
BA_ "GenSigDeltaValue" SG_ 2152775680 RrPdDetHptcStVbRqSeqN 1;
BA_ "GenSigSendType" SG_ 2152775680 RrPdDetHptcStVbRqSeqN 12;
BA_ "SignalType" SG_ 2152775680 RrPdDetHptcStVbRqSeqN "UNM";
BA_ "SignalLongName" SG_ 2152775680 RrPdDetHptcStVbRqSeqN "Rear Pedestrian Detection Haptic Seat Vibration Request Sequence Number";
BA_ "VNSigAllNodes" SG_ 2152775680 RrPdDetHptcStVbRqSeqN 1;
BA_ "GenSigSendType" SG_ 2152775680 RrPedDetCstStAvl 10;
BA_ "SignalType" SG_ 2152775680 RrPedDetCstStAvl "BLN";
BA_ "SignalLongName" SG_ 2152775680 RrPedDetCstStAvl "Rear Pedestrian Detection Customization Setting Available";
BA_ "VNSigAllNodes" SG_ 2152775680 RrPedDetCstStAvl 1;
BA_ "GenSigSendType" SG_ 2152775680 RrPedDetCstStVal 10;
BA_ "SignalType" SG_ 2152775680 RrPedDetCstStVal "ENM";
BA_ "SignalLongName" SG_ 2152775680 RrPedDetCstStVal "Rear Pedestrian Detection Customization Current Setting Value";
BA_ "VNSigAllNodes" SG_ 2152775680 RrPedDetCstStVal 1;
BA_ "GenSigSendType" SG_ 2152775680 DispFrt360CamOn 10;
BA_ "GenSigSendOnInit" SG_ 2152775680 DispFrt360CamOn 2;
BA_ "SignalType" SG_ 2152775680 DispFrt360CamOn "BLN";
BA_ "SignalLongName" SG_ 2152775680 DispFrt360CamOn "Display Front 360 Camera On";
BA_ "VNSigAllNodes" SG_ 2152775680 DispFrt360CamOn 1;
BA_ "GenSigSendType" SG_ 2152775680 SurdVwLightgCsSetAvail 10;
BA_ "GenSigSendOnInit" SG_ 2152775680 SurdVwLightgCsSetAvail 2;
BA_ "SignalType" SG_ 2152775680 SurdVwLightgCsSetAvail "BLN";
BA_ "SignalLongName" SG_ 2152775680 SurdVwLightgCsSetAvail "Surround View Lighting Customization Setting Available";
BA_ "VNSigAllNodes" SG_ 2152775680 SurdVwLightgCsSetAvail 1;
BA_ "GenSigSendType" SG_ 2152775680 SurdVwLightgCsCurrSetVal 10;
BA_ "GenSigSendOnInit" SG_ 2152775680 SurdVwLightgCsCurrSetVal 2;
BA_ "SignalType" SG_ 2152775680 SurdVwLightgCsCurrSetVal "ENM";
BA_ "SignalLongName" SG_ 2152775680 SurdVwLightgCsCurrSetVal "Surround View Lighting Customization Current Setting Value";
BA_ "VNSigAllNodes" SG_ 2152775680 SurdVwLightgCsCurrSetVal 1;
BA_ "GenSigSendType" SG_ 2152775680 PudlLmpReqstd 10;
BA_ "SignalType" SG_ 2152775680 PudlLmpReqstd "BLN";
BA_ "SignalLongName" SG_ 2152775680 PudlLmpReqstd "Puddle Lamp Requested";
BA_ "VNSigAllNodes" SG_ 2152775680 PudlLmpReqstd 1;
BA_ "GenSigSendType" SG_ 2152775680 DispSmrtTwVidOn 10;
BA_ "SignalType" SG_ 2152775680 DispSmrtTwVidOn "BLN";
BA_ "SignalLongName" SG_ 2152775680 DispSmrtTwVidOn "Display Smart Tow Video On";
BA_ "VNSigAllNodes" SG_ 2152775680 DispSmrtTwVidOn 1;
BA_ "SignalType" SG_ 2149777408 WRSLNDWhlDisTpRC "UNM";
BA_ "PacketOrder" SG_ 2149777408 WRSLNDWhlDisTpRC 1;
BA_ "SignalLongName" SG_ 2149777408 WRSLNDWhlDisTpRC "Wheel Rotational Status Left Non Driven : Wheel Distance Timestamp Rollover Counter";
BA_ "VNSigAllNodes" SG_ 2149777408 WRSLNDWhlDisTpRC 1;
BA_ "SignalType" SG_ 2149777408 WRSLNDWhlRotStRst "BLN";
BA_ "PacketOrder" SG_ 2149777408 WRSLNDWhlRotStRst 3;
BA_ "SignalLongName" SG_ 2149777408 WRSLNDWhlRotStRst "Wheel Rotational Status Left Non Driven : Wheel Rotational Status Reset Occurred";
BA_ "VNSigAllNodes" SG_ 2149777408 WRSLNDWhlRotStRst 1;
BA_ "SignalType" SG_ 2149777408 WRSLNDWhlDistVal "ENM";
BA_ "PacketOrder" SG_ 2149777408 WRSLNDWhlDistVal 4;
BA_ "SignalLongName" SG_ 2149777408 WRSLNDWhlDistVal "Wheel Rotational Status Left Non Driven : Wheel Distance Validity";
BA_ "VNSigAllNodes" SG_ 2149777408 WRSLNDWhlDistVal 1;
BA_ "SignalType" SG_ 2149777408 WRSLNDWhlDistTstm "UNM";
BA_ "PacketOrder" SG_ 2149777408 WRSLNDWhlDistTstm 6;
BA_ "SignalLongName" SG_ 2149777408 WRSLNDWhlDistTstm "Wheel Rotational Status Left Non Driven : Wheel Distance Timestamp";
BA_ "VNSigAllNodes" SG_ 2149777408 WRSLNDWhlDistTstm 1;
BA_ "SignalType" SG_ 2149777408 WRSLNDWhlDistPCntr "UNM";
BA_ "PacketOrder" SG_ 2149777408 WRSLNDWhlDistPCntr 5;
BA_ "SignalLongName" SG_ 2149777408 WRSLNDWhlDistPCntr "Wheel Rotational Status Left Non Driven : Wheel Distance Pulse Counter";
BA_ "VNSigAllNodes" SG_ 2149777408 WRSLNDWhlDistPCntr 1;
BA_ "SignalType" SG_ 2149777408 WRSLNDSeqNum "UNM";
BA_ "PacketOrder" SG_ 2149777408 WRSLNDSeqNum 2;
BA_ "SignalLongName" SG_ 2149777408 WRSLNDSeqNum "Wheel Rotational Status Left Non Driven : Sequence Number";
BA_ "VNSigAllNodes" SG_ 2149777408 WRSLNDSeqNum 1;
BA_ "SignalType" SG_ 2149777408 WRSRNDWhlDisTpRC "UNM";
BA_ "PacketOrder" SG_ 2149777408 WRSRNDWhlDisTpRC 1;
BA_ "SignalLongName" SG_ 2149777408 WRSRNDWhlDisTpRC "Wheel Rotational Status Right Non Driven : Wheel Distance Timestamp Rollover Counter";
BA_ "VNSigAllNodes" SG_ 2149777408 WRSRNDWhlDisTpRC 1;
BA_ "SignalType" SG_ 2149777408 WRSRNDWhlRotStRst "BLN";
BA_ "PacketOrder" SG_ 2149777408 WRSRNDWhlRotStRst 3;
BA_ "SignalLongName" SG_ 2149777408 WRSRNDWhlRotStRst "Wheel Rotational Status Right Non Driven : Wheel Rotational Status Reset Occurred";
BA_ "VNSigAllNodes" SG_ 2149777408 WRSRNDWhlRotStRst 1;
BA_ "SignalType" SG_ 2149777408 WRSRNDWhlDistVal "ENM";
BA_ "PacketOrder" SG_ 2149777408 WRSRNDWhlDistVal 4;
BA_ "SignalLongName" SG_ 2149777408 WRSRNDWhlDistVal "Wheel Rotational Status Right Non Driven : Wheel Distance Validity";
BA_ "VNSigAllNodes" SG_ 2149777408 WRSRNDWhlDistVal 1;
BA_ "SignalType" SG_ 2149777408 WRSRNDWhlDistTstm "UNM";
BA_ "PacketOrder" SG_ 2149777408 WRSRNDWhlDistTstm 6;
BA_ "SignalLongName" SG_ 2149777408 WRSRNDWhlDistTstm "Wheel Rotational Status Right Non Driven : Wheel Distance Timestamp";
BA_ "VNSigAllNodes" SG_ 2149777408 WRSRNDWhlDistTstm 1;
BA_ "SignalType" SG_ 2149777408 WRSRNDWhlDistPCntr "UNM";
BA_ "PacketOrder" SG_ 2149777408 WRSRNDWhlDistPCntr 5;
BA_ "SignalLongName" SG_ 2149777408 WRSRNDWhlDistPCntr "Wheel Rotational Status Right Non Driven : Wheel Distance Pulse Counter";
BA_ "VNSigAllNodes" SG_ 2149777408 WRSRNDWhlDistPCntr 1;
BA_ "SignalType" SG_ 2149777408 WRSRNDSeqNum "UNM";
BA_ "PacketOrder" SG_ 2149777408 WRSRNDSeqNum 2;
BA_ "SignalLongName" SG_ 2149777408 WRSRNDSeqNum "Wheel Rotational Status Right Non Driven : Sequence Number";
BA_ "VNSigAllNodes" SG_ 2149777408 WRSRNDSeqNum 1;
BA_ "GenSigDeltaValue" SG_ 2155069440 DSAP_UnsdRsrvd 1;
BA_ "GenSigSendType" SG_ 2155069440 DSAP_UnsdRsrvd 12;
BA_ "GenSigSendOnInit" SG_ 2155069440 DSAP_UnsdRsrvd 2;
BA_ "SignalType" SG_ 2155069440 DSAP_UnsdRsrvd "UNM";
BA_ "PacketOrder" SG_ 2155069440 DSAP_UnsdRsrvd 16;
BA_ "SignalLongName" SG_ 2155069440 DSAP_UnsdRsrvd "Driver Seat Actuator Priority : Unused and Reserved";
BA_ "VNSigAllNodes" SG_ 2155069440 DSAP_UnsdRsrvd 1;
BA_ "GenSigDeltaValue" SG_ 2155069440 DSAP_DispSz 1;
BA_ "GenSigSendType" SG_ 2155069440 DSAP_DispSz 12;
BA_ "GenSigSendOnInit" SG_ 2155069440 DSAP_DispSz 2;
BA_ "SignalType" SG_ 2155069440 DSAP_DispSz "UNM";
BA_ "PacketOrder" SG_ 2155069440 DSAP_DispSz 15;
BA_ "SignalLongName" SG_ 2155069440 DSAP_DispSz "Driver Seat Actuator Priority : Display Size";
BA_ "VNSigAllNodes" SG_ 2155069440 DSAP_DispSz 1;
BA_ "GenSigDeltaValue" SG_ 2155069440 DSAP_CshLgthAdjFdRr 1;
BA_ "GenSigSendType" SG_ 2155069440 DSAP_CshLgthAdjFdRr 12;
BA_ "GenSigSendOnInit" SG_ 2155069440 DSAP_CshLgthAdjFdRr 2;
BA_ "SignalType" SG_ 2155069440 DSAP_CshLgthAdjFdRr "UNM";
BA_ "PacketOrder" SG_ 2155069440 DSAP_CshLgthAdjFdRr 14;
BA_ "SignalLongName" SG_ 2155069440 DSAP_CshLgthAdjFdRr "Driver Seat Actuator Priority : Cushion Length Adjustment Forward/Rearward";
BA_ "VNSigAllNodes" SG_ 2155069440 DSAP_CshLgthAdjFdRr 1;
BA_ "GenSigDeltaValue" SG_ 2155069440 DSAP_BkCshBlstrInOut 1;
BA_ "GenSigSendType" SG_ 2155069440 DSAP_BkCshBlstrInOut 12;
BA_ "GenSigSendOnInit" SG_ 2155069440 DSAP_BkCshBlstrInOut 2;
BA_ "SignalType" SG_ 2155069440 DSAP_BkCshBlstrInOut "UNM";
BA_ "PacketOrder" SG_ 2155069440 DSAP_BkCshBlstrInOut 13;
BA_ "SignalLongName" SG_ 2155069440 DSAP_BkCshBlstrInOut "Driver Seat Actuator Priority : Back and Cushion Bolster In/Out";
BA_ "VNSigAllNodes" SG_ 2155069440 DSAP_BkCshBlstrInOut 1;
BA_ "GenSigDeltaValue" SG_ 2155069440 DSAP_CshBlstrInOut 1;
BA_ "GenSigSendType" SG_ 2155069440 DSAP_CshBlstrInOut 12;
BA_ "GenSigSendOnInit" SG_ 2155069440 DSAP_CshBlstrInOut 2;
BA_ "SignalType" SG_ 2155069440 DSAP_CshBlstrInOut "UNM";
BA_ "PacketOrder" SG_ 2155069440 DSAP_CshBlstrInOut 12;
BA_ "SignalLongName" SG_ 2155069440 DSAP_CshBlstrInOut "Driver Seat Actuator Priority : Cushion Bolster In/Out";
BA_ "VNSigAllNodes" SG_ 2155069440 DSAP_CshBlstrInOut 1;
BA_ "GenSigDeltaValue" SG_ 2155069440 DSAP_BkBlstrInOut 1;
BA_ "GenSigSendType" SG_ 2155069440 DSAP_BkBlstrInOut 12;
BA_ "GenSigSendOnInit" SG_ 2155069440 DSAP_BkBlstrInOut 2;
BA_ "SignalType" SG_ 2155069440 DSAP_BkBlstrInOut "UNM";
BA_ "PacketOrder" SG_ 2155069440 DSAP_BkBlstrInOut 11;
BA_ "SignalLongName" SG_ 2155069440 DSAP_BkBlstrInOut "Driver Seat Actuator Priority : Back Bolster In/Out";
BA_ "VNSigAllNodes" SG_ 2155069440 DSAP_BkBlstrInOut 1;
BA_ "GenSigDeltaValue" SG_ 2155069440 DSAP_LmbrUpDnFdRr 1;
BA_ "GenSigSendType" SG_ 2155069440 DSAP_LmbrUpDnFdRr 12;
BA_ "GenSigSendOnInit" SG_ 2155069440 DSAP_LmbrUpDnFdRr 2;
BA_ "SignalType" SG_ 2155069440 DSAP_LmbrUpDnFdRr "UNM";
BA_ "PacketOrder" SG_ 2155069440 DSAP_LmbrUpDnFdRr 10;
BA_ "SignalLongName" SG_ 2155069440 DSAP_LmbrUpDnFdRr "Driver Seat Actuator Priority : Lumbar Up/Down and Forward/Rearward";
BA_ "VNSigAllNodes" SG_ 2155069440 DSAP_LmbrUpDnFdRr 1;
BA_ "GenSigDeltaValue" SG_ 2155069440 DSAP_LmbrFwdRr 1;
BA_ "GenSigSendType" SG_ 2155069440 DSAP_LmbrFwdRr 12;
BA_ "GenSigSendOnInit" SG_ 2155069440 DSAP_LmbrFwdRr 2;
BA_ "SignalType" SG_ 2155069440 DSAP_LmbrFwdRr "UNM";
BA_ "PacketOrder" SG_ 2155069440 DSAP_LmbrFwdRr 9;
BA_ "SignalLongName" SG_ 2155069440 DSAP_LmbrFwdRr "Driver Seat Actuator Priority : Lumbar Forward/Rearward";
BA_ "VNSigAllNodes" SG_ 2155069440 DSAP_LmbrFwdRr 1;
BA_ "GenSigDeltaValue" SG_ 2155069440 DSAP_LmbrUpDwn 1;
BA_ "GenSigSendType" SG_ 2155069440 DSAP_LmbrUpDwn 12;
BA_ "GenSigSendOnInit" SG_ 2155069440 DSAP_LmbrUpDwn 2;
BA_ "SignalType" SG_ 2155069440 DSAP_LmbrUpDwn "UNM";
BA_ "PacketOrder" SG_ 2155069440 DSAP_LmbrUpDwn 8;
BA_ "SignalLongName" SG_ 2155069440 DSAP_LmbrUpDwn "Driver Seat Actuator Priority : Lumbar Up/Down";
BA_ "VNSigAllNodes" SG_ 2155069440 DSAP_LmbrUpDwn 1;
BA_ "GenSigDeltaValue" SG_ 2155069440 DSAP_UprShldrFwdRr 1;
BA_ "GenSigSendType" SG_ 2155069440 DSAP_UprShldrFwdRr 12;
BA_ "GenSigSendOnInit" SG_ 2155069440 DSAP_UprShldrFwdRr 2;
BA_ "SignalType" SG_ 2155069440 DSAP_UprShldrFwdRr "UNM";
BA_ "PacketOrder" SG_ 2155069440 DSAP_UprShldrFwdRr 7;
BA_ "SignalLongName" SG_ 2155069440 DSAP_UprShldrFwdRr "Driver Seat Actuator Priority : Upper Shoulder Forward/Rearward";
BA_ "VNSigAllNodes" SG_ 2155069440 DSAP_UprShldrFwdRr 1;
BA_ "GenSigDeltaValue" SG_ 2155069440 DSAP_HdrstTltFwdRr 1;
BA_ "GenSigSendType" SG_ 2155069440 DSAP_HdrstTltFwdRr 12;
BA_ "GenSigSendOnInit" SG_ 2155069440 DSAP_HdrstTltFwdRr 2;
BA_ "SignalType" SG_ 2155069440 DSAP_HdrstTltFwdRr "UNM";
BA_ "PacketOrder" SG_ 2155069440 DSAP_HdrstTltFwdRr 6;
BA_ "SignalLongName" SG_ 2155069440 DSAP_HdrstTltFwdRr "Driver Seat Actuator Priority : Headrest Tilt Forward/Rearward";
BA_ "VNSigAllNodes" SG_ 2155069440 DSAP_HdrstTltFwdRr 1;
BA_ "GenSigDeltaValue" SG_ 2155069440 DSAP_HdrstWngsInOut 1;
BA_ "GenSigSendType" SG_ 2155069440 DSAP_HdrstWngsInOut 12;
BA_ "GenSigSendOnInit" SG_ 2155069440 DSAP_HdrstWngsInOut 2;
BA_ "SignalType" SG_ 2155069440 DSAP_HdrstWngsInOut "UNM";
BA_ "PacketOrder" SG_ 2155069440 DSAP_HdrstWngsInOut 5;
BA_ "SignalLongName" SG_ 2155069440 DSAP_HdrstWngsInOut "Driver Seat Actuator Priority : Headrest Wings Inward/Outward";
BA_ "VNSigAllNodes" SG_ 2155069440 DSAP_HdrstWngsInOut 1;
BA_ "GenSigDeltaValue" SG_ 2155069440 DSAP_HdrstUpDnFdRr 1;
BA_ "GenSigSendType" SG_ 2155069440 DSAP_HdrstUpDnFdRr 12;
BA_ "GenSigSendOnInit" SG_ 2155069440 DSAP_HdrstUpDnFdRr 2;
BA_ "SignalType" SG_ 2155069440 DSAP_HdrstUpDnFdRr "UNM";
BA_ "PacketOrder" SG_ 2155069440 DSAP_HdrstUpDnFdRr 4;
BA_ "SignalLongName" SG_ 2155069440 DSAP_HdrstUpDnFdRr "Driver Seat Actuator Priority : Headrest Up/Down and Forward/Rearward";
BA_ "VNSigAllNodes" SG_ 2155069440 DSAP_HdrstUpDnFdRr 1;
BA_ "GenSigDeltaValue" SG_ 2155069440 DSAP_HdrstFwdRrwd 1;
BA_ "GenSigSendType" SG_ 2155069440 DSAP_HdrstFwdRrwd 12;
BA_ "GenSigSendOnInit" SG_ 2155069440 DSAP_HdrstFwdRrwd 2;
BA_ "SignalType" SG_ 2155069440 DSAP_HdrstFwdRrwd "UNM";
BA_ "PacketOrder" SG_ 2155069440 DSAP_HdrstFwdRrwd 3;
BA_ "SignalLongName" SG_ 2155069440 DSAP_HdrstFwdRrwd "Driver Seat Actuator Priority : Headrest Forward/Rearward";
BA_ "VNSigAllNodes" SG_ 2155069440 DSAP_HdrstFwdRrwd 1;
BA_ "GenSigDeltaValue" SG_ 2155069440 DSAP_HdrstUpDn 1;
BA_ "GenSigSendType" SG_ 2155069440 DSAP_HdrstUpDn 12;
BA_ "GenSigSendOnInit" SG_ 2155069440 DSAP_HdrstUpDn 2;
BA_ "SignalType" SG_ 2155069440 DSAP_HdrstUpDn "UNM";
BA_ "PacketOrder" SG_ 2155069440 DSAP_HdrstUpDn 2;
BA_ "SignalLongName" SG_ 2155069440 DSAP_HdrstUpDn "Driver Seat Actuator Priority : Headrest Up/Down";
BA_ "VNSigAllNodes" SG_ 2155069440 DSAP_HdrstUpDn 1;
BA_ "GenSigDeltaValue" SG_ 2155069440 DSAP_Massg 1;
BA_ "GenSigSendType" SG_ 2155069440 DSAP_Massg 12;
BA_ "GenSigSendOnInit" SG_ 2155069440 DSAP_Massg 2;
BA_ "SignalType" SG_ 2155069440 DSAP_Massg "UNM";
BA_ "PacketOrder" SG_ 2155069440 DSAP_Massg 1;
BA_ "SignalLongName" SG_ 2155069440 DSAP_Massg "Driver Seat Actuator Priority : Massage";
BA_ "VNSigAllNodes" SG_ 2155069440 DSAP_Massg 1;
BA_ "GenSigDeltaValue" SG_ 2152153088 RRSCDS_UnsdRsrvd 1;
BA_ "GenSigSendType" SG_ 2152153088 RRSCDS_UnsdRsrvd 12;
BA_ "SignalType" SG_ 2152153088 RRSCDS_UnsdRsrvd "UNM";
BA_ "PacketOrder" SG_ 2152153088 RRSCDS_UnsdRsrvd 19;
BA_ "SignalLongName" SG_ 2152153088 RRSCDS_UnsdRsrvd "Right Rear Seat Control Display Status : Unused and Reserved";
BA_ "VNSigAllNodes" SG_ 2152153088 RRSCDS_UnsdRsrvd 1;
BA_ "GenSigSendType" SG_ 2152153088 RRSCDS_DispReq 10;
BA_ "SignalType" SG_ 2152153088 RRSCDS_DispReq "BLN";
BA_ "PacketOrder" SG_ 2152153088 RRSCDS_DispReq 18;
BA_ "SignalLongName" SG_ 2152153088 RRSCDS_DispReq "Right Rear Seat Control Display Status : Display Request";
BA_ "VNSigAllNodes" SG_ 2152153088 RRSCDS_DispReq 1;
BA_ "GenSigSendType" SG_ 2152153088 RRSCDS_DispSz 10;
BA_ "SignalType" SG_ 2152153088 RRSCDS_DispSz "ENM";
BA_ "PacketOrder" SG_ 2152153088 RRSCDS_DispSz 17;
BA_ "SignalLongName" SG_ 2152153088 RRSCDS_DispSz "Right Rear Seat Control Display Status : Display Size";
BA_ "VNSigAllNodes" SG_ 2152153088 RRSCDS_DispSz 1;
BA_ "GenSigSendType" SG_ 2152153088 RRSCDS_CshLgAdjFdRr 10;
BA_ "SignalType" SG_ 2152153088 RRSCDS_CshLgAdjFdRr "ENM";
BA_ "PacketOrder" SG_ 2152153088 RRSCDS_CshLgAdjFdRr 16;
BA_ "SignalLongName" SG_ 2152153088 RRSCDS_CshLgAdjFdRr "Right Rear Seat Control Display Status : Cushion Length Adjustment Forward/Rearward";
BA_ "VNSigAllNodes" SG_ 2152153088 RRSCDS_CshLgAdjFdRr 1;
BA_ "GenSigSendType" SG_ 2152153088 RRSCDS_BkCshBlstInOt 10;
BA_ "SignalType" SG_ 2152153088 RRSCDS_BkCshBlstInOt "ENM";
BA_ "PacketOrder" SG_ 2152153088 RRSCDS_BkCshBlstInOt 15;
BA_ "SignalLongName" SG_ 2152153088 RRSCDS_BkCshBlstInOt "Right Rear Seat Control Display Status : Back and Cushion Bolster In/Out";
BA_ "VNSigAllNodes" SG_ 2152153088 RRSCDS_BkCshBlstInOt 1;
BA_ "GenSigSendType" SG_ 2152153088 RRSCDS_CshBlstrInOut 10;
BA_ "SignalType" SG_ 2152153088 RRSCDS_CshBlstrInOut "ENM";
BA_ "PacketOrder" SG_ 2152153088 RRSCDS_CshBlstrInOut 14;
BA_ "SignalLongName" SG_ 2152153088 RRSCDS_CshBlstrInOut "Right Rear Seat Control Display Status : Cushion Bolster In/Out";
BA_ "VNSigAllNodes" SG_ 2152153088 RRSCDS_CshBlstrInOut 1;
BA_ "GenSigSendType" SG_ 2152153088 RRSCDS_BkBlstrInOut 10;
BA_ "SignalType" SG_ 2152153088 RRSCDS_BkBlstrInOut "ENM";
BA_ "PacketOrder" SG_ 2152153088 RRSCDS_BkBlstrInOut 13;
BA_ "SignalLongName" SG_ 2152153088 RRSCDS_BkBlstrInOut "Right Rear Seat Control Display Status : Back Bolster In/Out";
BA_ "VNSigAllNodes" SG_ 2152153088 RRSCDS_BkBlstrInOut 1;
BA_ "GenSigSendType" SG_ 2152153088 RRSCDS_LmbrUDnFdRr 10;
BA_ "SignalType" SG_ 2152153088 RRSCDS_LmbrUDnFdRr "ENM";
BA_ "PacketOrder" SG_ 2152153088 RRSCDS_LmbrUDnFdRr 12;
BA_ "SignalLongName" SG_ 2152153088 RRSCDS_LmbrUDnFdRr "Right Rear Seat Control Display Status : Lumbar Up/Down and Forward/Rearward";
BA_ "VNSigAllNodes" SG_ 2152153088 RRSCDS_LmbrUDnFdRr 1;
BA_ "GenSigSendType" SG_ 2152153088 RRSCDS_LmbrFwdRr 10;
BA_ "SignalType" SG_ 2152153088 RRSCDS_LmbrFwdRr "ENM";
BA_ "PacketOrder" SG_ 2152153088 RRSCDS_LmbrFwdRr 11;
BA_ "SignalLongName" SG_ 2152153088 RRSCDS_LmbrFwdRr "Right Rear Seat Control Display Status : Lumbar Forward/Rearward";
BA_ "VNSigAllNodes" SG_ 2152153088 RRSCDS_LmbrFwdRr 1;
BA_ "GenSigSendType" SG_ 2152153088 RRSCDS_LmbrUpDwn 10;
BA_ "SignalType" SG_ 2152153088 RRSCDS_LmbrUpDwn "ENM";
BA_ "PacketOrder" SG_ 2152153088 RRSCDS_LmbrUpDwn 10;
BA_ "SignalLongName" SG_ 2152153088 RRSCDS_LmbrUpDwn "Right Rear Seat Control Display Status : Lumbar Up/Down";
BA_ "VNSigAllNodes" SG_ 2152153088 RRSCDS_LmbrUpDwn 1;
BA_ "GenSigSendType" SG_ 2152153088 RRSCDS_UprShldrFdRr 10;
BA_ "SignalType" SG_ 2152153088 RRSCDS_UprShldrFdRr "ENM";
BA_ "PacketOrder" SG_ 2152153088 RRSCDS_UprShldrFdRr 9;
BA_ "SignalLongName" SG_ 2152153088 RRSCDS_UprShldrFdRr "Right Rear Seat Control Display Status : Upper Shoulder Forward/Rearward";
BA_ "VNSigAllNodes" SG_ 2152153088 RRSCDS_UprShldrFdRr 1;
BA_ "GenSigSendType" SG_ 2152153088 RRSCDS_HdrstTltFwdRr 10;
BA_ "SignalType" SG_ 2152153088 RRSCDS_HdrstTltFwdRr "ENM";
BA_ "PacketOrder" SG_ 2152153088 RRSCDS_HdrstTltFwdRr 8;
BA_ "SignalLongName" SG_ 2152153088 RRSCDS_HdrstTltFwdRr "Right Rear Seat Control Display Status : Headrest Tilt Forward/Rearward";
BA_ "VNSigAllNodes" SG_ 2152153088 RRSCDS_HdrstTltFwdRr 1;
BA_ "GenSigSendType" SG_ 2152153088 RRSCDS_HdrstWngInOt 10;
BA_ "SignalType" SG_ 2152153088 RRSCDS_HdrstWngInOt "ENM";
BA_ "PacketOrder" SG_ 2152153088 RRSCDS_HdrstWngInOt 7;
BA_ "SignalLongName" SG_ 2152153088 RRSCDS_HdrstWngInOt "Right Rear Seat Control Display Status : Headrest Wings In/Out";
BA_ "VNSigAllNodes" SG_ 2152153088 RRSCDS_HdrstWngInOt 1;
BA_ "GenSigSendType" SG_ 2152153088 RRSCDS_HdrstFdRrUDn 10;
BA_ "SignalType" SG_ 2152153088 RRSCDS_HdrstFdRrUDn "ENM";
BA_ "PacketOrder" SG_ 2152153088 RRSCDS_HdrstFdRrUDn 6;
BA_ "SignalLongName" SG_ 2152153088 RRSCDS_HdrstFdRrUDn "Right Rear Seat Control Display Status : Headrest Forward/Rearward
 and Up/Down";
BA_ "VNSigAllNodes" SG_ 2152153088 RRSCDS_HdrstFdRrUDn 1;
BA_ "GenSigSendType" SG_ 2152153088 RRSCDS_HdrstFwdRrwd 10;
BA_ "SignalType" SG_ 2152153088 RRSCDS_HdrstFwdRrwd "ENM";
BA_ "PacketOrder" SG_ 2152153088 RRSCDS_HdrstFwdRrwd 5;
BA_ "SignalLongName" SG_ 2152153088 RRSCDS_HdrstFwdRrwd "Right Rear Seat Control Display Status : Headrest Forward/Rearward";
BA_ "VNSigAllNodes" SG_ 2152153088 RRSCDS_HdrstFwdRrwd 1;
BA_ "GenSigSendType" SG_ 2152153088 RRSCDS_HdrstUpDn 10;
BA_ "SignalType" SG_ 2152153088 RRSCDS_HdrstUpDn "ENM";
BA_ "PacketOrder" SG_ 2152153088 RRSCDS_HdrstUpDn 4;
BA_ "SignalLongName" SG_ 2152153088 RRSCDS_HdrstUpDn "Right Rear Seat Control Display Status : Headrest Up/Down";
BA_ "VNSigAllNodes" SG_ 2152153088 RRSCDS_HdrstUpDn 1;
BA_ "GenSigSendType" SG_ 2152153088 RRSCDS_MassgIntsty 10;
BA_ "SignalType" SG_ 2152153088 RRSCDS_MassgIntsty "ENM";
BA_ "PacketOrder" SG_ 2152153088 RRSCDS_MassgIntsty 3;
BA_ "SignalLongName" SG_ 2152153088 RRSCDS_MassgIntsty "Right Rear Seat Control Display Status : Massage Intensity";
BA_ "VNSigAllNodes" SG_ 2152153088 RRSCDS_MassgIntsty 1;
BA_ "GenSigSendType" SG_ 2152153088 RRSCDS_MassgTyp 10;
BA_ "SignalType" SG_ 2152153088 RRSCDS_MassgTyp "ENM";
BA_ "PacketOrder" SG_ 2152153088 RRSCDS_MassgTyp 2;
BA_ "SignalLongName" SG_ 2152153088 RRSCDS_MassgTyp "Right Rear Seat Control Display Status : Massage Type";
BA_ "VNSigAllNodes" SG_ 2152153088 RRSCDS_MassgTyp 1;
BA_ "GenSigSendType" SG_ 2152153088 RRSCDS_Massg 10;
BA_ "SignalType" SG_ 2152153088 RRSCDS_Massg "ENM";
BA_ "PacketOrder" SG_ 2152153088 RRSCDS_Massg 1;
BA_ "SignalLongName" SG_ 2152153088 RRSCDS_Massg "Right Rear Seat Control Display Status : Massage";
BA_ "VNSigAllNodes" SG_ 2152153088 RRSCDS_Massg 1;
BA_ "GenSigSendType" SG_ 2152136704 RRSMP_UnsdRsrvd 10;
BA_ "GenSigSendOnInit" SG_ 2152136704 RRSMP_UnsdRsrvd 2;
BA_ "SignalType" SG_ 2152136704 RRSMP_UnsdRsrvd "BLN";
BA_ "PacketOrder" SG_ 2152136704 RRSMP_UnsdRsrvd 17;
BA_ "SignalLongName" SG_ 2152136704 RRSMP_UnsdRsrvd "Right Rear Seat Massage Priority : Unused and Reserved";
BA_ "VNSigAllNodes" SG_ 2152136704 RRSMP_UnsdRsrvd 1;
BA_ "GenSigDeltaValue" SG_ 2152136704 RRSMP_MaxDispVal 1;
BA_ "GenSigSendType" SG_ 2152136704 RRSMP_MaxDispVal 12;
BA_ "GenSigSendOnInit" SG_ 2152136704 RRSMP_MaxDispVal 2;
BA_ "SignalType" SG_ 2152136704 RRSMP_MaxDispVal "UNM";
BA_ "PacketOrder" SG_ 2152136704 RRSMP_MaxDispVal 16;
BA_ "SignalLongName" SG_ 2152136704 RRSMP_MaxDispVal "Right Rear Seat Massage Priority : Maximum Display Value";
BA_ "VNSigAllNodes" SG_ 2152136704 RRSMP_MaxDispVal 1;
BA_ "GenSigDeltaValue" SG_ 2152136704 RRSMP_Type15 1;
BA_ "GenSigSendType" SG_ 2152136704 RRSMP_Type15 12;
BA_ "GenSigSendOnInit" SG_ 2152136704 RRSMP_Type15 2;
BA_ "SignalType" SG_ 2152136704 RRSMP_Type15 "UNM";
BA_ "PacketOrder" SG_ 2152136704 RRSMP_Type15 15;
BA_ "SignalLongName" SG_ 2152136704 RRSMP_Type15 "Right Rear Seat Massage Priority : Type 15";
BA_ "VNSigAllNodes" SG_ 2152136704 RRSMP_Type15 1;
BA_ "GenSigDeltaValue" SG_ 2152136704 RRSMP_Type14 1;
BA_ "GenSigSendType" SG_ 2152136704 RRSMP_Type14 12;
BA_ "GenSigSendOnInit" SG_ 2152136704 RRSMP_Type14 2;
BA_ "SignalType" SG_ 2152136704 RRSMP_Type14 "UNM";
BA_ "PacketOrder" SG_ 2152136704 RRSMP_Type14 14;
BA_ "SignalLongName" SG_ 2152136704 RRSMP_Type14 "Right Rear Seat Massage Priority : Type 14";
BA_ "VNSigAllNodes" SG_ 2152136704 RRSMP_Type14 1;
BA_ "GenSigDeltaValue" SG_ 2152136704 RRSMP_Type13 1;
BA_ "GenSigSendType" SG_ 2152136704 RRSMP_Type13 12;
BA_ "GenSigSendOnInit" SG_ 2152136704 RRSMP_Type13 2;
BA_ "SignalType" SG_ 2152136704 RRSMP_Type13 "UNM";
BA_ "PacketOrder" SG_ 2152136704 RRSMP_Type13 13;
BA_ "SignalLongName" SG_ 2152136704 RRSMP_Type13 "Right Rear Seat Massage Priority : Type 13";
BA_ "VNSigAllNodes" SG_ 2152136704 RRSMP_Type13 1;
BA_ "GenSigDeltaValue" SG_ 2152136704 RRSMP_Type12 1;
BA_ "GenSigSendType" SG_ 2152136704 RRSMP_Type12 12;
BA_ "GenSigSendOnInit" SG_ 2152136704 RRSMP_Type12 2;
BA_ "SignalType" SG_ 2152136704 RRSMP_Type12 "UNM";
BA_ "PacketOrder" SG_ 2152136704 RRSMP_Type12 12;
BA_ "SignalLongName" SG_ 2152136704 RRSMP_Type12 "Right Rear Seat Massage Priority : Type 12";
BA_ "VNSigAllNodes" SG_ 2152136704 RRSMP_Type12 1;
BA_ "GenSigDeltaValue" SG_ 2152136704 RRSMP_Type11 1;
BA_ "GenSigSendType" SG_ 2152136704 RRSMP_Type11 12;
BA_ "GenSigSendOnInit" SG_ 2152136704 RRSMP_Type11 2;
BA_ "SignalType" SG_ 2152136704 RRSMP_Type11 "UNM";
BA_ "PacketOrder" SG_ 2152136704 RRSMP_Type11 11;
BA_ "SignalLongName" SG_ 2152136704 RRSMP_Type11 "Right Rear Seat Massage Priority : Type 11";
BA_ "VNSigAllNodes" SG_ 2152136704 RRSMP_Type11 1;
BA_ "GenSigDeltaValue" SG_ 2152136704 RRSMP_Type10 1;
BA_ "GenSigSendType" SG_ 2152136704 RRSMP_Type10 12;
BA_ "GenSigSendOnInit" SG_ 2152136704 RRSMP_Type10 2;
BA_ "SignalType" SG_ 2152136704 RRSMP_Type10 "UNM";
BA_ "PacketOrder" SG_ 2152136704 RRSMP_Type10 10;
BA_ "SignalLongName" SG_ 2152136704 RRSMP_Type10 "Right Rear Seat Massage Priority : Type 10";
BA_ "VNSigAllNodes" SG_ 2152136704 RRSMP_Type10 1;
BA_ "GenSigDeltaValue" SG_ 2152136704 RRSMP_Type9 1;
BA_ "GenSigSendType" SG_ 2152136704 RRSMP_Type9 12;
BA_ "GenSigSendOnInit" SG_ 2152136704 RRSMP_Type9 2;
BA_ "SignalType" SG_ 2152136704 RRSMP_Type9 "UNM";
BA_ "PacketOrder" SG_ 2152136704 RRSMP_Type9 9;
BA_ "SignalLongName" SG_ 2152136704 RRSMP_Type9 "Right Rear Seat Massage Priority : Type 9";
BA_ "VNSigAllNodes" SG_ 2152136704 RRSMP_Type9 1;
BA_ "GenSigDeltaValue" SG_ 2152136704 RRSMP_Type8 1;
BA_ "GenSigSendType" SG_ 2152136704 RRSMP_Type8 12;
BA_ "GenSigSendOnInit" SG_ 2152136704 RRSMP_Type8 2;
BA_ "SignalType" SG_ 2152136704 RRSMP_Type8 "UNM";
BA_ "PacketOrder" SG_ 2152136704 RRSMP_Type8 8;
BA_ "SignalLongName" SG_ 2152136704 RRSMP_Type8 "Right Rear Seat Massage Priority : Type 8";
BA_ "VNSigAllNodes" SG_ 2152136704 RRSMP_Type8 1;
BA_ "GenSigDeltaValue" SG_ 2152136704 RRSMP_Type7 1;
BA_ "GenSigSendType" SG_ 2152136704 RRSMP_Type7 12;
BA_ "GenSigSendOnInit" SG_ 2152136704 RRSMP_Type7 2;
BA_ "SignalType" SG_ 2152136704 RRSMP_Type7 "UNM";
BA_ "PacketOrder" SG_ 2152136704 RRSMP_Type7 7;
BA_ "SignalLongName" SG_ 2152136704 RRSMP_Type7 "Right Rear Seat Massage Priority : Type 7";
BA_ "VNSigAllNodes" SG_ 2152136704 RRSMP_Type7 1;
BA_ "GenSigDeltaValue" SG_ 2152136704 RRSMP_Type6 1;
BA_ "GenSigSendType" SG_ 2152136704 RRSMP_Type6 12;
BA_ "GenSigSendOnInit" SG_ 2152136704 RRSMP_Type6 2;
BA_ "SignalType" SG_ 2152136704 RRSMP_Type6 "UNM";
BA_ "PacketOrder" SG_ 2152136704 RRSMP_Type6 6;
BA_ "SignalLongName" SG_ 2152136704 RRSMP_Type6 "Right Rear Seat Massage Priority : Type 6";
BA_ "VNSigAllNodes" SG_ 2152136704 RRSMP_Type6 1;
BA_ "GenSigDeltaValue" SG_ 2152136704 RRSMP_Type5 1;
BA_ "GenSigSendType" SG_ 2152136704 RRSMP_Type5 12;
BA_ "GenSigSendOnInit" SG_ 2152136704 RRSMP_Type5 2;
BA_ "SignalType" SG_ 2152136704 RRSMP_Type5 "UNM";
BA_ "PacketOrder" SG_ 2152136704 RRSMP_Type5 5;
BA_ "SignalLongName" SG_ 2152136704 RRSMP_Type5 "Right Rear Seat Massage Priority : Type 5";
BA_ "VNSigAllNodes" SG_ 2152136704 RRSMP_Type5 1;
BA_ "GenSigDeltaValue" SG_ 2152136704 RRSMP_Type4 1;
BA_ "GenSigSendType" SG_ 2152136704 RRSMP_Type4 12;
BA_ "GenSigSendOnInit" SG_ 2152136704 RRSMP_Type4 2;
BA_ "SignalType" SG_ 2152136704 RRSMP_Type4 "UNM";
BA_ "PacketOrder" SG_ 2152136704 RRSMP_Type4 4;
BA_ "SignalLongName" SG_ 2152136704 RRSMP_Type4 "Right Rear Seat Massage Priority : Type 4";
BA_ "VNSigAllNodes" SG_ 2152136704 RRSMP_Type4 1;
BA_ "GenSigDeltaValue" SG_ 2152136704 RRSMP_Type3 1;
BA_ "GenSigSendType" SG_ 2152136704 RRSMP_Type3 12;
BA_ "GenSigSendOnInit" SG_ 2152136704 RRSMP_Type3 2;
BA_ "SignalType" SG_ 2152136704 RRSMP_Type3 "UNM";
BA_ "PacketOrder" SG_ 2152136704 RRSMP_Type3 3;
BA_ "SignalLongName" SG_ 2152136704 RRSMP_Type3 "Right Rear Seat Massage Priority : Type 3";
BA_ "VNSigAllNodes" SG_ 2152136704 RRSMP_Type3 1;
BA_ "GenSigDeltaValue" SG_ 2152136704 RRSMP_Type2 1;
BA_ "GenSigSendType" SG_ 2152136704 RRSMP_Type2 12;
BA_ "GenSigSendOnInit" SG_ 2152136704 RRSMP_Type2 2;
BA_ "SignalType" SG_ 2152136704 RRSMP_Type2 "UNM";
BA_ "PacketOrder" SG_ 2152136704 RRSMP_Type2 2;
BA_ "SignalLongName" SG_ 2152136704 RRSMP_Type2 "Right Rear Seat Massage Priority : Type 2";
BA_ "VNSigAllNodes" SG_ 2152136704 RRSMP_Type2 1;
BA_ "GenSigDeltaValue" SG_ 2152136704 RRSMP_Type1 1;
BA_ "GenSigSendType" SG_ 2152136704 RRSMP_Type1 12;
BA_ "GenSigSendOnInit" SG_ 2152136704 RRSMP_Type1 2;
BA_ "SignalType" SG_ 2152136704 RRSMP_Type1 "UNM";
BA_ "PacketOrder" SG_ 2152136704 RRSMP_Type1 1;
BA_ "SignalLongName" SG_ 2152136704 RRSMP_Type1 "Right Rear Seat Massage Priority : Type 1";
BA_ "VNSigAllNodes" SG_ 2152136704 RRSMP_Type1 1;
BA_ "GenSigSendType" SG_ 2155151360 PSMP_UnsdRsrvd 10;
BA_ "GenSigSendOnInit" SG_ 2155151360 PSMP_UnsdRsrvd 2;
BA_ "SignalType" SG_ 2155151360 PSMP_UnsdRsrvd "BLN";
BA_ "PacketOrder" SG_ 2155151360 PSMP_UnsdRsrvd 17;
BA_ "SignalLongName" SG_ 2155151360 PSMP_UnsdRsrvd "Passenger Seat Massage Priority : Unused and Reserved";
BA_ "VNSigAllNodes" SG_ 2155151360 PSMP_UnsdRsrvd 1;
BA_ "GenSigDeltaValue" SG_ 2155151360 PSMP_MaxDispVal 1;
BA_ "GenSigSendType" SG_ 2155151360 PSMP_MaxDispVal 12;
BA_ "GenSigSendOnInit" SG_ 2155151360 PSMP_MaxDispVal 2;
BA_ "SignalType" SG_ 2155151360 PSMP_MaxDispVal "UNM";
BA_ "PacketOrder" SG_ 2155151360 PSMP_MaxDispVal 16;
BA_ "SignalLongName" SG_ 2155151360 PSMP_MaxDispVal "Passenger Seat Massage Priority : Maximum Display Value";
BA_ "VNSigAllNodes" SG_ 2155151360 PSMP_MaxDispVal 1;
BA_ "GenSigDeltaValue" SG_ 2155151360 PSMP_Type15 1;
BA_ "GenSigSendType" SG_ 2155151360 PSMP_Type15 12;
BA_ "GenSigSendOnInit" SG_ 2155151360 PSMP_Type15 2;
BA_ "SignalType" SG_ 2155151360 PSMP_Type15 "UNM";
BA_ "PacketOrder" SG_ 2155151360 PSMP_Type15 15;
BA_ "SignalLongName" SG_ 2155151360 PSMP_Type15 "Passenger Seat Massage Priority : Type 15";
BA_ "VNSigAllNodes" SG_ 2155151360 PSMP_Type15 1;
BA_ "GenSigDeltaValue" SG_ 2155151360 PSMP_Type14 1;
BA_ "GenSigSendType" SG_ 2155151360 PSMP_Type14 12;
BA_ "GenSigSendOnInit" SG_ 2155151360 PSMP_Type14 2;
BA_ "SignalType" SG_ 2155151360 PSMP_Type14 "UNM";
BA_ "PacketOrder" SG_ 2155151360 PSMP_Type14 14;
BA_ "SignalLongName" SG_ 2155151360 PSMP_Type14 "Passenger Seat Massage Priority : Type 14";
BA_ "VNSigAllNodes" SG_ 2155151360 PSMP_Type14 1;
BA_ "GenSigDeltaValue" SG_ 2155151360 PSMP_Type13 1;
BA_ "GenSigSendType" SG_ 2155151360 PSMP_Type13 12;
BA_ "GenSigSendOnInit" SG_ 2155151360 PSMP_Type13 2;
BA_ "SignalType" SG_ 2155151360 PSMP_Type13 "UNM";
BA_ "PacketOrder" SG_ 2155151360 PSMP_Type13 13;
BA_ "SignalLongName" SG_ 2155151360 PSMP_Type13 "Passenger Seat Massage Priority : Type 13";
BA_ "VNSigAllNodes" SG_ 2155151360 PSMP_Type13 1;
BA_ "GenSigDeltaValue" SG_ 2155151360 PSMP_Type12 1;
BA_ "GenSigSendType" SG_ 2155151360 PSMP_Type12 12;
BA_ "GenSigSendOnInit" SG_ 2155151360 PSMP_Type12 2;
BA_ "SignalType" SG_ 2155151360 PSMP_Type12 "UNM";
BA_ "PacketOrder" SG_ 2155151360 PSMP_Type12 12;
BA_ "SignalLongName" SG_ 2155151360 PSMP_Type12 "Passenger Seat Massage Priority : Type 12";
BA_ "VNSigAllNodes" SG_ 2155151360 PSMP_Type12 1;
BA_ "GenSigDeltaValue" SG_ 2155151360 PSMP_Type11 1;
BA_ "GenSigSendType" SG_ 2155151360 PSMP_Type11 12;
BA_ "GenSigSendOnInit" SG_ 2155151360 PSMP_Type11 2;
BA_ "SignalType" SG_ 2155151360 PSMP_Type11 "UNM";
BA_ "PacketOrder" SG_ 2155151360 PSMP_Type11 11;
BA_ "SignalLongName" SG_ 2155151360 PSMP_Type11 "Passenger Seat Massage Priority : Type 11";
BA_ "VNSigAllNodes" SG_ 2155151360 PSMP_Type11 1;
BA_ "GenSigDeltaValue" SG_ 2155151360 PSMP_Type10 1;
BA_ "GenSigSendType" SG_ 2155151360 PSMP_Type10 12;
BA_ "GenSigSendOnInit" SG_ 2155151360 PSMP_Type10 2;
BA_ "SignalType" SG_ 2155151360 PSMP_Type10 "UNM";
BA_ "PacketOrder" SG_ 2155151360 PSMP_Type10 10;
BA_ "SignalLongName" SG_ 2155151360 PSMP_Type10 "Passenger Seat Massage Priority : Type 10";
BA_ "VNSigAllNodes" SG_ 2155151360 PSMP_Type10 1;
BA_ "GenSigDeltaValue" SG_ 2155151360 PSMP_Type9 1;
BA_ "GenSigSendType" SG_ 2155151360 PSMP_Type9 12;
BA_ "GenSigSendOnInit" SG_ 2155151360 PSMP_Type9 2;
BA_ "SignalType" SG_ 2155151360 PSMP_Type9 "UNM";
BA_ "PacketOrder" SG_ 2155151360 PSMP_Type9 9;
BA_ "SignalLongName" SG_ 2155151360 PSMP_Type9 "Passenger Seat Massage Priority : Type 9";
BA_ "VNSigAllNodes" SG_ 2155151360 PSMP_Type9 1;
BA_ "GenSigDeltaValue" SG_ 2155151360 PSMP_Type8 1;
BA_ "GenSigSendType" SG_ 2155151360 PSMP_Type8 12;
BA_ "GenSigSendOnInit" SG_ 2155151360 PSMP_Type8 2;
BA_ "SignalType" SG_ 2155151360 PSMP_Type8 "UNM";
BA_ "PacketOrder" SG_ 2155151360 PSMP_Type8 8;
BA_ "SignalLongName" SG_ 2155151360 PSMP_Type8 "Passenger Seat Massage Priority : Type 8";
BA_ "VNSigAllNodes" SG_ 2155151360 PSMP_Type8 1;
BA_ "GenSigDeltaValue" SG_ 2155151360 PSMP_Type7 1;
BA_ "GenSigSendType" SG_ 2155151360 PSMP_Type7 12;
BA_ "GenSigSendOnInit" SG_ 2155151360 PSMP_Type7 2;
BA_ "SignalType" SG_ 2155151360 PSMP_Type7 "UNM";
BA_ "PacketOrder" SG_ 2155151360 PSMP_Type7 7;
BA_ "SignalLongName" SG_ 2155151360 PSMP_Type7 "Passenger Seat Massage Priority : Type 7";
BA_ "VNSigAllNodes" SG_ 2155151360 PSMP_Type7 1;
BA_ "GenSigDeltaValue" SG_ 2155151360 PSMP_Type6 1;
BA_ "GenSigSendType" SG_ 2155151360 PSMP_Type6 12;
BA_ "GenSigSendOnInit" SG_ 2155151360 PSMP_Type6 2;
BA_ "SignalType" SG_ 2155151360 PSMP_Type6 "UNM";
BA_ "PacketOrder" SG_ 2155151360 PSMP_Type6 6;
BA_ "SignalLongName" SG_ 2155151360 PSMP_Type6 "Passenger Seat Massage Priority : Type 6";
BA_ "VNSigAllNodes" SG_ 2155151360 PSMP_Type6 1;
BA_ "GenSigDeltaValue" SG_ 2155151360 PSMP_Type5 1;
BA_ "GenSigSendType" SG_ 2155151360 PSMP_Type5 12;
BA_ "GenSigSendOnInit" SG_ 2155151360 PSMP_Type5 2;
BA_ "SignalType" SG_ 2155151360 PSMP_Type5 "UNM";
BA_ "PacketOrder" SG_ 2155151360 PSMP_Type5 5;
BA_ "SignalLongName" SG_ 2155151360 PSMP_Type5 "Passenger Seat Massage Priority : Type 5";
BA_ "VNSigAllNodes" SG_ 2155151360 PSMP_Type5 1;
BA_ "GenSigDeltaValue" SG_ 2155151360 PSMP_Type4 1;
BA_ "GenSigSendType" SG_ 2155151360 PSMP_Type4 12;
BA_ "GenSigSendOnInit" SG_ 2155151360 PSMP_Type4 2;
BA_ "SignalType" SG_ 2155151360 PSMP_Type4 "UNM";
BA_ "PacketOrder" SG_ 2155151360 PSMP_Type4 4;
BA_ "SignalLongName" SG_ 2155151360 PSMP_Type4 "Passenger Seat Massage Priority : Type 4";
BA_ "VNSigAllNodes" SG_ 2155151360 PSMP_Type4 1;
BA_ "GenSigDeltaValue" SG_ 2155151360 PSMP_Type3 1;
BA_ "GenSigSendType" SG_ 2155151360 PSMP_Type3 12;
BA_ "GenSigSendOnInit" SG_ 2155151360 PSMP_Type3 2;
BA_ "SignalType" SG_ 2155151360 PSMP_Type3 "UNM";
BA_ "PacketOrder" SG_ 2155151360 PSMP_Type3 3;
BA_ "SignalLongName" SG_ 2155151360 PSMP_Type3 "Passenger Seat Massage Priority : Type 3";
BA_ "VNSigAllNodes" SG_ 2155151360 PSMP_Type3 1;
BA_ "GenSigDeltaValue" SG_ 2155151360 PSMP_Type2 1;
BA_ "GenSigSendType" SG_ 2155151360 PSMP_Type2 12;
BA_ "GenSigSendOnInit" SG_ 2155151360 PSMP_Type2 2;
BA_ "SignalType" SG_ 2155151360 PSMP_Type2 "UNM";
BA_ "PacketOrder" SG_ 2155151360 PSMP_Type2 2;
BA_ "SignalLongName" SG_ 2155151360 PSMP_Type2 "Passenger Seat Massage Priority : Type 2";
BA_ "VNSigAllNodes" SG_ 2155151360 PSMP_Type2 1;
BA_ "GenSigDeltaValue" SG_ 2155151360 PSMP_Type1 1;
BA_ "GenSigSendType" SG_ 2155151360 PSMP_Type1 12;
BA_ "GenSigSendOnInit" SG_ 2155151360 PSMP_Type1 2;
BA_ "SignalType" SG_ 2155151360 PSMP_Type1 "UNM";
BA_ "PacketOrder" SG_ 2155151360 PSMP_Type1 1;
BA_ "SignalLongName" SG_ 2155151360 PSMP_Type1 "Passenger Seat Massage Priority : Type 1";
BA_ "VNSigAllNodes" SG_ 2155151360 PSMP_Type1 1;
BA_ "GenSigDeltaValue" SG_ 2155134976 PSCDS_UnsdRsrvd 1;
BA_ "GenSigSendType" SG_ 2155134976 PSCDS_UnsdRsrvd 12;
BA_ "GenSigSendOnInit" SG_ 2155134976 PSCDS_UnsdRsrvd 2;
BA_ "SignalType" SG_ 2155134976 PSCDS_UnsdRsrvd "UNM";
BA_ "PacketOrder" SG_ 2155134976 PSCDS_UnsdRsrvd 19;
BA_ "SignalLongName" SG_ 2155134976 PSCDS_UnsdRsrvd "Passenger Seat Control Display Status : Unused and Reserved";
BA_ "VNSigAllNodes" SG_ 2155134976 PSCDS_UnsdRsrvd 1;
BA_ "GenSigSendType" SG_ 2155134976 PSCDS_DispReq 10;
BA_ "GenSigSendOnInit" SG_ 2155134976 PSCDS_DispReq 2;
BA_ "SignalType" SG_ 2155134976 PSCDS_DispReq "BLN";
BA_ "PacketOrder" SG_ 2155134976 PSCDS_DispReq 18;
BA_ "SignalLongName" SG_ 2155134976 PSCDS_DispReq "Passenger Seat Control Display Status : Display Request";
BA_ "VNSigAllNodes" SG_ 2155134976 PSCDS_DispReq 1;
BA_ "GenSigSendType" SG_ 2155134976 PSCDS_DispSz 10;
BA_ "GenSigSendOnInit" SG_ 2155134976 PSCDS_DispSz 2;
BA_ "SignalType" SG_ 2155134976 PSCDS_DispSz "ENM";
BA_ "PacketOrder" SG_ 2155134976 PSCDS_DispSz 17;
BA_ "SignalLongName" SG_ 2155134976 PSCDS_DispSz "Passenger Seat Control Display Status : Display Size";
BA_ "VNSigAllNodes" SG_ 2155134976 PSCDS_DispSz 1;
BA_ "GenSigSendType" SG_ 2155134976 PSCDS_CshLgAdjFdRr 10;
BA_ "GenSigSendOnInit" SG_ 2155134976 PSCDS_CshLgAdjFdRr 2;
BA_ "SignalType" SG_ 2155134976 PSCDS_CshLgAdjFdRr "ENM";
BA_ "PacketOrder" SG_ 2155134976 PSCDS_CshLgAdjFdRr 16;
BA_ "SignalLongName" SG_ 2155134976 PSCDS_CshLgAdjFdRr "Passenger Seat Control Display Status : Cushion Length Adjustment Forward/Rearward";
BA_ "VNSigAllNodes" SG_ 2155134976 PSCDS_CshLgAdjFdRr 1;
BA_ "GenSigSendType" SG_ 2155134976 PSCDS_BkCshBlstInOt 10;
BA_ "GenSigSendOnInit" SG_ 2155134976 PSCDS_BkCshBlstInOt 2;
BA_ "SignalType" SG_ 2155134976 PSCDS_BkCshBlstInOt "ENM";
BA_ "PacketOrder" SG_ 2155134976 PSCDS_BkCshBlstInOt 15;
BA_ "SignalLongName" SG_ 2155134976 PSCDS_BkCshBlstInOt "Passenger Seat Control Display Status : Back and Cushion Bolster In/Out";
BA_ "VNSigAllNodes" SG_ 2155134976 PSCDS_BkCshBlstInOt 1;
BA_ "GenSigSendType" SG_ 2155134976 PSCDS_CshBlstrInOut 10;
BA_ "GenSigSendOnInit" SG_ 2155134976 PSCDS_CshBlstrInOut 2;
BA_ "SignalType" SG_ 2155134976 PSCDS_CshBlstrInOut "ENM";
BA_ "PacketOrder" SG_ 2155134976 PSCDS_CshBlstrInOut 14;
BA_ "SignalLongName" SG_ 2155134976 PSCDS_CshBlstrInOut "Passenger Seat Control Display Status : Cushion Bolster In/Out";
BA_ "VNSigAllNodes" SG_ 2155134976 PSCDS_CshBlstrInOut 1;
BA_ "GenSigSendType" SG_ 2155134976 PSCDS_BkBlstrInOut 10;
BA_ "GenSigSendOnInit" SG_ 2155134976 PSCDS_BkBlstrInOut 2;
BA_ "SignalType" SG_ 2155134976 PSCDS_BkBlstrInOut "ENM";
BA_ "PacketOrder" SG_ 2155134976 PSCDS_BkBlstrInOut 13;
BA_ "SignalLongName" SG_ 2155134976 PSCDS_BkBlstrInOut "Passenger Seat Control Display Status : Back Bolster In/Out";
BA_ "VNSigAllNodes" SG_ 2155134976 PSCDS_BkBlstrInOut 1;
BA_ "GenSigSendType" SG_ 2155134976 PSCDS_LmbrUDnFdRr 10;
BA_ "GenSigSendOnInit" SG_ 2155134976 PSCDS_LmbrUDnFdRr 2;
BA_ "SignalType" SG_ 2155134976 PSCDS_LmbrUDnFdRr "ENM";
BA_ "PacketOrder" SG_ 2155134976 PSCDS_LmbrUDnFdRr 12;
BA_ "SignalLongName" SG_ 2155134976 PSCDS_LmbrUDnFdRr "Passenger Seat Control Display Status : Lumbar Up/Down and Forward/Rearward";
BA_ "VNSigAllNodes" SG_ 2155134976 PSCDS_LmbrUDnFdRr 1;
BA_ "GenSigSendType" SG_ 2155134976 PSCDS_LmbrFwdRr 10;
BA_ "GenSigSendOnInit" SG_ 2155134976 PSCDS_LmbrFwdRr 2;
BA_ "SignalType" SG_ 2155134976 PSCDS_LmbrFwdRr "ENM";
BA_ "PacketOrder" SG_ 2155134976 PSCDS_LmbrFwdRr 11;
BA_ "SignalLongName" SG_ 2155134976 PSCDS_LmbrFwdRr "Passenger Seat Control Display Status : Lumbar Forward/Rearward";
BA_ "VNSigAllNodes" SG_ 2155134976 PSCDS_LmbrFwdRr 1;
BA_ "GenSigSendType" SG_ 2155134976 PSCDS_LmbrUpDwn 10;
BA_ "GenSigSendOnInit" SG_ 2155134976 PSCDS_LmbrUpDwn 2;
BA_ "SignalType" SG_ 2155134976 PSCDS_LmbrUpDwn "ENM";
BA_ "PacketOrder" SG_ 2155134976 PSCDS_LmbrUpDwn 10;
BA_ "SignalLongName" SG_ 2155134976 PSCDS_LmbrUpDwn "Passenger Seat Control Display Status : Lumbar Up/Down";
BA_ "VNSigAllNodes" SG_ 2155134976 PSCDS_LmbrUpDwn 1;
BA_ "GenSigSendType" SG_ 2155134976 PSCDS_UprShldrFdRr 10;
BA_ "GenSigSendOnInit" SG_ 2155134976 PSCDS_UprShldrFdRr 2;
BA_ "SignalType" SG_ 2155134976 PSCDS_UprShldrFdRr "ENM";
BA_ "PacketOrder" SG_ 2155134976 PSCDS_UprShldrFdRr 9;
BA_ "SignalLongName" SG_ 2155134976 PSCDS_UprShldrFdRr "Passenger Seat Control Display Status : Upper Shoulder Forward/Rearward";
BA_ "VNSigAllNodes" SG_ 2155134976 PSCDS_UprShldrFdRr 1;
BA_ "GenSigSendType" SG_ 2155134976 PSCDS_HdrstTltFwdRr 10;
BA_ "GenSigSendOnInit" SG_ 2155134976 PSCDS_HdrstTltFwdRr 2;
BA_ "SignalType" SG_ 2155134976 PSCDS_HdrstTltFwdRr "ENM";
BA_ "PacketOrder" SG_ 2155134976 PSCDS_HdrstTltFwdRr 8;
BA_ "SignalLongName" SG_ 2155134976 PSCDS_HdrstTltFwdRr "Passenger Seat Control Display Status : Headrest Tilt Forward/Rearward";
BA_ "VNSigAllNodes" SG_ 2155134976 PSCDS_HdrstTltFwdRr 1;
BA_ "GenSigSendType" SG_ 2155134976 PSCDS_HdrstWngInOt 10;
BA_ "GenSigSendOnInit" SG_ 2155134976 PSCDS_HdrstWngInOt 2;
BA_ "SignalType" SG_ 2155134976 PSCDS_HdrstWngInOt "ENM";
BA_ "PacketOrder" SG_ 2155134976 PSCDS_HdrstWngInOt 7;
BA_ "SignalLongName" SG_ 2155134976 PSCDS_HdrstWngInOt "Passenger Seat Control Display Status : Headrest Wings In/Out";
BA_ "VNSigAllNodes" SG_ 2155134976 PSCDS_HdrstWngInOt 1;
BA_ "GenSigSendType" SG_ 2155134976 PSCDS_HdrstUDnFdRr 10;
BA_ "GenSigSendOnInit" SG_ 2155134976 PSCDS_HdrstUDnFdRr 2;
BA_ "SignalType" SG_ 2155134976 PSCDS_HdrstUDnFdRr "ENM";
BA_ "PacketOrder" SG_ 2155134976 PSCDS_HdrstUDnFdRr 6;
BA_ "SignalLongName" SG_ 2155134976 PSCDS_HdrstUDnFdRr "Passenger Seat Control Display Status : Headrest Forward/Rearward and Up/Down";
BA_ "VNSigAllNodes" SG_ 2155134976 PSCDS_HdrstUDnFdRr 1;
BA_ "GenSigSendType" SG_ 2155134976 PSCDS_HdrstFwdRrwd 10;
BA_ "GenSigSendOnInit" SG_ 2155134976 PSCDS_HdrstFwdRrwd 2;
BA_ "SignalType" SG_ 2155134976 PSCDS_HdrstFwdRrwd "ENM";
BA_ "PacketOrder" SG_ 2155134976 PSCDS_HdrstFwdRrwd 5;
BA_ "SignalLongName" SG_ 2155134976 PSCDS_HdrstFwdRrwd "Passenger Seat Control Display Status : Headrest Forward/Rearward";
BA_ "VNSigAllNodes" SG_ 2155134976 PSCDS_HdrstFwdRrwd 1;
BA_ "GenSigSendType" SG_ 2155134976 PSCDS_HdrstUpDn 10;
BA_ "GenSigSendOnInit" SG_ 2155134976 PSCDS_HdrstUpDn 2;
BA_ "SignalType" SG_ 2155134976 PSCDS_HdrstUpDn "ENM";
BA_ "PacketOrder" SG_ 2155134976 PSCDS_HdrstUpDn 4;
BA_ "SignalLongName" SG_ 2155134976 PSCDS_HdrstUpDn "Passenger Seat Control Display Status : Headrest Up/Down";
BA_ "VNSigAllNodes" SG_ 2155134976 PSCDS_HdrstUpDn 1;
BA_ "GenSigSendType" SG_ 2155134976 PSCDS_MassgIntsty 10;
BA_ "GenSigSendOnInit" SG_ 2155134976 PSCDS_MassgIntsty 2;
BA_ "SignalType" SG_ 2155134976 PSCDS_MassgIntsty "ENM";
BA_ "PacketOrder" SG_ 2155134976 PSCDS_MassgIntsty 3;
BA_ "SignalLongName" SG_ 2155134976 PSCDS_MassgIntsty "Passenger Seat Control Display Status : Massage Intensity";
BA_ "VNSigAllNodes" SG_ 2155134976 PSCDS_MassgIntsty 1;
BA_ "GenSigSendType" SG_ 2155134976 PSCDS_MassgTyp 10;
BA_ "GenSigSendOnInit" SG_ 2155134976 PSCDS_MassgTyp 2;
BA_ "SignalType" SG_ 2155134976 PSCDS_MassgTyp "ENM";
BA_ "PacketOrder" SG_ 2155134976 PSCDS_MassgTyp 2;
BA_ "SignalLongName" SG_ 2155134976 PSCDS_MassgTyp "Passenger Seat Control Display Status : Massage Type";
BA_ "VNSigAllNodes" SG_ 2155134976 PSCDS_MassgTyp 1;
BA_ "GenSigSendType" SG_ 2155134976 PSCDS_Massg 10;
BA_ "GenSigSendOnInit" SG_ 2155134976 PSCDS_Massg 2;
BA_ "SignalType" SG_ 2155134976 PSCDS_Massg "ENM";
BA_ "PacketOrder" SG_ 2155134976 PSCDS_Massg 1;
BA_ "SignalLongName" SG_ 2155134976 PSCDS_Massg "Passenger Seat Control Display Status : Massage";
BA_ "VNSigAllNodes" SG_ 2155134976 PSCDS_Massg 1;
BA_ "GenSigSendType" SG_ 2155134976 PsngrSetRrwdMvmnt 10;
BA_ "SignalType" SG_ 2155134976 PsngrSetRrwdMvmnt "ENM";
BA_ "SignalLongName" SG_ 2155134976 PsngrSetRrwdMvmnt "Passenger Seat Rearward Movement";
BA_ "VNSigAllNodes" SG_ 2155134976 PsngrSetRrwdMvmnt 1;
BA_ "GenSigDeltaValue" SG_ 2155118592 PSAP_UnsdRsrvd 1;
BA_ "GenSigSendType" SG_ 2155118592 PSAP_UnsdRsrvd 12;
BA_ "GenSigSendOnInit" SG_ 2155118592 PSAP_UnsdRsrvd 2;
BA_ "SignalType" SG_ 2155118592 PSAP_UnsdRsrvd "UNM";
BA_ "PacketOrder" SG_ 2155118592 PSAP_UnsdRsrvd 16;
BA_ "SignalLongName" SG_ 2155118592 PSAP_UnsdRsrvd "Passenger Seat Actuator Priority : Unused and Reserved";
BA_ "VNSigAllNodes" SG_ 2155118592 PSAP_UnsdRsrvd 1;
BA_ "GenSigDeltaValue" SG_ 2155118592 PSAP_DispSz 1;
BA_ "GenSigSendType" SG_ 2155118592 PSAP_DispSz 12;
BA_ "GenSigSendOnInit" SG_ 2155118592 PSAP_DispSz 2;
BA_ "SignalType" SG_ 2155118592 PSAP_DispSz "UNM";
BA_ "PacketOrder" SG_ 2155118592 PSAP_DispSz 15;
BA_ "SignalLongName" SG_ 2155118592 PSAP_DispSz "Passenger Seat Actuator Priority : Display Size";
BA_ "VNSigAllNodes" SG_ 2155118592 PSAP_DispSz 1;
BA_ "GenSigDeltaValue" SG_ 2155118592 PSAP_CshLgthAdjFdRr 1;
BA_ "GenSigSendType" SG_ 2155118592 PSAP_CshLgthAdjFdRr 12;
BA_ "GenSigSendOnInit" SG_ 2155118592 PSAP_CshLgthAdjFdRr 2;
BA_ "SignalType" SG_ 2155118592 PSAP_CshLgthAdjFdRr "UNM";
BA_ "PacketOrder" SG_ 2155118592 PSAP_CshLgthAdjFdRr 14;
BA_ "SignalLongName" SG_ 2155118592 PSAP_CshLgthAdjFdRr "Passenger Seat Actuator Priority : Cushion Length Adjustment Forward/Rearward";
BA_ "VNSigAllNodes" SG_ 2155118592 PSAP_CshLgthAdjFdRr 1;
BA_ "GenSigDeltaValue" SG_ 2155118592 PSAP_CshBlstrInOut 1;
BA_ "GenSigSendType" SG_ 2155118592 PSAP_CshBlstrInOut 12;
BA_ "GenSigSendOnInit" SG_ 2155118592 PSAP_CshBlstrInOut 2;
BA_ "SignalType" SG_ 2155118592 PSAP_CshBlstrInOut "UNM";
BA_ "PacketOrder" SG_ 2155118592 PSAP_CshBlstrInOut 12;
BA_ "SignalLongName" SG_ 2155118592 PSAP_CshBlstrInOut "Passenger Seat Actuator Priority : Cushion Bolster In/Out";
BA_ "VNSigAllNodes" SG_ 2155118592 PSAP_CshBlstrInOut 1;
BA_ "GenSigDeltaValue" SG_ 2155118592 PSAP_BkBlstrInOut 1;
BA_ "GenSigSendType" SG_ 2155118592 PSAP_BkBlstrInOut 12;
BA_ "GenSigSendOnInit" SG_ 2155118592 PSAP_BkBlstrInOut 2;
BA_ "SignalType" SG_ 2155118592 PSAP_BkBlstrInOut "UNM";
BA_ "PacketOrder" SG_ 2155118592 PSAP_BkBlstrInOut 11;
BA_ "SignalLongName" SG_ 2155118592 PSAP_BkBlstrInOut "Passenger Seat Actuator Priority : Back Bolster In/Out";
BA_ "VNSigAllNodes" SG_ 2155118592 PSAP_BkBlstrInOut 1;
BA_ "GenSigDeltaValue" SG_ 2155118592 PSAP_BkCshBlstrInOut 1;
BA_ "GenSigSendType" SG_ 2155118592 PSAP_BkCshBlstrInOut 12;
BA_ "GenSigSendOnInit" SG_ 2155118592 PSAP_BkCshBlstrInOut 2;
BA_ "SignalType" SG_ 2155118592 PSAP_BkCshBlstrInOut "UNM";
BA_ "PacketOrder" SG_ 2155118592 PSAP_BkCshBlstrInOut 13;
BA_ "SignalLongName" SG_ 2155118592 PSAP_BkCshBlstrInOut "Passenger Seat Actuator Priority : Back and Cushion Bolster In/Out";
BA_ "VNSigAllNodes" SG_ 2155118592 PSAP_BkCshBlstrInOut 1;
BA_ "GenSigDeltaValue" SG_ 2155118592 PSAP_LmbrUpDnFdRr 1;
BA_ "GenSigSendType" SG_ 2155118592 PSAP_LmbrUpDnFdRr 12;
BA_ "GenSigSendOnInit" SG_ 2155118592 PSAP_LmbrUpDnFdRr 2;
BA_ "SignalType" SG_ 2155118592 PSAP_LmbrUpDnFdRr "UNM";
BA_ "PacketOrder" SG_ 2155118592 PSAP_LmbrUpDnFdRr 10;
BA_ "SignalLongName" SG_ 2155118592 PSAP_LmbrUpDnFdRr "Passenger Seat Actuator Priority : Lumbar Up/Down and Forward/Rearward";
BA_ "VNSigAllNodes" SG_ 2155118592 PSAP_LmbrUpDnFdRr 1;
BA_ "GenSigDeltaValue" SG_ 2155118592 PSAP_LmbrFwdRr 1;
BA_ "GenSigSendType" SG_ 2155118592 PSAP_LmbrFwdRr 12;
BA_ "GenSigSendOnInit" SG_ 2155118592 PSAP_LmbrFwdRr 2;
BA_ "SignalType" SG_ 2155118592 PSAP_LmbrFwdRr "UNM";
BA_ "PacketOrder" SG_ 2155118592 PSAP_LmbrFwdRr 9;
BA_ "SignalLongName" SG_ 2155118592 PSAP_LmbrFwdRr "Passenger Seat Actuator Priority : Lumbar Forward/Rearward";
BA_ "VNSigAllNodes" SG_ 2155118592 PSAP_LmbrFwdRr 1;
BA_ "GenSigDeltaValue" SG_ 2155118592 PSAP_LmbrUpDwn 1;
BA_ "GenSigSendType" SG_ 2155118592 PSAP_LmbrUpDwn 12;
BA_ "GenSigSendOnInit" SG_ 2155118592 PSAP_LmbrUpDwn 2;
BA_ "SignalType" SG_ 2155118592 PSAP_LmbrUpDwn "UNM";
BA_ "PacketOrder" SG_ 2155118592 PSAP_LmbrUpDwn 8;
BA_ "SignalLongName" SG_ 2155118592 PSAP_LmbrUpDwn "Passenger Seat Actuator Priority : Lumbar Up/Down";
BA_ "VNSigAllNodes" SG_ 2155118592 PSAP_LmbrUpDwn 1;
BA_ "GenSigDeltaValue" SG_ 2155118592 PSAP_UprShldrFwdRr 1;
BA_ "GenSigSendType" SG_ 2155118592 PSAP_UprShldrFwdRr 12;
BA_ "GenSigSendOnInit" SG_ 2155118592 PSAP_UprShldrFwdRr 2;
BA_ "SignalType" SG_ 2155118592 PSAP_UprShldrFwdRr "UNM";
BA_ "PacketOrder" SG_ 2155118592 PSAP_UprShldrFwdRr 7;
BA_ "SignalLongName" SG_ 2155118592 PSAP_UprShldrFwdRr "Passenger Seat Actuator Priority : Upper Shoulder Forward/Rearward";
BA_ "VNSigAllNodes" SG_ 2155118592 PSAP_UprShldrFwdRr 1;
BA_ "GenSigDeltaValue" SG_ 2155118592 PSAP_HdrstTltFwdRr 1;
BA_ "GenSigSendType" SG_ 2155118592 PSAP_HdrstTltFwdRr 12;
BA_ "GenSigSendOnInit" SG_ 2155118592 PSAP_HdrstTltFwdRr 2;
BA_ "SignalType" SG_ 2155118592 PSAP_HdrstTltFwdRr "UNM";
BA_ "PacketOrder" SG_ 2155118592 PSAP_HdrstTltFwdRr 6;
BA_ "SignalLongName" SG_ 2155118592 PSAP_HdrstTltFwdRr "Passenger Seat Actuator Priority : Headrest Tilt Forward/Rearward";
BA_ "VNSigAllNodes" SG_ 2155118592 PSAP_HdrstTltFwdRr 1;
BA_ "GenSigDeltaValue" SG_ 2155118592 PSAP_HdrstWngsInOut 1;
BA_ "GenSigSendType" SG_ 2155118592 PSAP_HdrstWngsInOut 12;
BA_ "GenSigSendOnInit" SG_ 2155118592 PSAP_HdrstWngsInOut 2;
BA_ "SignalType" SG_ 2155118592 PSAP_HdrstWngsInOut "UNM";
BA_ "PacketOrder" SG_ 2155118592 PSAP_HdrstWngsInOut 5;
BA_ "SignalLongName" SG_ 2155118592 PSAP_HdrstWngsInOut "Passenger Seat Actuator Priority : Headrest Wings Inward/Outward";
BA_ "VNSigAllNodes" SG_ 2155118592 PSAP_HdrstWngsInOut 1;
BA_ "GenSigDeltaValue" SG_ 2155118592 PSAP_HdrstUpDnFdRr 1;
BA_ "GenSigSendType" SG_ 2155118592 PSAP_HdrstUpDnFdRr 12;
BA_ "GenSigSendOnInit" SG_ 2155118592 PSAP_HdrstUpDnFdRr 2;
BA_ "SignalType" SG_ 2155118592 PSAP_HdrstUpDnFdRr "UNM";
BA_ "PacketOrder" SG_ 2155118592 PSAP_HdrstUpDnFdRr 4;
BA_ "SignalLongName" SG_ 2155118592 PSAP_HdrstUpDnFdRr "Passenger Seat Actuator Priority : Headrest Up/Down and Forward/Rearward";
BA_ "VNSigAllNodes" SG_ 2155118592 PSAP_HdrstUpDnFdRr 1;
BA_ "GenSigDeltaValue" SG_ 2155118592 PSAP_HdrstFwdRrwd 1;
BA_ "GenSigSendType" SG_ 2155118592 PSAP_HdrstFwdRrwd 12;
BA_ "GenSigSendOnInit" SG_ 2155118592 PSAP_HdrstFwdRrwd 2;
BA_ "SignalType" SG_ 2155118592 PSAP_HdrstFwdRrwd "UNM";
BA_ "PacketOrder" SG_ 2155118592 PSAP_HdrstFwdRrwd 3;
BA_ "SignalLongName" SG_ 2155118592 PSAP_HdrstFwdRrwd "Passenger Seat Actuator Priority : Headrest Forward/Rearward";
BA_ "VNSigAllNodes" SG_ 2155118592 PSAP_HdrstFwdRrwd 1;
BA_ "GenSigDeltaValue" SG_ 2155118592 PSAP_HdrstUpDn 1;
BA_ "GenSigSendType" SG_ 2155118592 PSAP_HdrstUpDn 12;
BA_ "GenSigSendOnInit" SG_ 2155118592 PSAP_HdrstUpDn 2;
BA_ "SignalType" SG_ 2155118592 PSAP_HdrstUpDn "UNM";
BA_ "PacketOrder" SG_ 2155118592 PSAP_HdrstUpDn 2;
BA_ "SignalLongName" SG_ 2155118592 PSAP_HdrstUpDn "Passenger Seat Actuator Priority : Headrest Up/Down";
BA_ "VNSigAllNodes" SG_ 2155118592 PSAP_HdrstUpDn 1;
BA_ "GenSigDeltaValue" SG_ 2155118592 PSAP_Massg 1;
BA_ "GenSigSendType" SG_ 2155118592 PSAP_Massg 12;
BA_ "GenSigSendOnInit" SG_ 2155118592 PSAP_Massg 2;
BA_ "SignalType" SG_ 2155118592 PSAP_Massg "UNM";
BA_ "PacketOrder" SG_ 2155118592 PSAP_Massg 1;
BA_ "SignalLongName" SG_ 2155118592 PSAP_Massg "Passenger Seat Actuator Priority : Massage";
BA_ "VNSigAllNodes" SG_ 2155118592 PSAP_Massg 1;
BA_REL_ "GenSigSuprvResp" BU_SG_REL_ VCU_LE SG_ 2155536384 TnDrvRIMOffUnbIO 1;
BA_REL_ "GenSigSuprvResp" BU_SG_REL_ IPC_LE SG_ 2155536384 TnDrvRIMOffUnbIO 1;
BA_REL_ "GenSigSuprvResp" BU_SG_REL_ VCU_LE SG_ 2151235584 VhSecNImmoIndRq 1;
BA_REL_ "GenSigSuprvResp" BU_SG_REL_ IPC_LE SG_ 2151235584 VhSecNImmoIndRq 1;
BA_REL_ "GenSigSuprvResp" BU_SG_REL_ TCP_LE SG_ 2150776832 SIREvntSychCntr 1;
BA_REL_ "GenSigSuprvResp" BU_SG_REL_ ONSTAR_LE SG_ 2150776832 SIREvntSychCntr 1;
BA_REL_ "GenSigSuprvResp" BU_SG_REL_ VCU_LE SG_ 2155347968 DrvrStPerfMdCsCrStVal 1;
BA_REL_ "GenSigSuprvResp" BU_SG_REL_ CSM_LE SG_ 2155347968 DrvrStPerfMdCsCrStVal 1;
BA_REL_ "GenSigSuprvResp" BU_SG_REL_ RadioHead_LE SG_ 2155347968 DrvrStPerfMdCsCrStVal 1;
BA_REL_ "GenSigSuprvResp" BU_SG_REL_ VCU_LE SG_ 2155347968 DrvrStPerfMdCsStAvl 1;
BA_REL_ "GenSigSuprvResp" BU_SG_REL_ CSM_LE SG_ 2155347968 DrvrStPerfMdCsStAvl 1;
BA_REL_ "GenSigSuprvResp" BU_SG_REL_ RadioHead_LE SG_ 2155347968 DrvrStPerfMdCsStAvl 1;
BA_REL_ "GenSigSuprvResp" BU_SG_REL_ VCU_LE SG_ 2155347968 ACCPerfMdCsCrStVal 1;
BA_REL_ "GenSigSuprvResp" BU_SG_REL_ CSM_LE SG_ 2155347968 ACCPerfMdCsCrStVal 1;
BA_REL_ "GenSigSuprvResp" BU_SG_REL_ RadioHead_LE SG_ 2155347968 ACCPerfMdCsCrStVal 1;
BA_REL_ "GenSigSuprvResp" BU_SG_REL_ VCU_LE SG_ 2155347968 ACCPerfMdCsStAvl 1;
BA_REL_ "GenSigSuprvResp" BU_SG_REL_ CSM_LE SG_ 2155347968 ACCPerfMdCsStAvl 1;
BA_REL_ "GenSigSuprvResp" BU_SG_REL_ RadioHead_LE SG_ 2155347968 ACCPerfMdCsStAvl 1;
BA_REL_ "GenSigSuprvResp" BU_SG_REL_ VCU_LE SG_ 2155347968 ActVbnCtrlMlfIO 1;
BA_REL_ "GenSigSuprvResp" BU_SG_REL_ IPC_LE SG_ 2155347968 ActVbnCtrlMlfIO 1;
BA_REL_ "GenSigSuprvResp" BU_SG_REL_ VCU_LE SG_ 2155347968 HillDesCtrlRedVehSpIO 1;
BA_REL_ "GenSigSuprvResp" BU_SG_REL_ IPC_LE SG_ 2155347968 HillDesCtrlRedVehSpIO 1;
BA_REL_ "GenSigSuprvResp" BU_SG_REL_ VCU_LE SG_ 2155347968 FourWhlDrvIndReq 1;
BA_REL_ "GenSigSuprvResp" BU_SG_REL_ IPC_LE SG_ 2155347968 FourWhlDrvIndReq 1;
BA_REL_ "GenSigSuprvResp" BU_SG_REL_ IPC_LE SG_ 2155347968 PedtrnProtSysDisbld 1;
BA_REL_ "GenSigSuprvResp" BU_SG_REL_ VCU_LE SG_ 2155347968 PedtrnProtSysDisbld 1;
BA_REL_ "GenSigSuprvResp" BU_SG_REL_ IPC_LE SG_ 2155347968 PedtrnProtSysDpl 1;
BA_REL_ "GenSigSuprvResp" BU_SG_REL_ VCU_LE SG_ 2155347968 PedtrnProtSysDpl 1;
BA_REL_ "GenSigSuprvResp" BU_SG_REL_ IPC_LE SG_ 2155347968 SrvPedtrnProtSysIO 1;
BA_REL_ "GenSigSuprvResp" BU_SG_REL_ VCU_LE SG_ 2155347968 SrvPedtrnProtSysIO 1;
BA_REL_ "GenSigVDAFailComment" BU_SG_REL_ VCU_LE SG_ 2155347968 EPBSysStatIndReq "PrkBrkVDA";
BA_REL_ "GenSigVDAFailResp" BU_SG_REL_ VCU_LE SG_ 2155347968 EPBSysStatIndReq 1;
BA_REL_ "GenSigSuprvResp" BU_SG_REL_ VCU_LE SG_ 2155347968 EPBSysStatIndReq 1;
BA_REL_ "GenSigVDAFailComment" BU_SG_REL_ IPC_LE SG_ 2155347968 EPBSysStatIndReq "PrkBrkVDA";
BA_REL_ "GenSigVDAFailResp" BU_SG_REL_ IPC_LE SG_ 2155347968 EPBSysStatIndReq 1;
BA_REL_ "GenSigSuprvResp" BU_SG_REL_ IPC_LE SG_ 2155347968 EPBSysStatIndReq 1;
BA_REL_ "GenSigSuprvResp" BU_SG_REL_ VCU_LE SG_ 2155347968 SecAxlNonEmMalfIO 1;
BA_REL_ "GenSigSuprvResp" BU_SG_REL_ IPC_LE SG_ 2155347968 SecAxlNonEmMalfIO 1;
BA_REL_ "GenSigRxStartValue" BU_SG_REL_ VCU_LE SG_ 2155347968 EngEmsRelMalfIndReq "$0 - Continuous Indication";
BA_REL_ "GenSigRxStartValue" BU_SG_REL_ IPC_LE SG_ 2155347968 EngEmsRelMalfIndReq "$0 - Continuous Indication";
BA_REL_ "GenSigVDAFailComment" BU_SG_REL_ VCU_LE SG_ 2155347968 EPBSysWrnIndReq "PrkBrkVDA";
BA_REL_ "GenSigVDAFailResp" BU_SG_REL_ VCU_LE SG_ 2155347968 EPBSysWrnIndReq 1;
BA_REL_ "GenSigSuprvResp" BU_SG_REL_ VCU_LE SG_ 2155347968 EPBSysWrnIndReq 1;
BA_REL_ "GenSigVDAFailComment" BU_SG_REL_ IPC_LE SG_ 2155347968 EPBSysWrnIndReq "PrkBrkVDA";
BA_REL_ "GenSigVDAFailResp" BU_SG_REL_ IPC_LE SG_ 2155347968 EPBSysWrnIndReq 1;
BA_REL_ "GenSigSuprvResp" BU_SG_REL_ IPC_LE SG_ 2155347968 EPBSysWrnIndReq 1;
BA_REL_ "GenSigSuprvResp" BU_SG_REL_ VCU_LE SG_ 2153840640 TnDrvDRLOffUnbIO 1;
BA_REL_ "GenSigSuprvResp" BU_SG_REL_ IPC_LE SG_ 2153840640 TnDrvDRLOffUnbIO 1;
BA_REL_ "GenSigSuprvResp" BU_SG_REL_ VCU_LE SG_ 2153840640 TnDrvALCOffUnbIO 1;
BA_REL_ "GenSigSuprvResp" BU_SG_REL_ IPC_LE SG_ 2153840640 TnDrvALCOffUnbIO 1;
BA_REL_ "GenSigSuprvResp" BU_SG_REL_ VCU_LE SG_ 2155036672 ACCompNormLd 1;
BA_REL_ "GenSigSuprvResp" BU_SG_REL_ CSM_LE SG_ 2155036672 ACCompNormLd 1;
BA_REL_ "GenSigSuprvResp" BU_SG_REL_ RadioHead_LE SG_ 2155036672 ACCompNormLd 1;
BA_REL_ "GenSigSuprvResp" BU_SG_REL_ CSM_LE SG_ 2151112704 FrPasSeatbltRemOccSt 1;
BA_REL_ "GenSigSuprvResp" BU_SG_REL_ VCU_LE SG_ 2151112704 FrPasSeatbltRemOccSt 1;
BA_REL_ "GenSigSuprvResp" BU_SG_REL_ RadioHead_LE SG_ 2151112704 FrPasSeatbltRemOccSt 1;
BA_REL_ "GenSigSuprvResp" BU_SG_REL_ CSM_LE SG_ 2151112704 FrPasSeatResCtrlOccSt 1;
BA_REL_ "GenSigSuprvResp" BU_SG_REL_ VCU_LE SG_ 2151112704 FrPasSeatResCtrlOccSt 1;
BA_REL_ "GenSigSuprvResp" BU_SG_REL_ RadioHead_LE SG_ 2151112704 FrPasSeatResCtrlOccSt 1;
BA_REL_ "GenSigSuprvResp" BU_SG_REL_ CSM_LE SG_ 2151112704 FrPsSeatOccFltSt 1;
BA_REL_ "GenSigSuprvResp" BU_SG_REL_ VCU_LE SG_ 2151112704 FrPsSeatOccFltSt 1;
BA_REL_ "GenSigSuprvResp" BU_SG_REL_ RadioHead_LE SG_ 2151112704 FrPsSeatOccFltSt 1;
BA_REL_ "GenSigSuprvResp" BU_SG_REL_ CSM_LE SG_ 2151112704 FrntPassClass 1;
BA_REL_ "GenSigSuprvResp" BU_SG_REL_ VCU_LE SG_ 2151112704 FrntPassClass 1;
BA_REL_ "GenSigSuprvResp" BU_SG_REL_ RadioHead_LE SG_ 2151112704 FrntPassClass 1;
BA_REL_ "GenSigSuprvResp" BU_SG_REL_ VCU_LE SG_ 2151317504 PrkAstRrSysStat 1;
BA_REL_ "GenSigSuprvResp" BU_SG_REL_ IPC_LE SG_ 2151317504 PrkAstRrSysStat 1;
BA_REL_ "GenSigSuprvResp" BU_SG_REL_ VCU_LE SG_ 2152775680 CrgBdVwLtCustSetAvl 1;
BA_REL_ "GenSigSuprvResp" BU_SG_REL_ CSM_LE SG_ 2152775680 CrgBdVwLtCustSetAvl 1;
BA_REL_ "GenSigSuprvResp" BU_SG_REL_ RadioHead_LE SG_ 2152775680 CrgBdVwLtCustSetAvl 1;
BA_REL_ "GenSigSuprvResp" BU_SG_REL_ VCU_LE SG_ 2152775680 TrlrMirVGlnCustSetVal 1;
BA_REL_ "GenSigSuprvResp" BU_SG_REL_ CSM_LE SG_ 2152775680 TrlrMirVGlnCustSetVal 1;
BA_REL_ "GenSigSuprvResp" BU_SG_REL_ RadioHead_LE SG_ 2152775680 TrlrMirVGlnCustSetVal 1;
BA_REL_ "GenSigSuprvResp" BU_SG_REL_ VCU_LE SG_ 2152775680 TrlrMirVGlnCustSetAvl 1;
BA_REL_ "GenSigSuprvResp" BU_SG_REL_ CSM_LE SG_ 2152775680 TrlrMirVGlnCustSetAvl 1;
BA_REL_ "GenSigSuprvResp" BU_SG_REL_ RadioHead_LE SG_ 2152775680 TrlrMirVGlnCustSetAvl 1;
BA_REL_ "GenSigSuprvResp" BU_SG_REL_ VCU_LE SG_ 2152775680 TrlrMirVEnCustSetVal 1;
BA_REL_ "GenSigSuprvResp" BU_SG_REL_ CSM_LE SG_ 2152775680 TrlrMirVEnCustSetVal 1;
BA_REL_ "GenSigSuprvResp" BU_SG_REL_ RadioHead_LE SG_ 2152775680 TrlrMirVEnCustSetVal 1;
BA_REL_ "GenSigSuprvResp" BU_SG_REL_ VCU_LE SG_ 2152775680 TrlrMirVEnCustSetAvl 1;
BA_REL_ "GenSigSuprvResp" BU_SG_REL_ CSM_LE SG_ 2152775680 TrlrMirVEnCustSetAvl 1;
BA_REL_ "GenSigSuprvResp" BU_SG_REL_ RadioHead_LE SG_ 2152775680 TrlrMirVEnCustSetAvl 1;
BA_REL_ "GenSigSuprvResp" BU_SG_REL_ VCU_LE SG_ 2152775680 TrlrArtcltnAnglCalStat 1;
BA_REL_ "GenSigSuprvResp" BU_SG_REL_ CSM_LE SG_ 2152775680 TrlrArtcltnAnglCalStat 1;
BA_REL_ "GenSigSuprvResp" BU_SG_REL_ RadioHead_LE SG_ 2152775680 TrlrArtcltnAnglCalStat 1;
BA_REL_ "GenSigSuprvResp" BU_SG_REL_ VCU_LE SG_ 2152775680 InvTrlrAx1CamRollAlgnd 1;
BA_REL_ "GenSigSuprvResp" BU_SG_REL_ CSM_LE SG_ 2152775680 InvTrlrAx1CamRollAlgnd 1;
BA_REL_ "GenSigSuprvResp" BU_SG_REL_ RadioHead_LE SG_ 2152775680 InvTrlrAx1CamRollAlgnd 1;
BA_REL_ "GenSigSuprvResp" BU_SG_REL_ VCU_LE SG_ 2152775680 InvTrlrAx1CamPtchAlgnd 1;
BA_REL_ "GenSigSuprvResp" BU_SG_REL_ CSM_LE SG_ 2152775680 InvTrlrAx1CamPtchAlgnd 1;
BA_REL_ "GenSigSuprvResp" BU_SG_REL_ RadioHead_LE SG_ 2152775680 InvTrlrAx1CamPtchAlgnd 1;
BA_REL_ "GenSigSuprvResp" BU_SG_REL_ VCU_LE SG_ 2152775680 InvTrlrAx1CamYAlgnd 1;
BA_REL_ "GenSigSuprvResp" BU_SG_REL_ CSM_LE SG_ 2152775680 InvTrlrAx1CamYAlgnd 1;
BA_REL_ "GenSigSuprvResp" BU_SG_REL_ RadioHead_LE SG_ 2152775680 InvTrlrAx1CamYAlgnd 1;
BA_REL_ "GenSigSuprvResp" BU_SG_REL_ CGM_LE SG_ 2152775680 InvTrlrAx1CamYAlgnd 1;
BA_REL_ "GenSigSuprvResp" BU_SG_REL_ VCU_LE SG_ 2152775680 InvTrlrAx1CamXAlgnd 1;
BA_REL_ "GenSigSuprvResp" BU_SG_REL_ CSM_LE SG_ 2152775680 InvTrlrAx1CamXAlgnd 1;
BA_REL_ "GenSigSuprvResp" BU_SG_REL_ RadioHead_LE SG_ 2152775680 InvTrlrAx1CamXAlgnd 1;
BA_REL_ "GenSigRxStartValue" BU_SG_REL_ VCU_LE SG_ 2152775680 RPDCA_Resrv3Avail "0";
BA_REL_ "GenSigRxStartValue" BU_SG_REL_ CSM_LE SG_ 2152775680 RPDCA_Resrv3Avail "0";
BA_REL_ "GenSigRxStartValue" BU_SG_REL_ RadioHead_LE SG_ 2152775680 RPDCA_Resrv3Avail "0";
BA_REL_ "GenSigRxStartValue" BU_SG_REL_ VCU_LE SG_ 2152775680 RPDCA_Resrv2Avail "0";
BA_REL_ "GenSigRxStartValue" BU_SG_REL_ CSM_LE SG_ 2152775680 RPDCA_Resrv2Avail "0";
BA_REL_ "GenSigRxStartValue" BU_SG_REL_ RadioHead_LE SG_ 2152775680 RPDCA_Resrv2Avail "0";
BA_REL_ "GenSigRxStartValue" BU_SG_REL_ VCU_LE SG_ 2152775680 RPDCA_Resrv1Avail "0";
BA_REL_ "GenSigRxStartValue" BU_SG_REL_ CSM_LE SG_ 2152775680 RPDCA_Resrv1Avail "0";
BA_REL_ "GenSigRxStartValue" BU_SG_REL_ RadioHead_LE SG_ 2152775680 RPDCA_Resrv1Avail "0";
BA_REL_ "GenSigRxStartValue" BU_SG_REL_ VCU_LE SG_ 2152775680 RPDCA_AlrtBrkAvail "0";
BA_REL_ "GenSigRxStartValue" BU_SG_REL_ CSM_LE SG_ 2152775680 RPDCA_AlrtBrkAvail "0";
BA_REL_ "GenSigRxStartValue" BU_SG_REL_ RadioHead_LE SG_ 2152775680 RPDCA_AlrtBrkAvail "0";
BA_REL_ "GenSigRxStartValue" BU_SG_REL_ VCU_LE SG_ 2152775680 RPDCA_AlrtAvail "0";
BA_REL_ "GenSigRxStartValue" BU_SG_REL_ CSM_LE SG_ 2152775680 RPDCA_AlrtAvail "0";
BA_REL_ "GenSigRxStartValue" BU_SG_REL_ RadioHead_LE SG_ 2152775680 RPDCA_AlrtAvail "0";
BA_REL_ "GenSigRxStartValue" BU_SG_REL_ VCU_LE SG_ 2152775680 RPDCA_OnAvail "1";
BA_REL_ "GenSigRxStartValue" BU_SG_REL_ CSM_LE SG_ 2152775680 RPDCA_OnAvail "1";
BA_REL_ "GenSigRxStartValue" BU_SG_REL_ RadioHead_LE SG_ 2152775680 RPDCA_OnAvail "1";
BA_REL_ "GenSigRxStartValue" BU_SG_REL_ VCU_LE SG_ 2152775680 RPDCA_OfAvail "1";
BA_REL_ "GenSigRxStartValue" BU_SG_REL_ CSM_LE SG_ 2152775680 RPDCA_OfAvail "1";
BA_REL_ "GenSigRxStartValue" BU_SG_REL_ RadioHead_LE SG_ 2152775680 RPDCA_OfAvail "1";
BA_REL_ "GenSigSuprvResp" BU_SG_REL_ VCU_LE SG_ 2152775680 JacknfDetCustSetVal 1;
BA_REL_ "GenSigSuprvResp" BU_SG_REL_ CSM_LE SG_ 2152775680 JacknfDetCustSetVal 1;
BA_REL_ "GenSigSuprvResp" BU_SG_REL_ RadioHead_LE SG_ 2152775680 JacknfDetCustSetVal 1;
BA_REL_ "GenSigSuprvResp" BU_SG_REL_ VCU_LE SG_ 2152775680 JacknfDetCustSetAvl 1;
BA_REL_ "GenSigSuprvResp" BU_SG_REL_ CSM_LE SG_ 2152775680 JacknfDetCustSetAvl 1;
BA_REL_ "GenSigSuprvResp" BU_SG_REL_ RadioHead_LE SG_ 2152775680 JacknfDetCustSetAvl 1;
BA_REL_ "GenSigSuprvResp" BU_SG_REL_ VCU_LE SG_ 2152775680 CrgBdVwLtCustSetVal 1;
BA_REL_ "GenSigSuprvResp" BU_SG_REL_ CSM_LE SG_ 2152775680 CrgBdVwLtCustSetVal 1;
BA_REL_ "GenSigSuprvResp" BU_SG_REL_ RadioHead_LE SG_ 2152775680 CrgBdVwLtCustSetVal 1;
BA_REL_ "GenSigSuprvResp" BU_SG_REL_ VCU_LE SG_ 2152775680 DispTrgdVidOn 1;
BA_REL_ "GenSigSuprvResp" BU_SG_REL_ CSM_LE SG_ 2152775680 DispTrgdVidOn 1;
BA_REL_ "GenSigSuprvResp" BU_SG_REL_ RadioHead_LE SG_ 2152775680 DispTrgdVidOn 1;
BA_REL_ "GenSigSuprvResp" BU_SG_REL_ VCU_LE SG_ 2152775680 a_360DegVidFetrPrsnt 1;
BA_REL_ "GenSigSuprvResp" BU_SG_REL_ CSM_LE SG_ 2152775680 a_360DegVidFetrPrsnt 1;
BA_REL_ "GenSigSuprvResp" BU_SG_REL_ RadioHead_LE SG_ 2152775680 a_360DegVidFetrPrsnt 1;
BA_REL_ "GenSigSuprvResp" BU_SG_REL_ VCU_LE SG_ 2152775680 TrgdVidRecFetrPrsnt 1;
BA_REL_ "GenSigSuprvResp" BU_SG_REL_ CSM_LE SG_ 2152775680 TrgdVidRecFetrPrsnt 1;
BA_REL_ "GenSigSuprvResp" BU_SG_REL_ RadioHead_LE SG_ 2152775680 TrgdVidRecFetrPrsnt 1;
BA_REL_ "GenSigSuprvResp" BU_SG_REL_ VCU_LE SG_ 2152775680 DispFrt360CamOn 1;
BA_REL_ "GenSigSuprvResp" BU_SG_REL_ CSM_LE SG_ 2152775680 DispFrt360CamOn 1;
BA_REL_ "GenSigSuprvResp" BU_SG_REL_ RadioHead_LE SG_ 2152775680 DispFrt360CamOn 1;
BA_REL_ "GenSigSuprvResp" BU_SG_REL_ VCU_LE SG_ 2152775680 DispSmrtTwVidOn 1;
BA_REL_ "GenSigSuprvResp" BU_SG_REL_ CSM_LE SG_ 2152775680 DispSmrtTwVidOn 1;
BA_REL_ "GenSigSuprvResp" BU_SG_REL_ RadioHead_LE SG_ 2152775680 DispSmrtTwVidOn 1;
BA_REL_ "GenSigSuprvResp" BU_SG_REL_ VPM_LE SG_ 2149777408 WRSLNDWhlDisTpRC 1;
BA_REL_ "GenSigSuprvResp" BU_SG_REL_ VPM_LE SG_ 2149777408 WRSLNDWhlRotStRst 1;
BA_REL_ "GenSigSuprvResp" BU_SG_REL_ VPM_LE SG_ 2149777408 WRSLNDWhlDistVal 1;
BA_REL_ "GenSigSuprvResp" BU_SG_REL_ VPM_LE SG_ 2149777408 WRSLNDWhlDistTstm 1;
BA_REL_ "GenSigSuprvResp" BU_SG_REL_ VPM_LE SG_ 2149777408 WRSLNDWhlDistPCntr 1;
BA_REL_ "GenSigSuprvResp" BU_SG_REL_ VPM_LE SG_ 2149777408 WRSLNDSeqNum 1;
BA_REL_ "GenSigSuprvResp" BU_SG_REL_ VPM_LE SG_ 2149777408 WRSRNDWhlDisTpRC 1;
BA_REL_ "GenSigSuprvResp" BU_SG_REL_ VPM_LE SG_ 2149777408 WRSRNDWhlRotStRst 1;
BA_REL_ "GenSigSuprvResp" BU_SG_REL_ VPM_LE SG_ 2149777408 WRSRNDWhlDistVal 1;
BA_REL_ "GenSigSuprvResp" BU_SG_REL_ VPM_LE SG_ 2149777408 WRSRNDWhlDistTstm 1;
BA_REL_ "GenSigSuprvResp" BU_SG_REL_ VPM_LE SG_ 2149777408 WRSRNDWhlDistPCntr 1;
BA_REL_ "GenSigSuprvResp" BU_SG_REL_ VPM_LE SG_ 2149777408 WRSRNDSeqNum 1;
VAL_ 2155536384 RevClnMtgnBrkReqAct 1 "true" 0 "false" ;
VAL_ 2155536384 TnDrvRIMOffUnbIO 1 "true" 0 "false" ;
VAL_ 2155536384 RVBUnblIO 1 "true" 0 "false" ;
VAL_ 2155536384 RVBFldIO 1 "true" 0 "false" ;
VAL_ 2155536384 RVBEnbldIO 1 "true" 0 "false" ;
VAL_ 2155536384 RVBDsbldIO 1 "true" 0 "false" ;
VAL_ 2152742912 ShrtRngRdrOffIO 1 "true" 0 "false" ;
VAL_ 2152742912 RrRdrFldIO 1 "true" 0 "false" ;
VAL_ 2152742912 RrRdrBlckdIO 1 "true" 0 "false" ;
VAL_ 2152742912 RrEOCMMdlFldIO 1 "true" 0 "false" ;
VAL_ 2152685568 RadConInfReqSrc 2 "Infotainment Head" 1 "Rear Seat Entertainment" 0 "Voice Recognition System" ;
VAL_ 2152685568 RadBrdcstSrc 2 "FM" 1 "AM" 0 "Satellite Digital Audio Receiver" ;
VAL_ 2152685568 RadConInfCmd 3 "Purchase" 2 "Store" 1 "Mark" 0 "No Action" ;
VAL_ 2151235584 EhnSrvImmbComRst 1 "true" 0 "false" ;
VAL_ 2151235584 AlcKyIIncmIndOn 1 "true" 0 "false" ;
VAL_ 2151235584 VehSecAuthnSesComp 1 "true" 0 "false" ;
VAL_ 2151235584 VTDTmprDetected 1 "true" 0 "false" ;
VAL_ 2151235584 VehSecSysFldIO 1 "true" 0 "false" ;
VAL_ 2151235584 VehSecStrgColLckPwdV 1 "Invalid" 0 "Valid" ;
VAL_ 2151235584 VhSecNImmoIndRq 2 "Flashing Indication" 1 "Continuous Indication" 0 "No Indication" ;
VAL_ 2151235584 StrgColLckCmd 3 "Failure Code Retrieval Required" 2 "Lock" 1 "Unlock" 0 "No Command" ;
VAL_ 2151235584 DrIdDevLrnd 1 "Learned" 0 "Not Learned" ;
VAL_ 2151235584 IllDrIdDevDtctd 1 "true" 0 "false" ;
VAL_ 2151235584 EhnSrvEngImmStat 1 "Immobilized" 0 "Not Immobilized" ;
VAL_ 2151235584 ClmSysBkupFlrIndOn 1 "true" 0 "false" ;
VAL_ 2151235584 VehStatStAtv 1 "true" 0 "false" ;
VAL_ 2150776832 HybImpSnsDsbld 1 "true" 0 "false" ;
VAL_ 2150776832 SftyMuteRd 1 "true" 0 "false" ;
VAL_ 2150776832 HybVehHiVltInvDisRqd 1 "true" 0 "false" ;
VAL_ 2150776832 EvntEnbld 1 "true" 0 "false" ;
VAL_ 2150776832 ShfUlkBrToShftIndCtrl 1 "true" 0 "false" ;
VAL_ 2150776832 ShftLkdBuStbltIndCtrl 1 "true" 0 "false" ;
VAL_ 2150776832 SbItlkTrnsShftLvLkRd 1 "true" 0 "false" ;
VAL_ 2150776832 MmryRclImpctDisRq 1 "Disable Recall" 0 "Enable Recall" ;
VAL_ 2155347968 DrvrStPerfMdCsCrStVal 7 "Auto" 6 "Performance Mode 6" 5 "Performance Mode 5" 4 "Performance Mode 4" 3 "Performance Mode 3" 2 "Performance Mode 2" 1 "Performance Mode 1" 0 "No Action" ;
VAL_ 2155347968 DrvrStPerfMdCsStAvl 1 "true" 0 "false" ;
VAL_ 2155347968 ACCPerfMdCsCrStVal 7 "Auto" 6 "Performance Mode 6" 5 "Performance Mode 5" 4 "Performance Mode 4" 3 "Performance Mode 3" 2 "Performance Mode 2" 1 "Performance Mode 1" 0 "No Action" ;
VAL_ 2155347968 ACCPerfMdCsStAvl 1 "true" 0 "false" ;
VAL_ 2155347968 VehRollAngleV 1 "Invalid" 0 "Valid" ;
VAL_ 2155347968 ActVbnCtrlMlfIO 1 "true" 0 "false" ;
VAL_ 2155347968 HillDesCtrlRedVehSpIO 1 "true" 0 "false" ;
VAL_ 2155347968 FourWhlDrvIndReq 0 "No Indication" 1 "Indication 1" 2 "Indication 2" 3 "Indication 3" 4 "Indication 4" 5 "Indication 5" 6 "Indication 6" 7 "Indication 7" ;
VAL_ 2155347968 PedtrnProtVDA 1 "VirtualDeviceAvailable" 0 "VirtualDeviceUnavailable" ;
VAL_ 2155347968 EngRecDwnshftIO 1 "true" 0 "false" ;
VAL_ 2155347968 AppCltchAutSrtIO 1 "true" 0 "false" ;
VAL_ 2155347968 CPSUnblIO 1 "true" 0 "false" ;
VAL_ 2155347968 StBltTgtSetAvl 1 "true" 0 "false" ;
VAL_ 2155347968 StBltTgtCrtSetVal 0 "No Action" 1 "Low" 2 "Normal" 3 "Performance" 4 "Locked" ;
VAL_ 2155347968 PedtrnProtSysDisbld 1 "true" 0 "false" ;
VAL_ 2155347968 PedtrnProtSysDpl 1 "true" 0 "false" ;
VAL_ 2155347968 SrvPedtrnProtSysIO 1 "true" 0 "false" ;
VAL_ 2155347968 CPSOffIO 1 "true" 0 "false" ;
VAL_ 2155347968 SecAxlTmpInhIO 1 "true" 0 "false" ;
VAL_ 2155347968 CPSFldIO 1 "true" 0 "false" ;
VAL_ 2155347968 CPSAlrtOnlIO 1 "true" 0 "false" ;
VAL_ 2155347968 RrAxlTmpInhIO 1 "true" 0 "false" ;
VAL_ 2155347968 TirePrsLowIO 1 "true" 0 "false" ;
VAL_ 2155347968 EPBSysStatIndReq 3 "Flash Rate 2 Indication" 2 "Flash Rate 1 Indication" 1 "Continuous Indication" 0 "No Indication" ;
VAL_ 2155347968 EngOilStrvtnIO 1 "true" 0 "false" ;
VAL_ 2155347968 SrvSuspSysIO 1 "true" 0 "false" ;
VAL_ 2155347968 ServAdpCrsCtrlIndOn 1 "true" 0 "false" ;
VAL_ 2155347968 EngRecmndUpshftIO 1 "true" 0 "false" ;
VAL_ 2155347968 BrkSysMalFuncIndOn 1 "true" 0 "false" ;
VAL_ 2155347968 SecAxlNonEmMalfIO 1 "true" 0 "false" ;
VAL_ 2155347968 BrkFldLvlLw 1 "true" 0 "false" ;
VAL_ 2155347968 ACCUnavlbleDTWthrIO 1 "true" 0 "false" ;
VAL_ 2155347968 ACCTmpUnavlbleIO 1 "true" 0 "false" ;
VAL_ 2155347968 EngEmsRelMalfIndReq 4 "Flashing 0.5 Hertz Indication" 3 "Flashing 2 Hertz Indication" 2 "Flashing 1 Hertz Indication" 1 "No Indication" 0 "Continuous Indication" ;
VAL_ 2155347968 DrShftCntrlReqDndIO 1 "true" 0 "false" ;
VAL_ 2155347968 BrkPadWrnIO 1 "true" 0 "false" ;
VAL_ 2155347968 RrAxlMalfIO 1 "true" 0 "false" ;
VAL_ 2155347968 EPBSysWrnIndReq 3 "Flash Rate #2 Indication" 2 "Flash Rate #1 Indication" 1 "Continuous Indication" 0 "No Indication" ;
VAL_ 2155347968 CompOvrhtIndOn 1 "true" 0 "false" ;
VAL_ 2155347968 BrkFldLvlLwV 1 "Invalid" 0 "Valid" ;
VAL_ 2155347968 ACCSnsClnRqdIO 1 "true" 0 "false" ;
VAL_ 2155347968 TrnsSkpShftIO 1 "true" 0 "false" ;
VAL_ 2155585536 StBltTgtCSRq 0 "No Action" 1 "Low" 2 "Normal" 3 "Performance" 4 "Locked" ;
VAL_ 2153840640 TnDrvDRLOffUnbIO 1 "true" 0 "false" ;
VAL_ 2153840640 TnDrvALCOffUnbIO 1 "true" 0 "false" ;
VAL_ 2154094592 IntDimSeldClrTypStVal 31 "Color Type 30" 30 "Color Type 29" 29 "Color Type 28" 28 "Color Type 27" 27 "Color Type 26" 26 "Color Type 25" 25 "Color Type 24" 24 "Color Type 23" 23 "Color Type 22" 22 "Color Type 21" 21 "Color Type 20" 20 "Color Type 19" 19 "Color Type 18" 18 "Color Type 17" 17 "Color Type 16" 16 "Color Type 15" 15 "Color Type 14" 14 "Color Type 13" 13 "Color Type 12" 12 "Color Type 11" 11 "Color Type 10" 10 "Color Type 9" 9 "Color Type 8" 8 "Color Type 7" 7 "Color Type 6" 6 "Color Type 5" 5 "Color Type 4" 4 "Color Type 3" 3 "Color Type 2" 2 "Color Type 1" 1 "Off" 0 "No Action" ;
VAL_ 2154094592 IntDimSeldAnmTypStVal 15 "Animation Type 14" 14 "Animation Type 13" 13 "Animation Type 12" 12 "Animation Type 11" 11 "Animation Type 10" 10 "Animation Type 9" 9 "Animation Type 8" 8 "Animation Type 7" 7 "Animation Type 6" 6 "Animation Type 5" 5 "Animation Type 4" 4 "Animation Type 3" 3 "Animation Type 2" 2 "Animation Type 1" 1 "Off" 0 "No Action" ;
VAL_ 2154094592 IDCTA_ClrTyp30Avl 1 "true" 0 "false" ;
VAL_ 2154094592 IDCTA_ClrTyp29Avl 1 "true" 0 "false" ;
VAL_ 2154094592 IDCTA_ClrTyp28Avl 1 "true" 0 "false" ;
VAL_ 2154094592 IDCTA_ClrTyp27Avl 1 "true" 0 "false" ;
VAL_ 2154094592 IDCTA_ClrTyp26Avl 1 "true" 0 "false" ;
VAL_ 2154094592 IDCTA_ClrTyp25Avl 1 "true" 0 "false" ;
VAL_ 2154094592 IDCTA_ClrTyp24Avl 1 "true" 0 "false" ;
VAL_ 2154094592 IDCTA_ClrTyp23Avl 1 "true" 0 "false" ;
VAL_ 2154094592 IDCTA_ClrTyp22Avl 1 "true" 0 "false" ;
VAL_ 2154094592 IDCTA_ClrTyp21Avl 1 "true" 0 "false" ;
VAL_ 2154094592 IDCTA_ClrTyp20Avl 1 "true" 0 "false" ;
VAL_ 2154094592 IDCTA_ClrTyp19Avl 1 "true" 0 "false" ;
VAL_ 2154094592 IDCTA_ClrTyp18Avl 1 "true" 0 "false" ;
VAL_ 2154094592 IDCTA_ClrTyp17Avl 1 "true" 0 "false" ;
VAL_ 2154094592 IDCTA_ClrTyp16Avl 1 "true" 0 "false" ;
VAL_ 2154094592 IDCTA_ClrTyp15Avl 1 "true" 0 "false" ;
VAL_ 2154094592 IDCTA_ClrTyp14Avl 1 "true" 0 "false" ;
VAL_ 2154094592 IDCTA_ClrTyp13Avl 1 "true" 0 "false" ;
VAL_ 2154094592 IDCTA_ClrTyp12Avl 1 "true" 0 "false" ;
VAL_ 2154094592 IDCTA_ClrTyp11Avl 1 "true" 0 "false" ;
VAL_ 2154094592 IDCTA_ClrTyp10Avl 1 "true" 0 "false" ;
VAL_ 2154094592 IDCTA_ClrTyp9Avl 1 "true" 0 "false" ;
VAL_ 2154094592 IDCTA_ClrTyp8Avl 1 "true" 0 "false" ;
VAL_ 2154094592 IDCTA_ClrTyp7Avl 1 "true" 0 "false" ;
VAL_ 2154094592 IDCTA_ClrTyp6Avl 1 "true" 0 "false" ;
VAL_ 2154094592 IDCTA_ClrTyp5Avl 1 "true" 0 "false" ;
VAL_ 2154094592 IDCTA_ClrTyp4Avl 1 "true" 0 "false" ;
VAL_ 2154094592 IDCTA_ClrTyp3Avl 1 "true" 0 "false" ;
VAL_ 2154094592 IDCTA_ClrTyp2Avl 1 "true" 0 "false" ;
VAL_ 2154094592 IDCTA_ClrTyp1Avl 1 "true" 0 "false" ;
VAL_ 2154094592 IDCTA_OffAvl 1 "true" 0 "false" ;
VAL_ 2154094592 IDATA_AnmTyp14Avl 1 "true" 0 "false" ;
VAL_ 2154094592 IDATA_AnmTyp13Avl 1 "true" 0 "false" ;
VAL_ 2154094592 IDATA_AnmTyp12Avl 1 "true" 0 "false" ;
VAL_ 2154094592 IDATA_AnmTyp11Avl 1 "true" 0 "false" ;
VAL_ 2154094592 IDATA_AnmTyp10Avl 1 "true" 0 "false" ;
VAL_ 2154094592 IDATA_AnmTyp9Avl 1 "true" 0 "false" ;
VAL_ 2154094592 IDATA_AnmTyp8Avl 1 "true" 0 "false" ;
VAL_ 2154094592 IDATA_AnmTyp7Avl 1 "true" 0 "false" ;
VAL_ 2154094592 IDATA_AnmTyp6Avl 1 "true" 0 "false" ;
VAL_ 2154094592 IDATA_AnmTyp5Avl 1 "true" 0 "false" ;
VAL_ 2154094592 IDATA_AnmTyp4Avl 1 "true" 0 "false" ;
VAL_ 2154094592 IDATA_AnmTyp3Avl 1 "true" 0 "false" ;
VAL_ 2154094592 IDATA_AnmTyp2Avl 1 "true" 0 "false" ;
VAL_ 2154094592 IDATA_AnmTyp1Avl 1 "true" 0 "false" ;
VAL_ 2154094592 IDATA_OffAvl 1 "true" 0 "false" ;
VAL_ 2154094592 AdjPdlMotInhbtd 1 "true" 0 "false" ;
VAL_ 2154061824 WndOprAlwd 1 "true" 0 "false" ;
VAL_ 2154061824 RrDrUnlckIO 1 "true" 0 "false" ;
VAL_ 2154061824 RmtWndMvmntAtv 1 "true" 0 "false" ;
VAL_ 2154061824 RRWndNtNrmIndOn 1 "true" 0 "false" ;
VAL_ 2154061824 RLWndNtNrmIndOn 1 "true" 0 "false" ;
VAL_ 2154061824 DrWndNtNrmIndOn 1 "true" 0 "false" ;
VAL_ 2154061824 PsWndNtNrmIndOn 1 "true" 0 "false" ;
VAL_ 2155036672 ACCompModReq 3 "No Action" 2 "Engage" 1 "Disengage" 0 "Disengage Immediately" ;
VAL_ 2155036672 ACCompNormLdV 1 "Invalid" 0 "Valid" ;
VAL_ 2155036672 ACCmEngRunReq 1 "Engine Run Requested" 0 "No Action" ;
VAL_ 2155036672 ACCmpsrFldOn 1 "true" 0 "false" ;
VAL_ 2151112704 FrPasSeatbltRemOccSt 1 "Occupied" 0 "Empty" ;
VAL_ 2151112704 FrPasSeatResCtrlOccStV 1 "Invalid" 0 "Valid" ;
VAL_ 2151112704 FrPasSeatResCtrlOccSt 2 "Occupied" 1 "Empty" 0 "Unknown" ;
VAL_ 2151112704 FrPsSeatOccSnsOpMd 3 "SystemInitMod" 2 "BarrierMod" 1 "ZeroSetCheckMod" 0 "FieldMod" ;
VAL_ 2151112704 FrPsSeatOccFltSt 2 "Fault Present - Vehicle Mismatch" 1 "Fault Present" 0 "No Faults Present" ;
VAL_ 2151112704 FrntPassClass 7 "Large Adult" 6 "Small Adult" 5 "Large Child" 4 "Small Child" 3 "Child Seat Unknown" 2 "Child Seat Forward" 1 "Child Seat Rearward" 0 "Classification Not Applicable" ;
VAL_ 2150301696 WlcAnmReq 1 "true" 0 "false" ;
VAL_ 2151350272 APAIconDispRq 7 "Unused & Reserved" 6 "Unused & Reserved" 5 "Unused & Reserved" 4 "Complete" 3 "Stop" 2 "Reverse" 1 "Forward" 0 "No Icon" ;
VAL_ 2151317504 PrkAstRrSysStat 3 "Failed" 2 "Inhibited" 1 "Enabled" 0 "Disabled" ;
VAL_ 2151317504 PARrRgn4ObjStat 15 "Zone 15" 14 "Zone 14" 13 "Zone 13" 12 "Zone 12" 11 "Zone 11" 10 "Zone 10" 9 "Zone 9" 8 "Zone 8" 7 "Zone 7" 6 "Zone 6" 5 "Zone 5" 4 "Zone 4" 3 "Zone 3" 2 "Zone 2" 1 "Zone 1" 0 "No Object" ;
VAL_ 2151317504 PARrRgn3ObjStat 15 "Zone 15" 14 "Zone 14" 13 "Zone 13" 12 "Zone 12" 11 "Zone 11" 10 "Zone 10" 9 "Zone 9" 8 "Zone 8" 7 "Zone 7" 6 "Zone 6" 5 "Zone 5" 4 "Zone 4" 3 "Zone 3" 2 "Zone 2" 1 "Zone 1" 0 "No Object" ;
VAL_ 2151317504 PARrRgn2ObjStat 15 "Zone 15" 14 "Zone 14" 13 "Zone 13" 12 "Zone 12" 11 "Zone 11" 10 "Zone 10" 9 "Zone 9" 8 "Zone 8" 7 "Zone 7" 6 "Zone 6" 5 "Zone 5" 4 "Zone 4" 3 "Zone 3" 2 "Zone 2" 1 "Zone 1" 0 "No Object" ;
VAL_ 2151317504 PARrRgn1ObjStat 15 "Zone 15" 14 "Zone 14" 13 "Zone 13" 12 "Zone 12" 11 "Zone 11" 10 "Zone 10" 9 "Zone 9" 8 "Zone 8" 7 "Zone 7" 6 "Zone 6" 5 "Zone 5" 4 "Zone 4" 3 "Zone 3" 2 "Zone 2" 1 "Zone 1" 0 "No Object" ;
VAL_ 2151301120 PrkAstAdvSysAct 1 "true" 0 "false" ;
VAL_ 2151301120 PrkAstFrSysStat 3 "Failed" 2 "Inhibited" 1 "Enabled" 0 "Disabled" ;
VAL_ 2151301120 PAFrtRgn4ObjStat 15 "Zone 15" 14 "Zone 14" 13 "Zone 13" 12 "Zone 12" 11 "Zone 11" 10 "Zone 10" 9 "Zone 9" 8 "Zone 8" 7 "Zone 7" 6 "Zone 6" 5 "Zone 5" 4 "Zone 4" 3 "Zone 3" 2 "Zone 2" 1 "Zone 1" 0 "No Object" ;
VAL_ 2151301120 PAFrtRgn3ObjStat 15 "Zone 15" 14 "Zone 14" 13 "Zone 13" 12 "Zone 12" 11 "Zone 11" 10 "Zone 10" 9 "Zone 9" 8 "Zone 8" 7 "Zone 7" 6 "Zone 6" 5 "Zone 5" 4 "Zone 4" 3 "Zone 3" 2 "Zone 2" 1 "Zone 1" 0 "No Object" ;
VAL_ 2151301120 PAFrtRgn2ObjStat 15 "Zone 15" 14 "Zone 14" 13 "Zone 13" 12 "Zone 12" 11 "Zone 11" 10 "Zone 10" 9 "Zone 9" 8 "Zone 8" 7 "Zone 7" 6 "Zone 6" 5 "Zone 5" 4 "Zone 4" 3 "Zone 3" 2 "Zone 2" 1 "Zone 1" 0 "No Object" ;
VAL_ 2151301120 PAFrtRgn1ObjStat 15 "Zone 15" 14 "Zone 14" 13 "Zone 13" 12 "Zone 12" 11 "Zone 11" 10 "Zone 10" 9 "Zone 9" 8 "Zone 8" 7 "Zone 7" 6 "Zone 6" 5 "Zone 5" 4 "Zone 4" 3 "Zone 3" 2 "Zone 2" 1 "Zone 1" 0 "No Object" ;
VAL_ 2151301120 PrkAsstRrOffIO 1 "true" 0 "false" ;
VAL_ 2152775680 CrgBdVwLtCustSetAvl 1 "true" 0 "false" ;
VAL_ 2152775680 TrlrMirVGlnCustSetVal 3 "Unused and Reserved" 2 "On" 1 "Off" 0 "Unknown" ;
VAL_ 2152775680 TrlrMirVGlnCustSetAvl 1 "true" 0 "false" ;
VAL_ 2152775680 TrlrMirVEnCustSetVal 3 "Unused and Reserved" 2 "On" 1 "Off" 0 "Unknown" ;
VAL_ 2152775680 TrlrMirVEnCustSetAvl 1 "true" 0 "false" ;
VAL_ 2152775680 TrlrArtcltnAnglCalStat 3 "Unavailable" 2 "Degraded" 1 "Available" 0 "Unknown" ;
VAL_ 2152775680 InvTrlrAx1CamRollAlgnd 1 "true" 0 "false" ;
VAL_ 2152775680 InvTrlrAx1CamPtchAlgnd 1 "true" 0 "false" ;
VAL_ 2152775680 InvTrlrAx1CamYAlgnd 1 "true" 0 "false" ;
VAL_ 2152775680 InvTrlrAx1CamXAlgnd 1 "true" 0 "false" ;
VAL_ 2152775680 RPDCA_Resrv3Avail 1 "true" 0 "false" ;
VAL_ 2152775680 RPDCA_Resrv2Avail 1 "true" 0 "false" ;
VAL_ 2152775680 RPDCA_Resrv1Avail 1 "true" 0 "false" ;
VAL_ 2152775680 RPDCA_AlrtBrkAvail 1 "true" 0 "false" ;
VAL_ 2152775680 RPDCA_AlrtAvail 1 "true" 0 "false" ;
VAL_ 2152775680 RPDCA_OnAvail 1 "true" 0 "false" ;
VAL_ 2152775680 RPDCA_OfAvail 1 "true" 0 "false" ;
VAL_ 2152775680 JacknfDetCustSetVal 3 "Unused and Reserved" 2 "On" 1 "Off" 0 "Unknown" ;
VAL_ 2152775680 JacknfDetCustSetAvl 1 "true" 0 "false" ;
VAL_ 2152775680 CrgBdVwLtCustSetVal 3 "Unused and Reserved" 2 "On" 1 "Off" 0 "Unknown" ;
VAL_ 2152775680 DispTrgdVidOn 1 "true" 0 "false" ;
VAL_ 2152775680 a_360DegVidFetrPrsnt 1 "true" 0 "false" ;
VAL_ 2152775680 TrgdVidRecFetrPrsnt 1 "true" 0 "false" ;
VAL_ 2152775680 RrPedDetCstStAvl 1 "true" 0 "false" ;
VAL_ 2152775680 RrPedDetCstStVal 7 "Reserved3" 6 "Reserved2" 5 "Reserved1" 4 "Alert and Brake" 3 "Alert" 2 "On" 1 "Off" 0 "No Action" ;
VAL_ 2152775680 DispFrt360CamOn 1 "true" 0 "false" ;
VAL_ 2152775680 SurdVwLightgCsSetAvail 1 "true" 0 "false" ;
VAL_ 2152775680 SurdVwLightgCsCurrSetVal 7 "Unused and Reserved 5" 6 "Unused and Reserved 4" 5 "Unused and Reserved 3" 4 "Unused and Reserved 2" 3 "Unused and Reserved 1" 2 "ON" 1 "OFF" 0 "No Action" ;
VAL_ 2152775680 PudlLmpReqstd 1 "true" 0 "false" ;
VAL_ 2152775680 DispSmrtTwVidOn 1 "true" 0 "false" ;
VAL_ 2149777408 WRSLNDWhlRotStRst 1 "true" 0 "false" ;
VAL_ 2149777408 WRSLNDWhlDistVal 1 "Invalid" 0 "Valid" ;
VAL_ 2149777408 WRSRNDWhlRotStRst 1 "true" 0 "false" ;
VAL_ 2149777408 WRSRNDWhlDistVal 1 "Invalid" 0 "Valid" ;
VAL_ 2152153088 RRSCDS_DispReq 1 "true" 0 "false" ;
VAL_ 2152153088 RRSCDS_DispSz 2 "Small Size" 1 "Medium Size" 0 "Full Size" ;
VAL_ 2152153088 RRSCDS_CshLgAdjFdRr 3 "Rearward" 2 "Forward" 1 "Selected - No Movement " 0 "Not Selected" ;
VAL_ 2152153088 RRSCDS_BkCshBlstInOt 5 "Cushion Bolster Out" 4 "Cushion Bolster In" 3 "Back Bolster Out" 2 "Back Bolster In" 1 "Selected - No Movement" 0 "Not Selected" ;
VAL_ 2152153088 RRSCDS_CshBlstrInOut 3 "Out" 2 "In" 1 "Selected - No Movement" 0 "Not Selected" ;
VAL_ 2152153088 RRSCDS_BkBlstrInOut 3 "Out" 2 "In" 1 "Selected - No Movement" 0 "Not Selected" ;
VAL_ 2152153088 RRSCDS_LmbrUDnFdRr 5 "Rearward" 4 "Forward" 3 "Down" 2 "Up" 1 "Selected - No Movement " 0 "Not Selected" ;
VAL_ 2152153088 RRSCDS_LmbrFwdRr 3 "Rearward" 2 "Forward" 1 "Selected - No Movement " 0 "Not Selected" ;
VAL_ 2152153088 RRSCDS_LmbrUpDwn 3 "Down" 2 "Up" 1 "Selected - No Movement" 0 "Not Selected" ;
VAL_ 2152153088 RRSCDS_UprShldrFdRr 3 "Rearward" 2 "Forward" 1 "Selected - No Movement " 0 "Not Selected" ;
VAL_ 2152153088 RRSCDS_HdrstTltFwdRr 3 "Rearward" 2 "Forward" 1 "Selected - No Movement " 0 "Not Selected" ;
VAL_ 2152153088 RRSCDS_HdrstWngInOt 3 "Out" 2 "In" 1 "Selected - No Movement" 0 "Not Selected" ;
VAL_ 2152153088 RRSCDS_HdrstFdRrUDn 5 "Rearward" 4 "Forward" 3 "Down" 2 "Up" 1 "Selected - No Movement " 0 "Not Selected" ;
VAL_ 2152153088 RRSCDS_HdrstFwdRrwd 3 "Rearward" 2 "Forward" 1 "Selected - No Movement " 0 "Not Selected" ;
VAL_ 2152153088 RRSCDS_HdrstUpDn 3 "Down" 2 "Up" 1 "Selected - No Movement" 0 "Not Selected" ;
VAL_ 2152153088 RRSCDS_MassgIntsty 7 "Massage Intensity 7" 6 "Massage Intensity 6" 5 "Massage Intensity 5" 4 "Massage Intensity 4" 3 "Massage Intensity 3" 2 "Massage Intensity 2" 1 "Massage Intensity 1" 0 "Massage Off" ;
VAL_ 2152153088 RRSCDS_MassgTyp 15 "Massage Type 15" 14 "Massage Type 14" 13 "Massage Type 13" 12 "Massage Type 12" 11 "Massage Type 11" 10 "Massage Type 10" 9 "Massage Type 9" 8 "Massage Type 8" 7 "Massage Type 7" 6 "Massage Type 6" 5 "Massage Type 5" 4 "Massage Type 4" 3 "Massage Type 3" 2 "Massage Type 2" 1 "Massage Type 1" 0 "Massage Off" ;
VAL_ 2152153088 RRSCDS_Massg 2 "Selected Massage On" 1 "Selected Massage Off" 0 "Not Selected" ;
VAL_ 2152136704 RRSMP_UnsdRsrvd 1 "true" 0 "false" ;
VAL_ 2155151360 PSMP_UnsdRsrvd 1 "true" 0 "false" ;
VAL_ 2155134976 PSCDS_DispReq 1 "true" 0 "false" ;
VAL_ 2155134976 PSCDS_DispSz 3 "Reserved" 2 "Small Size" 1 "Medium Size" 0 "Full Size" ;
VAL_ 2155134976 PSCDS_CshLgAdjFdRr 3 "Rearward" 2 "Forward" 1 "Selected - No Movement" 0 "Not Selected" ;
VAL_ 2155134976 PSCDS_BkCshBlstInOt 5 "Cushion Bolster Out" 4 "Cushion Bolster In" 3 "Back Bolster Out" 2 "Back Bolster In" 1 "Selected - No Movement" 0 "Not Selected" ;
VAL_ 2155134976 PSCDS_CshBlstrInOut 3 "Out" 2 "In" 1 "Selected - No Movement" 0 "Not Selected" ;
VAL_ 2155134976 PSCDS_BkBlstrInOut 3 "Out" 2 "In" 1 "Selected - No Movement" 0 "Not Selected" ;
VAL_ 2155134976 PSCDS_LmbrUDnFdRr 5 "Rearward" 4 "Forward" 3 "Down" 2 "Up" 1 "Selected - No Movement" 0 "Not Selected" ;
VAL_ 2155134976 PSCDS_LmbrFwdRr 3 "Rearward" 2 "Forward" 1 "Selected - No Movement" 0 "Not Selected" ;
VAL_ 2155134976 PSCDS_LmbrUpDwn 3 "Down" 2 "Up" 1 "Selected - No Movement" 0 "Not Selected" ;
VAL_ 2155134976 PSCDS_UprShldrFdRr 3 "Rearward" 2 "Forward" 1 "Selected - No Movement" 0 "Not Selected" ;
VAL_ 2155134976 PSCDS_HdrstTltFwdRr 3 "Rearward" 2 "Forward" 1 "Selected - No Movement" 0 "Not Selected" ;
VAL_ 2155134976 PSCDS_HdrstWngInOt 3 "Out" 2 "In" 1 "Selected - No Movement" 0 "Not Selected" ;
VAL_ 2155134976 PSCDS_HdrstUDnFdRr 5 "Rearward" 4 "Forward" 3 "Down" 2 "Up" 1 "Selected - No Movement" 0 "Not Selected" ;
VAL_ 2155134976 PSCDS_HdrstFwdRrwd 3 "Rearward" 2 "Forward" 1 "Selected - No Movement" 0 "Not Selected" ;
VAL_ 2155134976 PSCDS_HdrstUpDn 3 "Down" 2 "Up" 1 "Selected - No Movement" 0 "Not Selected" ;
VAL_ 2155134976 PSCDS_MassgIntsty 7 "Massage Intensity 7" 6 "Massage Intensity 6" 5 "Massage Intensity 5" 4 "Massage Intensity 4" 3 "Massage Intensity 3" 2 "Massage Intensity 2" 1 "Massage Intensity 1" 0 "Massage Off" ;
VAL_ 2155134976 PSCDS_MassgTyp 15 "Massage Type 15" 14 "Massage Type 14" 13 "Massage Type 13" 12 "Massage Type 12" 11 "Massage Type 11" 10 "Massage Type 10" 9 "Massage Type 9" 8 "Massage Type 8" 7 "Massage Type 7" 6 "Massage Type 6" 5 "Massage Type 5" 4 "Massage Type 4" 3 "Massage Type 3" 2 "Massage Type 2" 1 "Massage Type 1" 0 "Massage Off" ;
VAL_ 2155134976 PSCDS_Massg 2 "Selected Massage On" 1 "Selected Massage Off" 0 "Not Selected" ;
VAL_ 2155134976 PsngrSetRrwdMvmnt 7 "Supervised Seat Recline Rearward" 6 "Supervised Seat Rear Down" 5 "Supervised Seat Rearward" 4 "Button Memory 1 and 2 EXIT Recall" 3 "Supervised Memory Recall" 2 "Auto Easy Exit Recall" 1 "Auto Recall At Ignition On" 0 "No Auto Or Rearward Movement" ;
SIG_GROUP_ 2154094592 IntDimClrTypAvl 1 : IDCTA_ClrTyp30Avl IDCTA_ClrTyp29Avl IDCTA_ClrTyp28Avl IDCTA_ClrTyp27Avl IDCTA_ClrTyp26Avl IDCTA_ClrTyp25Avl IDCTA_ClrTyp24Avl IDCTA_ClrTyp23Avl IDCTA_ClrTyp22Avl IDCTA_ClrTyp21Avl IDCTA_ClrTyp20Avl IDCTA_ClrTyp19Avl IDCTA_ClrTyp18Avl IDCTA_ClrTyp17Avl IDCTA_ClrTyp16Avl IDCTA_ClrTyp15Avl IDCTA_ClrTyp14Avl IDCTA_ClrTyp13Avl IDCTA_ClrTyp12Avl IDCTA_ClrTyp11Avl IDCTA_ClrTyp10Avl IDCTA_ClrTyp9Avl IDCTA_ClrTyp8Avl IDCTA_ClrTyp7Avl IDCTA_ClrTyp6Avl IDCTA_ClrTyp5Avl IDCTA_ClrTyp4Avl IDCTA_ClrTyp3Avl IDCTA_ClrTyp2Avl IDCTA_ClrTyp1Avl IDCTA_OffAvl;
SIG_GROUP_ 2154094592 IntDimAnmTypAvl 1 : IDATA_AnmTyp14Avl IDATA_AnmTyp13Avl IDATA_AnmTyp12Avl IDATA_AnmTyp11Avl IDATA_AnmTyp10Avl IDATA_AnmTyp9Avl IDATA_AnmTyp8Avl IDATA_AnmTyp7Avl IDATA_AnmTyp6Avl IDATA_AnmTyp5Avl IDATA_AnmTyp4Avl IDATA_AnmTyp3Avl IDATA_AnmTyp2Avl IDATA_AnmTyp1Avl IDATA_OffAvl;
SIG_GROUP_ 2152775680 RrPedDetCstAvail 1 : RPDCA_Resrv3Avail RPDCA_Resrv2Avail RPDCA_Resrv1Avail RPDCA_AlrtBrkAvail RPDCA_AlrtAvail RPDCA_OnAvail RPDCA_OfAvail;
SIG_GROUP_ 2149777408 WhlRotStatLftNDrvn 1 : WRSLNDWhlDisTpRC WRSLNDWhlRotStRst WRSLNDWhlDistVal WRSLNDWhlDistTstm WRSLNDWhlDistPCntr WRSLNDSeqNum;
SIG_GROUP_ 2149777408 WhlRotStatRghtNDrvn 1 : WRSRNDWhlDisTpRC WRSRNDWhlRotStRst WRSRNDWhlDistVal WRSRNDWhlDistTstm WRSRNDWhlDistPCntr WRSRNDSeqNum;
SIG_GROUP_ 2155069440 DrvStActPrty 1 : DSAP_UnsdRsrvd DSAP_DispSz DSAP_CshLgthAdjFdRr DSAP_BkCshBlstrInOut DSAP_CshBlstrInOut DSAP_BkBlstrInOut DSAP_LmbrUpDnFdRr DSAP_LmbrFwdRr DSAP_LmbrUpDwn DSAP_UprShldrFwdRr DSAP_HdrstTltFwdRr DSAP_HdrstWngsInOut DSAP_HdrstUpDnFdRr DSAP_HdrstFwdRrwd DSAP_HdrstUpDn DSAP_Massg;
SIG_GROUP_ 2152153088 RRStCtlDispStat 1 : RRSCDS_UnsdRsrvd RRSCDS_DispReq RRSCDS_DispSz RRSCDS_CshLgAdjFdRr RRSCDS_BkCshBlstInOt RRSCDS_CshBlstrInOut RRSCDS_BkBlstrInOut RRSCDS_LmbrUDnFdRr RRSCDS_LmbrFwdRr RRSCDS_LmbrUpDwn RRSCDS_UprShldrFdRr RRSCDS_HdrstTltFwdRr RRSCDS_HdrstWngInOt RRSCDS_HdrstFdRrUDn RRSCDS_HdrstFwdRrwd RRSCDS_HdrstUpDn RRSCDS_MassgIntsty RRSCDS_MassgTyp RRSCDS_Massg;
SIG_GROUP_ 2152136704 RRStMassgPrty 1 : RRSMP_UnsdRsrvd RRSMP_MaxDispVal RRSMP_Type15 RRSMP_Type14 RRSMP_Type13 RRSMP_Type12 RRSMP_Type11 RRSMP_Type10 RRSMP_Type9 RRSMP_Type8 RRSMP_Type7 RRSMP_Type6 RRSMP_Type5 RRSMP_Type4 RRSMP_Type3 RRSMP_Type2 RRSMP_Type1;
SIG_GROUP_ 2155151360 PsngrStMassgPrty 1 : PSMP_UnsdRsrvd PSMP_MaxDispVal PSMP_Type15 PSMP_Type14 PSMP_Type13 PSMP_Type12 PSMP_Type11 PSMP_Type10 PSMP_Type9 PSMP_Type8 PSMP_Type7 PSMP_Type6 PSMP_Type5 PSMP_Type4 PSMP_Type3 PSMP_Type2 PSMP_Type1;
SIG_GROUP_ 2155134976 PsngrStCtlDispStat 1 : PSCDS_UnsdRsrvd PSCDS_DispReq PSCDS_DispSz PSCDS_CshLgAdjFdRr PSCDS_BkCshBlstInOt PSCDS_CshBlstrInOut PSCDS_BkBlstrInOut PSCDS_LmbrUDnFdRr PSCDS_LmbrFwdRr PSCDS_LmbrUpDwn PSCDS_UprShldrFdRr PSCDS_HdrstTltFwdRr PSCDS_HdrstWngInOt PSCDS_HdrstUDnFdRr PSCDS_HdrstFwdRrwd PSCDS_HdrstUpDn PSCDS_MassgIntsty PSCDS_MassgTyp PSCDS_Massg;
SIG_GROUP_ 2155118592 PsngrStActPrty 1 : PSAP_UnsdRsrvd PSAP_DispSz PSAP_CshLgthAdjFdRr PSAP_CshBlstrInOut PSAP_BkBlstrInOut PSAP_BkCshBlstrInOut PSAP_LmbrUpDnFdRr PSAP_LmbrFwdRr PSAP_LmbrUpDwn PSAP_UprShldrFwdRr PSAP_HdrstTltFwdRr PSAP_HdrstWngsInOut PSAP_HdrstUpDnFdRr PSAP_HdrstFwdRrwd PSAP_HdrstUpDn PSAP_Massg;
